VERSION ""

NS_ :

BS_:

BU_: VMCU TECU OBDScanT2 IC3 HPCU EMS ECUspare2 ECUspare1 DACU CIOM BBM

BO_ 2671835728 XCP_FA_50_BB2: 8 DACU
 SG_ XCP_FA_50 : 0|64@1+ (1,0) [0|0] "" Vector__XXX

BO_ 2671792378 XCP_50_FA_BB2: 8 Vector__XXX
 SG_ XCP_50_FA : 0|64@1+ (1,0) [0|0] ""  DACU

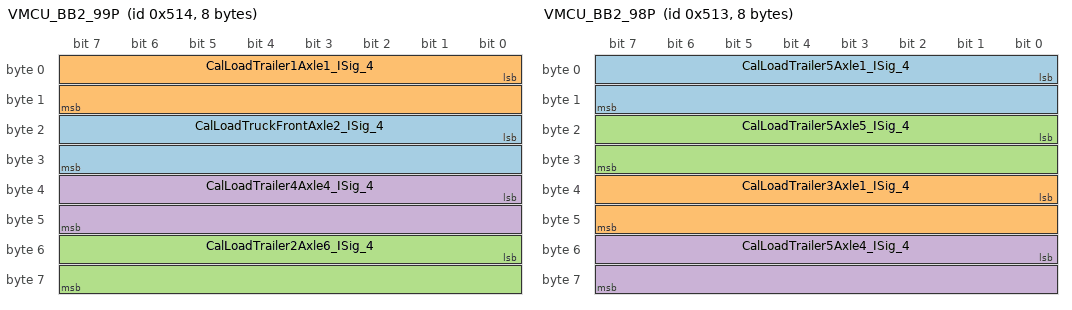
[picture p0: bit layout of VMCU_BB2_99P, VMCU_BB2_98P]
BO_ 1300 VMCU_BB2_99P: 8 VMCU
 SG_ CalLoadTruckFrontAxle2_ISig_4 : 16|16@1+ (0.5,0) [0|32767.5] "kg"  IC3,CIOM,BBM
 SG_ CalLoadTrailer1Axle1_ISig_4 : 0|16@1+ (0.5,0) [0|32767.5] "kg"  CIOM,BBM,IC3
 SG_ CalLoadTrailer2Axle6_ISig_4 : 48|16@1+ (0.5,0) [0|32767.5] "kg"  IC3,CIOM
 SG_ CalLoadTrailer4Axle4_ISig_4 : 32|16@1+ (0.5,0) [0|32767.5] "kg"  CIOM,IC3

BO_ 1299 VMCU_BB2_98P: 8 VMCU
 SG_ CalLoadTrailer5Axle1_ISig_4 : 0|16@1+ (0.5,0) [0|32767.5] "kg"  IC3,CIOM
 SG_ CalLoadTrailer3Axle1_ISig_4 : 32|16@1+ (0.5,0) [0|32767.5] "kg"  CIOM,IC3
 SG_ CalLoadTrailer5Axle5_ISig_4 : 16|16@1+ (0.5,0) [0|32767.5] "kg"  CIOM,IC3
 SG_ CalLoadTrailer5Axle4_ISig_4 : 48|16@1+ (0.5,0) [0|32767.5] "kg"  IC3,CIOM

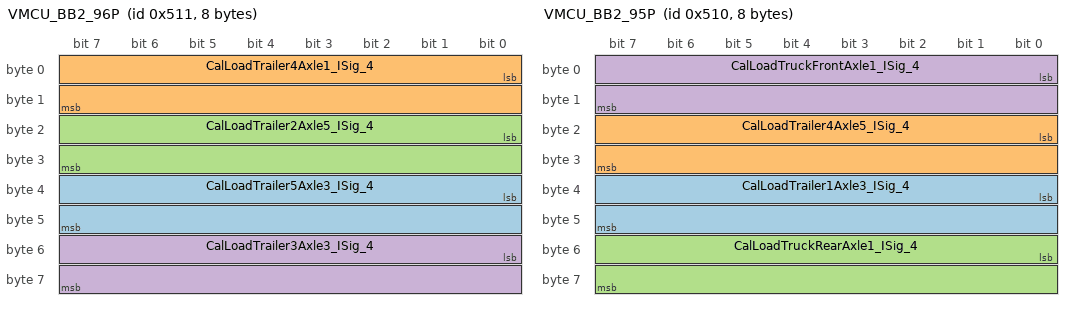
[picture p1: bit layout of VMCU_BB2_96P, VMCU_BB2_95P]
BO_ 1297 VMCU_BB2_96P: 8 VMCU
 SG_ CalLoadTrailer5Axle3_ISig_4 : 32|16@1+ (0.5,0) [0|32767.5] "kg"  CIOM,IC3
 SG_ CalLoadTrailer4Axle1_ISig_4 : 0|16@1+ (0.5,0) [0|32767.5] "kg"  CIOM,IC3
 SG_ CalLoadTrailer2Axle5_ISig_4 : 16|16@1+ (0.5,0) [0|32767.5] "kg"  CIOM,IC3
 SG_ CalLoadTrailer3Axle3_ISig_4 : 48|16@1+ (0.5,0) [0|32767.5] "kg"  CIOM,IC3

BO_ 1296 VMCU_BB2_95P: 8 VMCU
 SG_ CalLoadTrailer1Axle3_ISig_4 : 32|16@1+ (0.5,0) [0|32767.5] "kg"  IC3,BBM,CIOM
 SG_ CalLoadTrailer4Axle5_ISig_4 : 16|16@1+ (0.5,0) [0|32767.5] "kg"  IC3,CIOM
 SG_ CalLoadTruckRearAxle1_ISig_4 : 48|16@1+ (0.5,0) [0|32767.5] "kg"  CIOM,BBM,IC3
 SG_ CalLoadTruckFrontAxle1_ISig_4 : 0|16@1+ (0.5,0) [0|32767.5] "kg"  IC3,BBM,CIOM

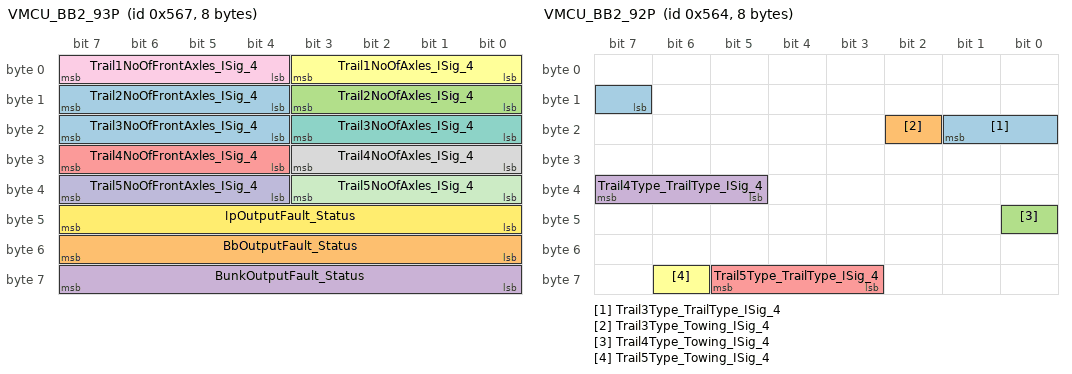
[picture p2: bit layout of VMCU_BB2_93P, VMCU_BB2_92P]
BO_ 1383 VMCU_BB2_93P: 8 VMCU
 SG_ Trail2NoOfFrontAxles_ISig_4 : 12|4@1+ (1,0) [0|15] "NotApplicable"  CIOM,IC3
 SG_ BbOutputFault_Status : 48|8@1+ (1,0) [0|255] ""  IC3
 SG_ Trail2NoOfAxles_ISig_4 : 8|4@1+ (1,0) [0|15] "NotApplicable"  IC3,CIOM
 SG_ BunkOutputFault_Status : 56|8@1+ (1,0) [0|255] ""  IC3
 SG_ Trail4NoOfFrontAxles_ISig_4 : 28|4@1+ (1,0) [0|15] "NotApplicable"  CIOM,IC3
 SG_ Trail1NoOfAxles_ISig_4 : 0|4@1+ (1,0) [0|15] "NotApplicable"  CIOM,IC3
 SG_ Trail3NoOfAxles_ISig_4 : 16|4@1+ (1,0) [0|15] "NotApplicable"  IC3,CIOM
 SG_ Trail4NoOfAxles_ISig_4 : 24|4@1+ (1,0) [0|15] "NotApplicable"  IC3,CIOM
 SG_ Trail1NoOfFrontAxles_ISig_4 : 4|4@1+ (1,0) [0|15] "NotApplicable"  IC3,CIOM
 SG_ Trail5NoOfFrontAxles_ISig_4 : 36|4@1+ (1,0) [0|15] "NotApplicable"  CIOM,IC3
 SG_ Trail5NoOfAxles_ISig_4 : 32|4@1+ (1,0) [0|15] "NotApplicable"  CIOM,IC3
 SG_ IpOutputFault_Status : 40|8@1+ (1,0) [0|255] ""  IC3
 SG_ Trail3NoOfFrontAxles_ISig_4 : 20|4@1+ (1,0) [0|15] "NotApplicable"  CIOM,IC3

BO_ 1380 VMCU_BB2_92P: 8 VMCU
 SG_ Trail3Type_TrailType_ISig_4 : 15|3@1+ (1,0) [0|0] ""  CIOM,IC3
 SG_ Trail3Type_Towing_ISig_4 : 18|1@1+ (1,0) [0|0] ""  CIOM,IC3
 SG_ Trail4Type_Towing_ISig_4 : 40|1@1+ (1,0) [0|0] ""  CIOM,IC3
 SG_ Trail4Type_TrailType_ISig_4 : 37|3@1+ (1,0) [0|0] ""  CIOM,IC3
 SG_ Trail5Type_TrailType_ISig_4 : 59|3@1+ (1,0) [0|0] ""  IC3,CIOM
 SG_ Trail5Type_Towing_ISig_4 : 62|1@1+ (1,0) [0|0] ""  IC3,CIOM

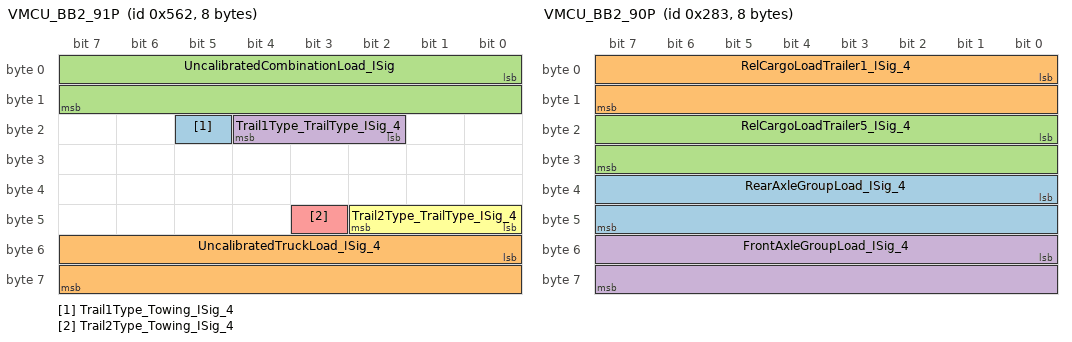
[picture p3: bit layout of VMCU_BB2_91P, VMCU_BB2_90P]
BO_ 1378 VMCU_BB2_91P: 8 VMCU
 SG_ Trail1Type_Towing_ISig_4 : 21|1@1+ (1,0) [0|0] ""  CIOM,IC3
 SG_ UncalibratedTruckLoad_ISig_4 : 48|16@1+ (2,0) [0|131070] "kg"  IC3
 SG_ UncalibratedCombinationLoad_ISig : 0|16@1+ (10,0) [0|655350] "kg"  IC3
 SG_ Trail1Type_TrailType_ISig_4 : 18|3@1+ (1,0) [0|0] ""  CIOM,IC3
 SG_ Trail2Type_Towing_ISig_4 : 43|1@1+ (1,0) [0|0] ""  CIOM,IC3
 SG_ Trail2Type_TrailType_ISig_4 : 40|3@1+ (1,0) [0|0] ""  CIOM,IC3

BO_ 643 VMCU_BB2_90P: 8 VMCU
 SG_ RearAxleGroupLoad_ISig_4 : 32|16@1+ (2,0) [0|131070] "kg"  IC3
 SG_ RelCargoLoadTrailer1_ISig_4 : 0|16@1+ (4,-128508) [-128508|133632] "kg"  BBM,IC3,CIOM
 SG_ RelCargoLoadTrailer5_ISig_4 : 16|16@1+ (4,-128508) [-128508|133632] "kg"  IC3,BBM,CIOM
 SG_ FrontAxleGroupLoad_ISig_4 : 48|16@1+ (2,0) [0|131070] "kg"  IC3

BO_ 533 VMCU_BB2_89P: 8 VMCU
 SG_ RelCargoLoadTrailer4_ISig_4 : 48|16@1+ (4,-128508) [-128508|133632] "kg"  IC3,CIOM,BBM

BO_ 421 VMCU_BB2_88P: 8 VMCU
 SG_ LNGConsumedVehicleStopped : 32|32@1+ (1,0) [0|4294967295] "kg"  IC3
 SG_ RelCargoLoadTruck_ISig_4 : 16|16@1+ (4,-128508) [-128508|133632] "kg"  CIOM,IC3,BBM

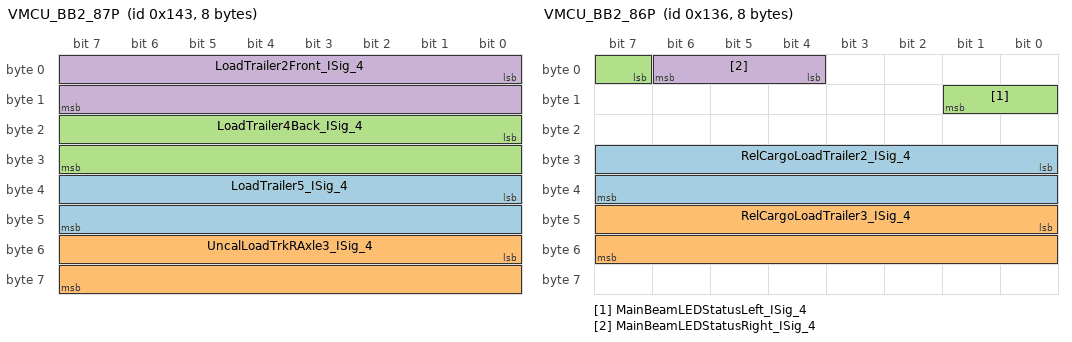
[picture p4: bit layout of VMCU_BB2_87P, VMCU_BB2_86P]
BO_ 323 VMCU_BB2_87P: 8 VMCU
 SG_ LoadTrailer5_ISig_4 : 32|16@1+ (2,0) [0|131070] "kg"  IC3,CIOM,BBM
 SG_ UncalLoadTrkRAxle3_ISig_4 : 48|16@1+ (0.5,0) [0|32767.5] "kg"  IC3
 SG_ LoadTrailer4Back_ISig_4 : 16|16@1+ (2,0) [0|131070] "kg"  IC3
 SG_ LoadTrailer2Front_ISig_4 : 0|16@1+ (2,0) [0|131070] "kg"  IC3

BO_ 310 VMCU_BB2_86P: 8 VMCU
 SG_ RelCargoLoadTrailer2_ISig_4 : 24|16@1+ (4,-128508) [-128508|133632] "kg"  IC3,BBM,CIOM
 SG_ RelCargoLoadTrailer3_ISig_4 : 40|16@1+ (4,-128508) [-128508|133632] "kg"  BBM,IC3,CIOM
 SG_ MainBeamLEDStatusLeft_ISig_4 : 7|3@1+ (1,0) [0|0] ""  IC3
 SG_ MainBeamLEDStatusRight_ISig_4 : 4|3@1+ (1,0) [0|0] ""  IC3

BO_ 1367 VMCU_BB2_85P: 8 VMCU
 SG_ DistanceToEmptyLNG_ISig_4 : 48|16@1+ (1,0) [0|65535] "km"  IC3
 SG_ DistanceToEmpty_Diesel_ISig_4 : 32|16@1+ (1,0) [0|65535] "km"  IC3

BO_ 1370 VMCU_BB2_83P: 8 VMCU
 SG_ Trailer1CalibrationType : 33|3@1+ (1,0) [0|0] ""  IC3
 SG_ FrontConspicLamp_stat_HiLeft_ISi : 6|3@1+ (1,0) [0|0] ""  IC3
 SG_ TrailerDirIndLeftOutputStat_ISig : 12|3@1+ (1,0) [0|0] ""  IC3
 SG_ JumpChargeInterface_stat_ISig_4 : 51|2@1+ (1,0) [0|0] ""  IC3
 SG_ TrailerPosLightLeftOutputStat_IS : 18|3@1+ (1,0) [0|0] ""  IC3
 SG_ TruckCalibrated : 48|3@1+ (1,0) [0|0] ""  IC3
 SG_ Trailer5CalibrationType : 45|3@1+ (1,0) [0|0] ""  IC3
 SG_ Trailer2CalibrationType : 36|3@1+ (1,0) [0|0] ""  IC3
 SG_ Trailer4CalibrationType : 42|3@1+ (1,0) [0|0] ""  IC3
 SG_ TrailerBrakeLightOutputStat_ISig : 24|3@1+ (1,0) [0|0] ""  IC3
 SG_ FrontConspicLamp_stat_LoRight_IS : 3|3@1+ (1,0) [0|0] ""  IC3
 SG_ FrontConspicLamp_stat_LoLeft_ISi : 9|3@1+ (1,0) [0|0] ""  IC3
 SG_ NumberOfSavedTrailers : 56|8@1+ (1,0) [0|0] ""  IC3
 SG_ TrailerDirIndRightOutputStat_ISi : 15|3@1+ (1,0) [0|0] ""  IC3
 SG_ TrailerPosLightRightOutputStat_I : 21|3@1+ (1,0) [0|0] ""  IC3
 SG_ Trailer3CalibrationType : 39|3@1+ (1,0) [0|0] ""  IC3
 SG_ FrontConspicLamp_stat_HiRight_IS : 0|3@1+ (1,0) [0|0] ""  IC3

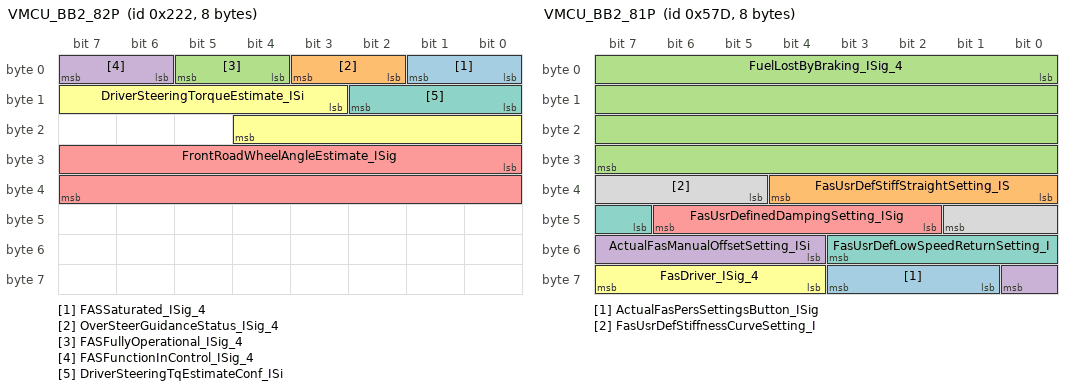
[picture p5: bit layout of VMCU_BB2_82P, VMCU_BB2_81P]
BO_ 546 VMCU_BB2_82P: 8 VMCU
 SG_ FASSaturated_ISig_4 : 0|2@1+ (1,0) [0|0] ""  DACU
 SG_ OverSteerGuidanceStatus_ISig_4 : 2|2@1+ (1,0) [0|0] ""  IC3
 SG_ FASFullyOperational_ISig_4 : 4|2@1+ (1,0) [0|0] ""  DACU,BBM
 SG_ FASFunctionInControl_ISig_4 : 6|2@1+ (1,0) [0|0] ""  DACU
 SG_ FrontRoadWheelAngleEstimate_ISig : 24|16@1+ (5E-005,-1.6) [-1.6|1.67675] "rad"  DACU,BBM
 SG_ DriverSteeringTorqueEstimate_ISi : 11|10@1+ (0.05,-25) [-25|26.15] "Nm"  DACU
 SG_ DriverSteeringTqEstimateConf_ISi : 8|3@1+ (1,0) [0|0] ""  DACU

BO_ 1405 VMCU_BB2_81P: 8 VMCU
 SG_ ActualFasPersSettingsButton_ISig : 57|3@1+ (1,0) [0|0] ""  IC3
 SG_ FasUsrDefStiffStraightSetting_IS : 32|5@1+ (1,-10) [-10|21] ""  IC3
 SG_ FuelLostByBraking_ISig_4 : 0|32@1+ (0.01,0) [0|42949672.95] "l"  IC3
 SG_ ActualFasManualOffsetSetting_ISi : 52|5@1+ (1,-10) [-10|21] ""  IC3
 SG_ FasUsrDefinedDampingSetting_ISig : 42|5@1+ (1,-10) [-10|21] ""  IC3
 SG_ FasDriver_ISig_4 : 60|4@1+ (1,0) [0|0] ""  IC3
 SG_ FasUsrDefLowSpeedReturnSetting_I : 47|5@1+ (1,-10) [-10|21] ""  IC3
 SG_ FasUsrDefStiffnessCurveSetting_I : 37|5@1+ (1,-10) [-10|21] ""  IC3

BO_ 830 VMCU_BB2_80P: 8 VMCU
 SG_ PS_PosLightDoorOpen : 10|2@1+ (1,0) [0|0] ""  IC3
 SG_ PS_FogLightRear : 24|2@1+ (1,0) [0|0] ""  IC3
 SG_ TrailerBodyLampDI_stat : 2|2@1+ (1,0) [0|0] ""  CIOM
 SG_ PV_HeadLightLevel : 16|4@1+ (1,-7) [-7|8] "NotApplicable"  IC3
 SG_ TrailerBodyLampFdbk_stat : 0|2@1+ (1,0) [0|0] ""  CIOM
 SG_ PS_FogLightFront : 26|2@1+ (1,0) [0|0] ""  IC3
 SG_ Alcolock_PBReleaseInhibit_ind : 61|3@1+ (1,0) [0|0] ""  IC3
 SG_ DHCNotificationReq : 55|4@1+ (1,0) [0|0] ""  IC3
 SG_ DriverCrank_rqst : 12|2@1+ (1,0) [0|0] ""  IC3
 SG_ PS_HeadLightAdjustment : 8|2@1+ (1,0) [0|0] ""  IC3
 SG_ PS_MainBeam : 14|2@1+ (1,0) [0|0] ""  IC3
 SG_ InstFuel_ConsumpValue : 28|16@1+ (0.01,0) [0|655.35] ""  IC3
 SG_ InstFuel_VehicleMoving : 44|2@1+ (1,0) [0|0] ""  IC3
 SG_ PS_AFSAllowed_ISig_4 : 49|2@1+ (1,0) [0|0] ""  IC3
 SG_ PS_AFS : 46|3@1+ (1,0) [0|0] ""  IC3
 SG_ AC2CoolingFanControl_rqst : 4|2@1+ (1,0) [0|0] ""  CIOM
 SG_ DHCStatus : 53|2@1+ (1,0) [0|0] ""  IC3
 SG_ PS_PositionLight : 51|2@1+ (1,0) [0|0] ""  IC3

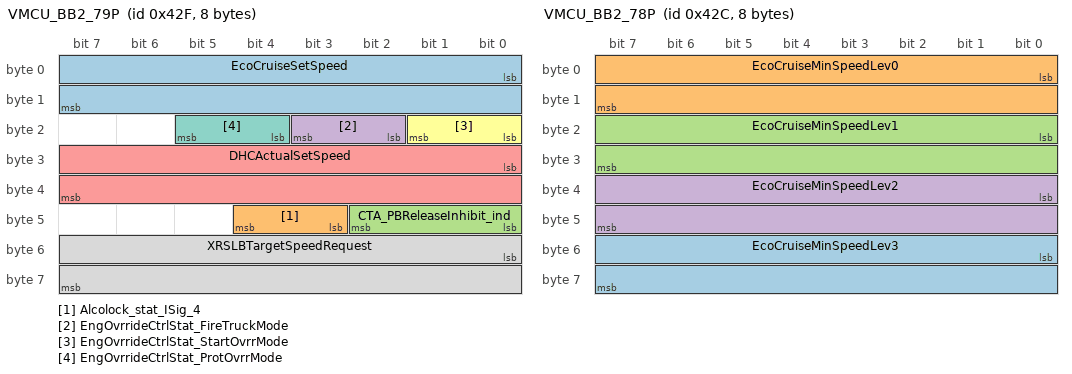
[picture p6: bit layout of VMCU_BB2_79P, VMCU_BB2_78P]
BO_ 1071 VMCU_BB2_79P: 8 VMCU
 SG_ EcoCruiseSetSpeed : 0|16@1+ (0.00390625,0) [0|255.99609375] "Km_per_h"  IC3
 SG_ Alcolock_stat_ISig_4 : 43|2@1+ (1,0) [0|0] ""  BBM
 SG_ CTA_PBReleaseInhibit_ind : 40|3@1+ (1,0) [0|0] ""  IC3,BBM
 SG_ EngOvrrideCtrlStat_FireTruckMode : 18|2@1+ (1,0) [0|0] ""  EMS
 SG_ DHCActualSetSpeed : 24|16@1+ (0.00390625,0) [0|255.99609375] "Km_per_h"  IC3
 SG_ EngOvrrideCtrlStat_StartOvrrMode : 16|2@1+ (1,0) [0|0] ""  EMS
 SG_ EngOvrrideCtrlStat_ProtOvrrMode : 20|2@1+ (1,0) [0|0] ""  EMS
 SG_ XRSLBTargetSpeedRequest : 48|16@1+ (0.00390625,0) [0|255.99609375] "Km_per_h"  TECU,EMS

BO_ 1068 VMCU_BB2_78P: 8 VMCU
 SG_ EcoCruiseMinSpeedLev3 : 48|16@1+ (0.00390625,0) [0|255.99609375] "Km_per_h"  IC3
 SG_ EcoCruiseMinSpeedLev0 : 0|16@1+ (0.00390625,0) [0|255.99609375] "Km_per_h"  IC3
 SG_ EcoCruiseMinSpeedLev1 : 16|16@1+ (0.00390625,0) [0|255.99609375] "Km_per_h"  IC3
 SG_ EcoCruiseMinSpeedLev2 : 32|16@1+ (0.00390625,0) [0|255.99609375] "Km_per_h"  IC3

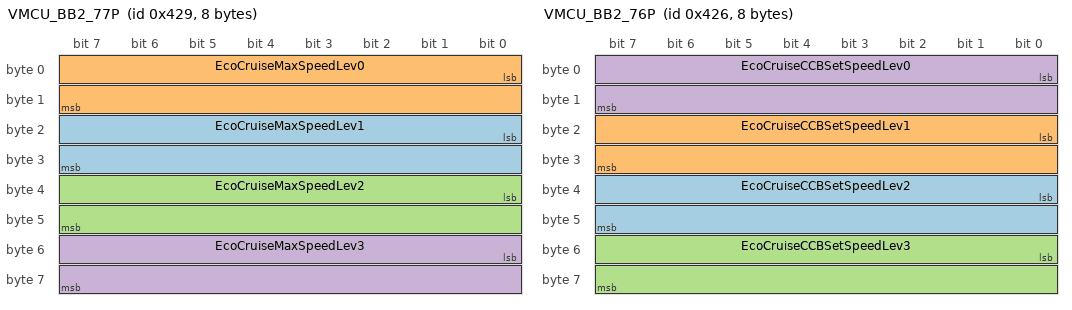
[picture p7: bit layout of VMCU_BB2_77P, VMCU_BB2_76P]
BO_ 1065 VMCU_BB2_77P: 8 VMCU
 SG_ EcoCruiseMaxSpeedLev1 : 16|16@1+ (0.00390625,0) [0|255.99609375] "Km_per_h"  IC3
 SG_ EcoCruiseMaxSpeedLev0 : 0|16@1+ (0.00390625,0) [0|255.99609375] "Km_per_h"  IC3
 SG_ EcoCruiseMaxSpeedLev2 : 32|16@1+ (0.00390625,0) [0|255.99609375] "Km_per_h"  IC3
 SG_ EcoCruiseMaxSpeedLev3 : 48|16@1+ (0.00390625,0) [0|255.99609375] "Km_per_h"  IC3

BO_ 1062 VMCU_BB2_76P: 8 VMCU
 SG_ EcoCruiseCCBSetSpeedLev2 : 32|16@1+ (0.00390625,0) [0|255.99609375] "Km_per_h"  IC3
 SG_ EcoCruiseCCBSetSpeedLev1 : 16|16@1+ (0.00390625,0) [0|255.99609375] "Km_per_h"  IC3
 SG_ EcoCruiseCCBSetSpeedLev3 : 48|16@1+ (0.00390625,0) [0|255.99609375] "Km_per_h"  IC3
 SG_ EcoCruiseCCBSetSpeedLev0 : 0|16@1+ (0.00390625,0) [0|255.99609375] "Km_per_h"  IC3

BO_ 1404 VMCU_BB2_75P: 8 VMCU
 SG_ EngineGreenAreaOutLNG_ISig_4 : 32|32@1+ (0.01,0) [0|42949672.95] "kg"  IC3
 SG_ EngineGreenAreaLNG_ISig_4 : 0|32@1+ (0.01,0) [0|42949672.95] "kg"  IC3

BO_ 1035 VMCU_BB2_74P: 8 VMCU
 SG_ BatteryTempAlert_rqst_ISig_4 : 4|3@1+ (1,0) [0|0] ""  IC3
 SG_ APM_TrailerCircPressureStatus_IS : 52|2@1+ (1,0) [0|0] ""  IC3
 SG_ BatteryCapacity_ISig_4 : 0|4@1+ (1,0) [0|0] ""  IC3
 SG_ Hazard_rqst_ISig_4 : 54|2@1+ (1,0) [0|0] ""  DACU,IC3
 SG_ CollisionSituationAliveStatus : 44|4@1+ (1,0) [0|15] "Count"  DACU
 SG_ BatterySOCact_ISig_4 : 8|8@1+ (0.5,0) [0|127.5] "Percent"  IC3
 SG_ Trailer1TPMLostCom_ISig_4 : 35|2@1+ (1,0) [0|0] ""  IC3
 SG_ BatterySOCactCriticalAlert_ISig_ : 16|8@1+ (0.5,0) [0|127.5] "Percent"  IC3
 SG_ BatteryTempAlertRawData_rqst_ISi : 32|3@1+ (1,0) [0|0] ""  IC3
 SG_ FPBRMMIStat_FPBRChangeAck_ISig_4 : 50|2@1+ (1,0) [0|0] ""  CIOM
 SG_ Trailer2TPMLostCom_UB_ISig_4 : 39|1@1+ (1,0) [0|0] ""  IC3
 SG_ LivBatteryCharging_stat_ISig_4 : 56|2@1+ (1,0) [0|0] ""  CIOM
 SG_ BatteryTemp_ISig_4 : 24|8@1+ (1,-45) [-45|210] "DegreeC"  IC3
 SG_ Trailer1TPMLostCom_UB_ISig_4 : 7|1@1+ (1,0) [0|0] ""  IC3
 SG_ FPBRMMIStat_FPBRStatusInd_ISig_4 : 48|2@1+ (1,0) [0|0] ""  CIOM
 SG_ RS_WasherStatus_ISig_4 : 60|2@1+ (1,0) [0|0] ""  DACU
 SG_ Trailer2TPMLostCom_ISig_4 : 37|2@1+ (1,0) [0|0] ""  IC3
 SG_ Rainsensor_Indication_ISig_4 : 58|2@1+ (1,0) [0|0] ""  IC3
 SG_ CollisionSituationAliveRequest : 40|4@1+ (1,0) [0|15] "Count"  DACU

BO_ 1032 VMCU_BB2_73P: 8 VMCU
 SG_ TPMMateTrailerResp_ISig_4 : 32|3@1+ (1,0) [0|0] ""  IC3
 SG_ Trailer2TPMLeakageWarning_ISig_4 : 19|3@1+ (1,0) [0|0] ""  IC3
 SG_ TPMAutomaticMating_ISig_4 : 30|2@1+ (1,0) [0|0] ""  IC3
 SG_ Trailer2TPMPressureWarning_UB_IS : 55|1@1+ (1,0) [0|0] ""  IC3
 SG_ DirectionIndicatorLightsStatus_I : 40|4@1+ (1,0) [0|0] ""  IC3
 SG_ FrontWheelDifflockRequest_ISig_4 : 44|2@1+ (1,0) [0|0] ""  IC3
 SG_ TruckTPMLeakageWarning_UB_ISig_4 : 56|1@1+ (1,0) [0|0] ""  IC3
 SG_ Trailer2TPMMatedStatus_ISig_4 : 14|2@1+ (1,0) [0|0] ""  IC3
 SG_ Trailer1TPMMatedStatus_ISig_4 : 22|2@1+ (1,0) [0|0] ""  IC3
 SG_ Trailer2TPMLeakageWarning_UB_ISi : 54|1@1+ (1,0) [0|0] ""  IC3
 SG_ CargoLoadResetFeedback : 48|2@1+ (1,0) [0|0] ""  IC3
 SG_ Trailer1TPMLeakageWarning_UB_ISi : 52|1@1+ (1,0) [0|0] ""  IC3
 SG_ TruckTPMLeakageWarning_ISig_4 : 11|3@1+ (1,0) [0|0] ""  IC3
 SG_ Trailer1TPMPressureWarning_UB_IS : 53|1@1+ (1,0) [0|0] ""  IC3
 SG_ ExtraSideMarkers_FunctStat : 58|2@1+ (1,0) [0|0] ""  CIOM
 SG_ TruckTPMPressureWarning_UB_ISig_ : 57|1@1+ (1,0) [0|0] ""  IC3
 SG_ Trailer2TPMPressureWarning_ISig_ : 16|3@1+ (1,0) [0|0] ""  IC3
 SG_ XRSLActive : 46|2@1+ (1,0) [0|0] ""  IC3
 SG_ Trailer1TPMPressureWarning_ISig_ : 24|3@1+ (1,0) [0|0] ""  IC3
 SG_ Trailer1TPMLeakageWarning_ISig_4 : 27|3@1+ (1,0) [0|0] ""  IC3
 SG_ LiftAxle1RequestResponse : 35|4@1+ (1,0) [0|0] ""  IC3
 SG_ TruckTPMPressureWarning_ISig_4 : 8|3@1+ (1,0) [0|0] ""  IC3
 SG_ XRSLIndication : 0|8@1+ (1,0) [0|255] "Km_per_h"  BBM,IC3
 SG_ TPMMateTrailerResp_UB_ISig_4 : 39|1@1+ (1,0) [0|0] ""  IC3

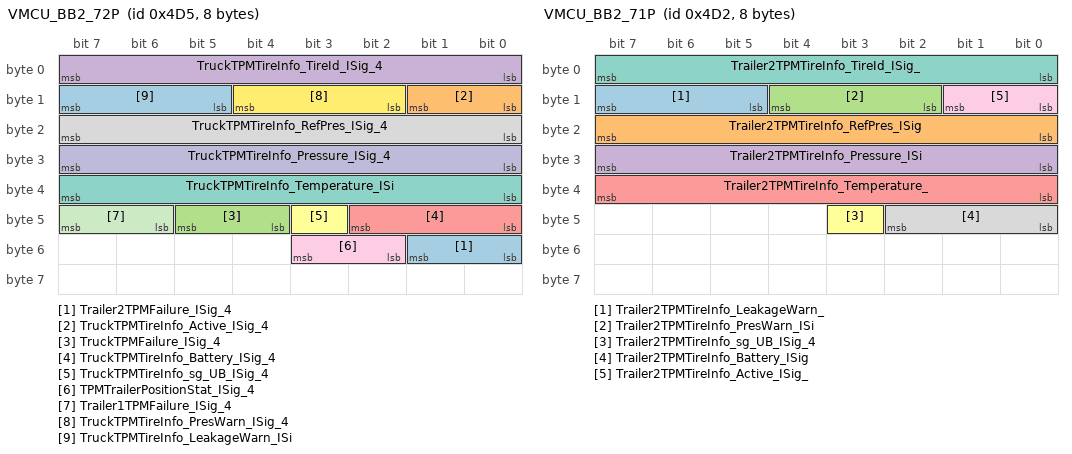
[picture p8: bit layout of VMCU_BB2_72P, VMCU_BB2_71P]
BO_ 1237 VMCU_BB2_72P: 8 VMCU
 SG_ Trailer2TPMFailure_ISig_4 : 48|2@1+ (1,0) [0|0] ""  IC3
 SG_ TruckTPMTireInfo_Active_ISig_4 : 8|2@1+ (1,0) [0|0] ""  IC3
 SG_ TruckTPMFailure_ISig_4 : 44|2@1+ (1,0) [0|0] ""  IC3
 SG_ TruckTPMTireInfo_TireId_ISig_4 : 0|8@1+ (1,0) [0|255] "NotApplicable"  IC3
 SG_ TruckTPMTireInfo_Battery_ISig_4 : 40|3@1+ (1,0) [0|0] ""  IC3
 SG_ TruckTPMTireInfo_sg_UB_ISig_4 : 43|1@1+ (1,0) [0|0] ""  IC3
 SG_ TruckTPMTireInfo_Temperature_ISi : 32|8@1+ (1,-50) [-50|205] "DegreeC"  IC3
 SG_ TruckTPMTireInfo_RefPres_ISig_4 : 16|8@1+ (10,0) [0|2550] "kPa"  IC3
 SG_ TPMTrailerPositionStat_ISig_4 : 50|2@1+ (1,0) [0|0] ""  IC3
 SG_ TruckTPMTireInfo_Pressure_ISig_4 : 24|8@1+ (10,0) [0|2550] "kPa"  IC3
 SG_ Trailer1TPMFailure_ISig_4 : 46|2@1+ (1,0) [0|0] ""  IC3
 SG_ TruckTPMTireInfo_PresWarn_ISig_4 : 10|3@1+ (1,0) [0|0] ""  IC3
 SG_ TruckTPMTireInfo_LeakageWarn_ISi : 13|3@1+ (1,0) [0|0] ""  IC3

BO_ 1234 VMCU_BB2_71P: 8 VMCU
 SG_ Trailer2TPMTireInfo_LeakageWarn_ : 13|3@1+ (1,0) [0|0] ""  IC3
 SG_ Trailer2TPMTireInfo_RefPres_ISig : 16|8@1+ (10,0) [0|2550] "kPa"  IC3
 SG_ Trailer2TPMTireInfo_PresWarn_ISi : 10|3@1+ (1,0) [0|0] ""  IC3
 SG_ Trailer2TPMTireInfo_Pressure_ISi : 24|8@1+ (10,0) [0|2550] "kPa"  IC3
 SG_ Trailer2TPMTireInfo_Temperature_ : 32|8@1+ (1,-50) [-50|205] "DegreeC"  IC3
 SG_ Trailer2TPMTireInfo_sg_UB_ISig_4 : 43|1@1+ (1,0) [0|0] ""  IC3
 SG_ Trailer2TPMTireInfo_TireId_ISig_ : 0|8@1+ (1,0) [0|255] "NotApplicable"  IC3
 SG_ Trailer2TPMTireInfo_Battery_ISig : 40|3@1+ (1,0) [0|0] ""  IC3
 SG_ Trailer2TPMTireInfo_Active_ISig_ : 8|2@1+ (1,0) [0|0] ""  IC3

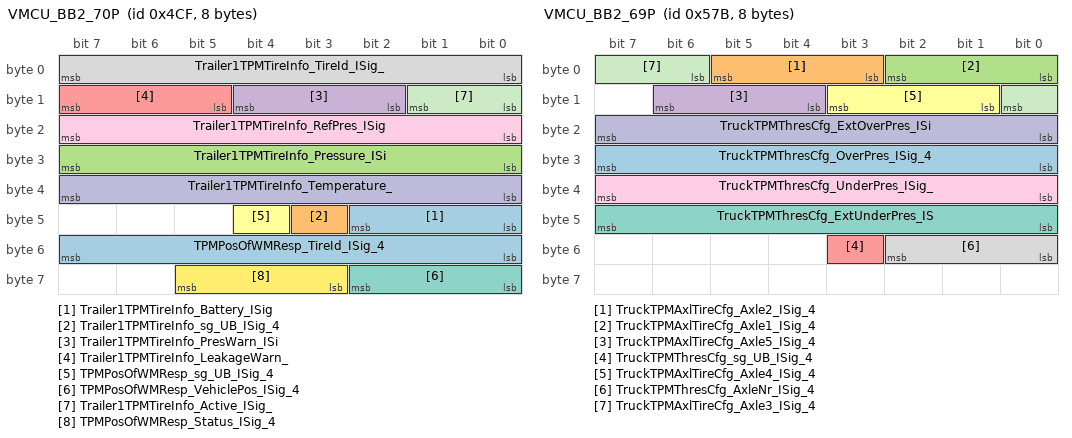
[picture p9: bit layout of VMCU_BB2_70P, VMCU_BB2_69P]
BO_ 1231 VMCU_BB2_70P: 8 VMCU
 SG_ Trailer1TPMTireInfo_Battery_ISig : 40|3@1+ (1,0) [0|0] ""  IC3
 SG_ Trailer1TPMTireInfo_sg_UB_ISig_4 : 43|1@1+ (1,0) [0|0] ""  IC3
 SG_ Trailer1TPMTireInfo_Pressure_ISi : 24|8@1+ (10,0) [0|2550] "kPa"  IC3
 SG_ Trailer1TPMTireInfo_PresWarn_ISi : 10|3@1+ (1,0) [0|0] ""  IC3
 SG_ Trailer1TPMTireInfo_LeakageWarn_ : 13|3@1+ (1,0) [0|0] ""  IC3
 SG_ TPMPosOfWMResp_sg_UB_ISig_4 : 44|1@1+ (1,0) [0|0] ""  IC3
 SG_ TPMPosOfWMResp_VehiclePos_ISig_4 : 56|3@1+ (1,0) [0|0] ""  IC3
 SG_ Trailer1TPMTireInfo_TireId_ISig_ : 0|8@1+ (1,0) [0|255] "NotApplicable"  IC3
 SG_ Trailer1TPMTireInfo_RefPres_ISig : 16|8@1+ (10,0) [0|2550] "kPa"  IC3
 SG_ Trailer1TPMTireInfo_Temperature_ : 32|8@1+ (1,-50) [-50|205] "DegreeC"  IC3
 SG_ Trailer1TPMTireInfo_Active_ISig_ : 8|2@1+ (1,0) [0|0] ""  IC3
 SG_ TPMPosOfWMResp_Status_ISig_4 : 59|3@1+ (1,0) [0|0] ""  IC3
 SG_ TPMPosOfWMResp_TireId_ISig_4 : 48|8@1+ (1,0) [0|255] "NotApplicable"  IC3

BO_ 1403 VMCU_BB2_69P: 8 VMCU
 SG_ TruckTPMThresCfg_OverPres_ISig_4 : 24|8@1+ (1,-125) [-125|130] "Percent"  IC3
 SG_ TruckTPMAxlTireCfg_Axle2_ISig_4 : 3|3@1+ (1,0) [0|0] ""  IC3
 SG_ TruckTPMAxlTireCfg_Axle1_ISig_4 : 0|3@1+ (1,0) [0|0] ""  IC3
 SG_ TruckTPMAxlTireCfg_Axle5_ISig_4 : 12|3@1+ (1,0) [0|0] ""  IC3
 SG_ TruckTPMThresCfg_sg_UB_ISig_4 : 51|1@1+ (1,0) [0|0] ""  IC3
 SG_ TruckTPMAxlTireCfg_Axle4_ISig_4 : 9|3@1+ (1,0) [0|0] ""  IC3
 SG_ TruckTPMThresCfg_ExtUnderPres_IS : 40|8@1+ (1,-125) [-125|130] "Percent"  IC3
 SG_ TruckTPMThresCfg_AxleNr_ISig_4 : 48|3@1+ (1,0) [0|0] ""  IC3
 SG_ TruckTPMThresCfg_UnderPres_ISig_ : 32|8@1+ (1,-125) [-125|130] "Percent"  IC3
 SG_ TruckTPMThresCfg_ExtOverPres_ISi : 16|8@1+ (1,-125) [-125|130] "Percent"  IC3
 SG_ TruckTPMAxlTireCfg_Axle3_ISig_4 : 6|3@1+ (1,0) [0|0] ""  IC3

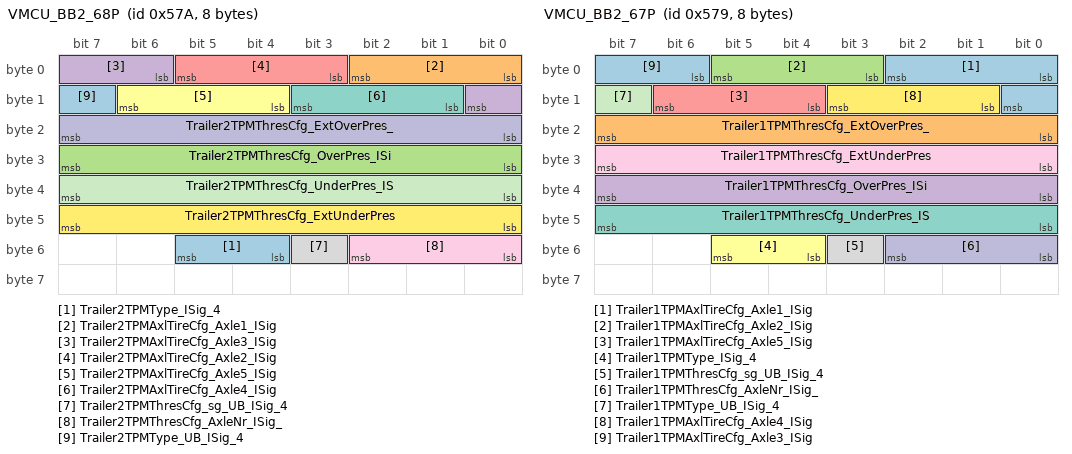
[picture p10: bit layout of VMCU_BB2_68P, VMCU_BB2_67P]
BO_ 1402 VMCU_BB2_68P: 8 VMCU
 SG_ Trailer2TPMType_ISig_4 : 52|2@1+ (1,0) [0|0] ""  IC3
 SG_ Trailer2TPMAxlTireCfg_Axle1_ISig : 0|3@1+ (1,0) [0|0] ""  IC3
 SG_ Trailer2TPMThresCfg_OverPres_ISi : 24|8@1+ (1,-125) [-125|130] "Percent"  IC3
 SG_ Trailer2TPMAxlTireCfg_Axle3_ISig : 6|3@1+ (1,0) [0|0] ""  IC3
 SG_ Trailer2TPMAxlTireCfg_Axle2_ISig : 3|3@1+ (1,0) [0|0] ""  IC3
 SG_ Trailer2TPMAxlTireCfg_Axle5_ISig : 12|3@1+ (1,0) [0|0] ""  IC3
 SG_ Trailer2TPMAxlTireCfg_Axle4_ISig : 9|3@1+ (1,0) [0|0] ""  IC3
 SG_ Trailer2TPMThresCfg_sg_UB_ISig_4 : 51|1@1+ (1,0) [0|0] ""  IC3
 SG_ Trailer2TPMThresCfg_AxleNr_ISig_ : 48|3@1+ (1,0) [0|0] ""  IC3
 SG_ Trailer2TPMThresCfg_ExtOverPres_ : 16|8@1+ (1,-125) [-125|130] "Percent"  IC3
 SG_ Trailer2TPMThresCfg_UnderPres_IS : 32|8@1+ (1,-125) [-125|130] "Percent"  IC3
 SG_ Trailer2TPMThresCfg_ExtUnderPres : 40|8@1+ (1,-125) [-125|130] "Percent"  IC3
 SG_ Trailer2TPMType_UB_ISig_4 : 15|1@1+ (1,0) [0|0] ""  IC3

BO_ 1401 VMCU_BB2_67P: 8 VMCU
 SG_ Trailer1TPMAxlTireCfg_Axle1_ISig : 0|3@1+ (1,0) [0|0] ""  IC3
 SG_ Trailer1TPMThresCfg_ExtOverPres_ : 16|8@1+ (1,-125) [-125|130] "Percent"  IC3
 SG_ Trailer1TPMAxlTireCfg_Axle2_ISig : 3|3@1+ (1,0) [0|0] ""  IC3
 SG_ Trailer1TPMThresCfg_OverPres_ISi : 32|8@1+ (1,-125) [-125|130] "Percent"  IC3
 SG_ Trailer1TPMAxlTireCfg_Axle5_ISig : 12|3@1+ (1,0) [0|0] ""  IC3
 SG_ Trailer1TPMType_ISig_4 : 52|2@1+ (1,0) [0|0] ""  IC3
 SG_ Trailer1TPMThresCfg_UnderPres_IS : 40|8@1+ (1,-125) [-125|130] "Percent"  IC3
 SG_ Trailer1TPMThresCfg_sg_UB_ISig_4 : 51|1@1+ (1,0) [0|0] ""  IC3
 SG_ Trailer1TPMThresCfg_ExtUnderPres : 24|8@1+ (1,-125) [-125|130] "Percent"  IC3
 SG_ Trailer1TPMThresCfg_AxleNr_ISig_ : 48|3@1+ (1,0) [0|0] ""  IC3
 SG_ Trailer1TPMType_UB_ISig_4 : 15|1@1+ (1,0) [0|0] ""  IC3
 SG_ Trailer1TPMAxlTireCfg_Axle4_ISig : 9|3@1+ (1,0) [0|0] ""  IC3
 SG_ Trailer1TPMAxlTireCfg_Axle3_ISig : 6|3@1+ (1,0) [0|0] ""  IC3

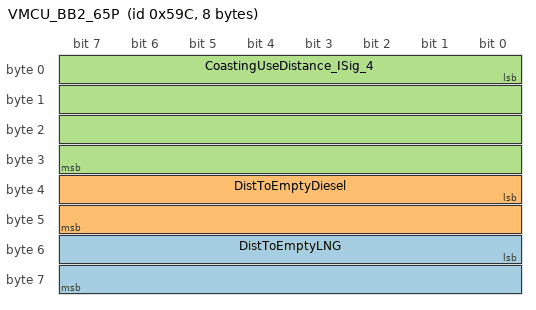
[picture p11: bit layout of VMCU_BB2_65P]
BO_ 1436 VMCU_BB2_65P: 8 VMCU
 SG_ DistToEmptyLNG : 48|16@1+ (1,0) [0|65535] "km"  IC3
 SG_ DistToEmptyDiesel : 32|16@1+ (1,0) [0|65535] "km"  IC3
 SG_ CoastingUseDistance_ISig_4 : 0|32@1+ (10,0) [0|42949672950] "m"  IC3

CM_ "COM_MATRIX_T2_1.16.0";
CM_ SG_ 1300 CalLoadTruckFrontAxle2_ISig_4 "65024 - 65279 Error ; 65280 - 65535 Not available";
CM_ SG_ 1300 CalLoadTrailer1Axle1_ISig_4 "65024 - 65279 Error ; 65280 - 65535 Not available";
CM_ SG_ 1300 CalLoadTrailer2Axle6_ISig_4 "65024 - 65279 Error ; 65280 - 65535 Not available";
CM_ SG_ 1300 CalLoadTrailer4Axle4_ISig_4 "65024 - 65279 Error ; 65280 - 65535 Not available";
CM_ SG_ 1299 CalLoadTrailer5Axle1_ISig_4 "65024 - 65279 Error ; 65280 - 65535 Not available";
CM_ SG_ 1299 CalLoadTrailer3Axle1_ISig_4 "65024 - 65279 Error ; 65280 - 65535 Not available";
CM_ SG_ 1299 CalLoadTrailer5Axle5_ISig_4 "65024 - 65279 Error ; 65280 - 65535 Not available";
CM_ SG_ 1299 CalLoadTrailer5Axle4_ISig_4 "65024 - 65279 Error ; 65280 - 65535 Not available";
CM_ SG_ 1297 CalLoadTrailer5Axle3_ISig_4 "65024 - 65279 Error ; 65280 - 65535 Not available";
CM_ SG_ 1297 CalLoadTrailer4Axle1_ISig_4 "65024 - 65279 Error ; 65280 - 65535 Not available";
CM_ SG_ 1297 CalLoadTrailer2Axle5_ISig_4 "65024 - 65279 Error ; 65280 - 65535 Not available";
CM_ SG_ 1297 CalLoadTrailer3Axle3_ISig_4 "65024 - 65279 Error ; 65280 - 65535 Not available";
CM_ SG_ 1296 CalLoadTrailer1Axle3_ISig_4 "65024 - 65279 Error ; 65280 - 65535 Not available";
CM_ SG_ 1296 CalLoadTrailer4Axle5_ISig_4 "65024 - 65279 Error ; 65280 - 65535 Not available";
CM_ SG_ 1296 CalLoadTruckRearAxle1_ISig_4 "65024 - 65279 Error ; 65280 - 65535 Not available";
CM_ SG_ 1296 CalLoadTruckFrontAxle1_ISig_4 "65024 - 65279 Error ; 65280 - 65535 Not available";
CM_ SG_ 1383 Trail2NoOfFrontAxles_ISig_4 "15 Not available";
CM_ SG_ 1383 Trail2NoOfAxles_ISig_4 "15 Not available";
CM_ SG_ 1383 Trail4NoOfFrontAxles_ISig_4 "15 Not available";
CM_ SG_ 1383 Trail1NoOfAxles_ISig_4 "15 Not available";
CM_ SG_ 1383 Trail3NoOfAxles_ISig_4 "15 Not available";
CM_ SG_ 1383 Trail4NoOfAxles_ISig_4 "15 Not available";
CM_ SG_ 1383 Trail1NoOfFrontAxles_ISig_4 "15 Not available";
CM_ SG_ 1383 Trail5NoOfFrontAxles_ISig_4 "15 Not available";
CM_ SG_ 1383 Trail5NoOfAxles_ISig_4 "15 Not available";
CM_ SG_ 1383 Trail3NoOfFrontAxles_ISig_4 "15 Not available";
CM_ SG_ 643 FrontAxleGroupLoad_ISig_4 "65024 - 65279 Error ; 65280 - 65535 Not available";
CM_ SG_ 323 LoadTrailer5_ISig_4 "65024 - 65279 Error ; 65280 - 65535 Not Available";
CM_ SG_ 1367 DistanceToEmptyLNG_ISig_4 "10000-65023 Spare; 65024-65279 Error; 65280-65535 NotAvailable;";
CM_ SG_ 1367 DistanceToEmpty_Diesel_ISig_4 "10000-65023 Spare; 65024-65279 Error; 65280-65535 NotAvailable;";
CM_ SG_ 1405 FasUsrDefStiffStraightSetting_IS "21-29 spare
30 Error
31 NotAvailbale";
CM_ SG_ 1405 FuelLostByBraking_ISig_4 "4261412864 - 4278190079 Error
4278190080 - 4294967295 NotAvailable";
CM_ SG_ 1405 FasUsrDefinedDampingSetting_ISig "21-29 spare
30 Error
31 NotAvailbale";
CM_ SG_ 1405 FasUsrDefLowSpeedReturnSetting_I "21-29 spare
30 Error
31 NotAvailbale";
CM_ SG_ 1405 FasUsrDefStiffnessCurveSetting_I "21-29 spare
30 Error
31 NotAvailbale";
CM_ SG_ 1404 EngineGreenAreaOutLNG_ISig_4 "4294967295 Not available
";
CM_ SG_ 1404 EngineGreenAreaLNG_ISig_4 "4211081216 - 4261412863 Spare
4261412864 - 4278190079 Error
4278190080 - 4294967295 NotAvailable";
CM_ SG_ 1237 TruckTPMTireInfo_Temperature_ISi "251-253	Spare; 254 Error; 255 NotAvailable;";
CM_ SG_ 1237 TruckTPMTireInfo_RefPres_ISig_4 "251-253 Spare; 254 Error; 255 NotAvailable;";
CM_ SG_ 1237 TruckTPMTireInfo_Pressure_ISig_4 "251-253 Spare; 254 Error; 255 NotAvailable;";
CM_ SG_ 1234 Trailer2TPMTireInfo_RefPres_ISig "251-253 Spare; 254 Error; 255 NotAvailable;";
CM_ SG_ 1234 Trailer2TPMTireInfo_Pressure_ISi "251-253 Spare; 254 Error; 255 NotAvailable;";
CM_ SG_ 1234 Trailer2TPMTireInfo_Temperature_ "251-253	Spare; 254 Error; 255 NotAvailable;";
CM_ SG_ 1231 Trailer1TPMTireInfo_Pressure_ISi "251-253 Spare; 254 Error; 255 NotAvailable;";
CM_ SG_ 1231 Trailer1TPMTireInfo_RefPres_ISig "251-253 Spare; 254 Error; 255 NotAvailable;";
CM_ SG_ 1231 Trailer1TPMTireInfo_Temperature_ "251-253	Spare; 254 Error; 255 NotAvailable;";
CM_ SG_ 1436 DistToEmptyLNG "10000-65023 Spare; 65024-65279 Error; 65280-65535 NotAvailable;";
CM_ SG_ 1436 DistToEmptyDiesel "10000-65023 Spare; 65024-65279 Error; 65280-65535 NotAvailable;";
CM_ SG_ 1436 CoastingUseDistance_ISig_4 "4261412864 - 4278190079 Error ; 4278190080 - 4294967295 Not available";
BA_DEF_ BO_  "GenMsgStartDelayTime" INT 0 0;
BA_DEF_ BO_  "GenMsgDelayTime" INT 0 0;
BA_DEF_ BO_  "GenMsgCycleTime" INT 0 0;
BA_DEF_ BO_  "GenMsgSendType" ENUM  "Cyclic","NotUsed","NotUsed","NotUsed","NotUsed","NotUsed","NotUsed","IfActive","NoMsgSendType","NotUsed";
BA_DEF_ SG_  "GenSigStartValue" INT 0 0;
BA_DEF_ SG_  "GenSigCycleTimeActive" INT 0 0;
BA_DEF_ SG_  "GenSigCycleTime" INT 0 0;
BA_DEF_ SG_  "GenSigSendType" ENUM  "Cyclic","OnWrite","OnWriteWithRepetition","OnChange","OnChangeWithRepetition","IfActive","IfActiveWithRepetition","NoSigSendType","NotUsed","NotUsed","NotUsed","NotUsed","NotUsed";
BA_DEF_  "Baudrate" INT 0 1000000;
BA_DEF_  "NmType" STRING ;
BA_DEF_  "Manufacturer" STRING ;
BA_DEF_  "VersionYear" INT 0 99;
BA_DEF_  "VersionNumber" INT 0 99;
BA_DEF_  "VersionMonth" INT 1 12;
BA_DEF_  "VersionDay" INT 1 31;
BA_DEF_ BO_  "VFrameFormat" ENUM  "StandardCAN","ExtendedCAN","reserved","J1939PG","reserved","reserved","reserved","reserved","reserved","reserved","reserved","reserved","reserved","reserved","StandardCAN_FD","ExtendedCAN_FD";
BA_DEF_ BU_  "TpOwnSystemEcuNumber" HEX 0 255;
BA_DEF_ SG_  "SigType" ENUM  "Default","Range","RangeSigned","ASCII","Discrete","Control","ReferencePGN","DTC","StringDelimiter","StringLength","StringLengthControl";
BA_DEF_ SG_  "SeToolVersion_SIGNAL" STRING ;
BA_DEF_ SG_  "SeToolUniqueID_SIGNAL" STRING ;
BA_DEF_ SG_  "SeToolOwnerSigGroup_SIGNAL" STRING ;
BA_DEF_ SG_  "SeToolOwnerSigGroupID_SIGNAL" STRING ;
BA_DEF_ SG_  "SeToolName_SIGNAL" STRING ;
BA_DEF_ SG_  "SeToolItemID_SIGNAL" STRING ;
BA_DEF_ SG_  "SeToolAncestorID_SIGNAL" STRING ;
BA_DEF_ SG_  "Platform_VMCU1_Sig" ENUM  "No","Yes";
BA_DEF_ SG_  "Platform_FactoryIf_Sig" ENUM  "No","Yes";
BA_DEF_ BU_  "NmStationAddress" INT 0 255;
BA_DEF_  "NmAsrWaitBusSleepTime" INT 0 65535;
BA_DEF_  "NmAsrTimeoutTime" INT 0 65535;
BA_DEF_  "NmAsrRepeatMessageTime" INT 0 65535;
BA_DEF_ BU_  "NmAsrNodeIdentifier" HEX 0 253;
BA_DEF_ BU_  "NmAsrNode" ENUM  "No","Yes";
BA_DEF_  "NmAsrMessageCount" INT 1 256;
BA_DEF_ BO_  "NmAsrMessage" ENUM  "No","Yes";
BA_DEF_  "NmAsrCanMsgCycleTime" INT 0 65535;
BA_DEF_  "NmAsrBaseAddress" HEX 0 536870911;
BA_DEF_ SG_  "NeedsUpdateBit" ENUM  "No","Yes";
BA_DEF_ SG_  "MmAnSignal" ENUM  "No","Yes";
BA_DEF_ BU_  "IsOBDrelevant" ENUM  "No","Yes";
BA_DEF_ SG_  "GenSigMaxLatency" INT 0 65535;
BA_DEF_ SG_  "GenSigILSupport" ENUM  "Yes","No";
BA_DEF_ BO_  "GenMsgILSupport" ENUM  "No","Yes";
BA_DEF_ BU_  "DiagnosticClientAddress" HEX 0 255;
BA_DEF_ BO_  "DiagUUDTResponse" ENUM  "No","Yes";
BA_DEF_ BO_  "DiagState" ENUM  "No","Yes";
BA_DEF_ BU_  "DiagRole" ENUM  "None","OBDTester","ExternalTester","InternalTester";
BA_DEF_ BO_  "DiagResponse" ENUM  "No","Yes";
BA_DEF_ BO_  "DiagRequest" ENUM  "No","Yes";
BA_DEF_ BO_  "DiagConnection" HEX 0 65535;
BA_DEF_  "DBName" STRING ;
BA_DEF_ BO_  "CanTpSTmin" INT 0 255;
BA_DEF_ BO_  "CanTpFcFrameId" HEX 0 2147483647;
BA_DEF_ BO_  "CanTpBs" INT 0 255;
BA_DEF_  "BusType" STRING ;
BA_DEF_ SG_  "SystemSignalLongSymbol" STRING ;
BA_DEF_REL_ BU_SG_REL_  "GenSigTimeoutTime" INT 0 65535;
BA_DEF_REL_ BU_SG_REL_  "GenSigFirstTimeoutTime" INT 0 65535;
BA_DEF_DEF_  "GenMsgStartDelayTime" 0;
BA_DEF_DEF_  "GenMsgDelayTime" 0;
BA_DEF_DEF_  "GenMsgCycleTime" 0;
BA_DEF_DEF_  "GenMsgSendType" "Cyclic";
BA_DEF_DEF_  "GenSigStartValue" 0;
BA_DEF_DEF_  "GenSigCycleTimeActive" 0;
BA_DEF_DEF_  "GenSigCycleTime" 0;
BA_DEF_DEF_  "GenSigSendType" "Cyclic";
BA_DEF_DEF_  "Baudrate" 500000;
BA_DEF_DEF_  "NmType" "";
BA_DEF_DEF_  "Manufacturer" "VOLVO_AB";
BA_DEF_DEF_  "VersionYear" 0;
BA_DEF_DEF_  "VersionNumber" 0;
BA_DEF_DEF_  "VersionMonth" 1;
BA_DEF_DEF_  "VersionDay" 1;
BA_DEF_DEF_  "VFrameFormat" "ExtendedCAN";
BA_DEF_DEF_  "TpOwnSystemEcuNumber" 0;
BA_DEF_DEF_  "SigType" "Default";
BA_DEF_DEF_  "SeToolVersion_SIGNAL" "";
BA_DEF_DEF_  "SeToolUniqueID_SIGNAL" "";
BA_DEF_DEF_  "SeToolOwnerSigGroup_SIGNAL" "";
BA_DEF_DEF_  "SeToolOwnerSigGroupID_SIGNAL" "";
BA_DEF_DEF_  "SeToolName_SIGNAL" "";
BA_DEF_DEF_  "SeToolItemID_SIGNAL" "";
BA_DEF_DEF_  "SeToolAncestorID_SIGNAL" "";
BA_DEF_DEF_  "Platform_VMCU1_Sig" "No";
BA_DEF_DEF_  "Platform_FactoryIf_Sig" "No";
BA_DEF_DEF_  "NmStationAddress" 254;
BA_DEF_DEF_  "NmAsrWaitBusSleepTime" 750;
BA_DEF_DEF_  "NmAsrTimeoutTime" 5000;
BA_DEF_DEF_  "NmAsrRepeatMessageTime" 300;
BA_DEF_DEF_  "NmAsrNodeIdentifier" 0;
BA_DEF_DEF_  "NmAsrNode" "Yes";
BA_DEF_DEF_  "NmAsrMessageCount" 256;
BA_DEF_DEF_  "NmAsrMessage" "No";
BA_DEF_DEF_  "NmAsrCanMsgCycleTime" 200;
BA_DEF_DEF_  "NmAsrBaseAddress" 486506496;
BA_DEF_DEF_  "NeedsUpdateBit" "No";
BA_DEF_DEF_  "MmAnSignal" "No";
BA_DEF_DEF_  "IsOBDrelevant" "No";
BA_DEF_DEF_  "GenSigMaxLatency" 0;
BA_DEF_DEF_  "GenSigILSupport" "Yes";
BA_DEF_DEF_  "GenMsgILSupport" "Yes";
BA_DEF_DEF_  "DiagnosticClientAddress" 0;
BA_DEF_DEF_  "DiagUUDTResponse" "No";
BA_DEF_DEF_  "DiagState" "No";
BA_DEF_DEF_  "DiagRole" "None";
BA_DEF_DEF_  "DiagResponse" "No";
BA_DEF_DEF_  "DiagRequest" "No";
BA_DEF_DEF_  "DiagConnection" 0;
BA_DEF_DEF_  "DBName" "";
BA_DEF_DEF_  "CanTpSTmin" 0;
BA_DEF_DEF_  "CanTpFcFrameId" 2147483647;
BA_DEF_DEF_  "CanTpBs" 255;
BA_DEF_DEF_  "BusType" "";
BA_DEF_DEF_REL_ "GenSigTimeoutTime" 0;
BA_DEF_DEF_REL_ "GenSigFirstTimeoutTime" 0;
BA_DEF_DEF_  "SystemSignalLongSymbol" "";
BA_ "NmType" "NmAsr";
BA_ "BusType" "CAN";
BA_ "VersionDay" 23;
BA_ "VersionNumber" 1;
BA_ "VersionYear" 20;
BA_ "DBName" "Backbone2";
BA_ "IsOBDrelevant" BU_ VMCU 1;
BA_ "TpOwnSystemEcuNumber" BU_ VMCU 36;
BA_ "NmAsrNodeIdentifier" BU_ VMCU 36;
BA_ "TpOwnSystemEcuNumber" BU_ TECU 24;
BA_ "NmAsrNodeIdentifier" BU_ TECU 24;
BA_ "DiagRole" BU_ IC3 3;
BA_ "DiagnosticClientAddress" BU_ IC3 243;
BA_ "TpOwnSystemEcuNumber" BU_ IC3 97;
BA_ "NmAsrNodeIdentifier" BU_ IC3 96;
BA_ "TpOwnSystemEcuNumber" BU_ HPCU 239;
BA_ "NmAsrNodeIdentifier" BU_ HPCU 239;
BA_ "IsOBDrelevant" BU_ EMS 1;
BA_ "TpOwnSystemEcuNumber" BU_ EMS 16;
BA_ "NmAsrNodeIdentifier" BU_ EMS 16;
BA_ "TpOwnSystemEcuNumber" BU_ DACU 80;
BA_ "NmAsrNodeIdentifier" BU_ DACU 80;
BA_ "TpOwnSystemEcuNumber" BU_ CIOM 64;
BA_ "NmAsrNodeIdentifier" BU_ CIOM 64;
BA_ "TpOwnSystemEcuNumber" BU_ BBM 230;
BA_ "NmAsrNodeIdentifier" BU_ BBM 230;
BA_ "GenMsgSendType" BO_ 2671835728 8;
BA_ "VFrameFormat" BO_ 1300 0;
BA_ "GenMsgCycleTime" BO_ 1300 1000;
BA_ "GenMsgStartDelayTime" BO_ 1300 95;
BA_ "VFrameFormat" BO_ 1299 0;
BA_ "GenMsgCycleTime" BO_ 1299 1000;
BA_ "GenMsgStartDelayTime" BO_ 1299 85;
BA_ "VFrameFormat" BO_ 1297 0;
BA_ "GenMsgCycleTime" BO_ 1297 1000;
BA_ "GenMsgStartDelayTime" BO_ 1297 60;
BA_ "VFrameFormat" BO_ 1296 0;
BA_ "GenMsgCycleTime" BO_ 1296 1000;
BA_ "GenMsgStartDelayTime" BO_ 1296 50;
BA_ "VFrameFormat" BO_ 1383 0;
BA_ "GenMsgCycleTime" BO_ 1383 1000;
BA_ "GenMsgStartDelayTime" BO_ 1383 150;
BA_ "VFrameFormat" BO_ 1380 0;
BA_ "GenMsgCycleTime" BO_ 1380 1000;
BA_ "GenMsgStartDelayTime" BO_ 1380 140;
BA_ "VFrameFormat" BO_ 1378 0;
BA_ "GenMsgCycleTime" BO_ 1378 1000;
BA_ "GenMsgStartDelayTime" BO_ 1378 130;
BA_ "VFrameFormat" BO_ 643 0;
BA_ "GenMsgCycleTime" BO_ 643 1000;
BA_ "GenMsgStartDelayTime" BO_ 643 135;
BA_ "VFrameFormat" BO_ 533 0;
BA_ "GenMsgCycleTime" BO_ 533 500;
BA_ "GenMsgStartDelayTime" BO_ 533 105;
BA_ "VFrameFormat" BO_ 421 0;
BA_ "GenMsgCycleTime" BO_ 421 500;
BA_ "GenMsgStartDelayTime" BO_ 421 90;
BA_ "VFrameFormat" BO_ 323 0;
BA_ "GenMsgCycleTime" BO_ 323 500;
BA_ "GenMsgStartDelayTime" BO_ 323 75;
BA_ "VFrameFormat" BO_ 310 0;
BA_ "GenMsgCycleTime" BO_ 310 500;
BA_ "GenMsgStartDelayTime" BO_ 310 50;
BA_ "VFrameFormat" BO_ 1367 0;
BA_ "GenMsgCycleTime" BO_ 1367 1000;
BA_ "GenMsgStartDelayTime" BO_ 1367 125;
BA_ "VFrameFormat" BO_ 1370 0;
BA_ "GenMsgCycleTime" BO_ 1370 250;
BA_ "GenMsgStartDelayTime" BO_ 1370 60;
BA_ "VFrameFormat" BO_ 546 0;
BA_ "GenMsgCycleTime" BO_ 546 20;
BA_ "GenMsgStartDelayTime" BO_ 546 10;
BA_ "VFrameFormat" BO_ 1405 0;
BA_ "GenMsgCycleTime" BO_ 1405 1000;
BA_ "GenMsgStartDelayTime" BO_ 1405 25;
BA_ "VFrameFormat" BO_ 830 0;
BA_ "GenMsgCycleTime" BO_ 830 100;
BA_ "GenMsgStartDelayTime" BO_ 830 10;
BA_ "VFrameFormat" BO_ 1071 0;
BA_ "GenMsgCycleTime" BO_ 1071 150;
BA_ "GenMsgStartDelayTime" BO_ 1071 55;
BA_ "VFrameFormat" BO_ 1068 0;
BA_ "GenMsgCycleTime" BO_ 1068 150;
BA_ "GenMsgStartDelayTime" BO_ 1068 35;
BA_ "VFrameFormat" BO_ 1065 0;
BA_ "GenMsgCycleTime" BO_ 1065 150;
BA_ "GenMsgStartDelayTime" BO_ 1065 20;
BA_ "VFrameFormat" BO_ 1062 0;
BA_ "GenMsgCycleTime" BO_ 1062 150;
BA_ "GenMsgStartDelayTime" BO_ 1062 40;
BA_ "VFrameFormat" BO_ 1404 0;
BA_ "GenMsgCycleTime" BO_ 1404 1000;
BA_ "GenMsgStartDelayTime" BO_ 1404 360;
BA_ "VFrameFormat" BO_ 1035 0;
BA_ "GenMsgCycleTime" BO_ 1035 100;
BA_ "GenMsgStartDelayTime" BO_ 1035 20;
BA_ "VFrameFormat" BO_ 1032 0;
BA_ "GenMsgCycleTime" BO_ 1032 100;
BA_ "GenMsgStartDelayTime" BO_ 1032 80;
BA_ "VFrameFormat" BO_ 1237 0;
BA_ "GenMsgCycleTime" BO_ 1237 200;
BA_ "GenMsgStartDelayTime" BO_ 1237 100;
BA_ "VFrameFormat" BO_ 1234 0;
BA_ "GenMsgCycleTime" BO_ 1234 200;
BA_ "GenMsgStartDelayTime" BO_ 1234 120;
BA_ "VFrameFormat" BO_ 1231 0;
BA_ "GenMsgCycleTime" BO_ 1231 200;
BA_ "GenMsgStartDelayTime" BO_ 1231 140;
BA_ "VFrameFormat" BO_ 1403 0;
BA_ "GenMsgCycleTime" BO_ 1403 1000;
BA_ "GenMsgStartDelayTime" BO_ 1403 280;
BA_ "VFrameFormat" BO_ 1402 0;
BA_ "GenMsgCycleTime" BO_ 1402 1000;
BA_ "GenMsgStartDelayTime" BO_ 1402 320;
BA_ "VFrameFormat" BO_ 1401 0;
BA_ "GenMsgCycleTime" BO_ 1401 1000;
BA_ "GenMsgStartDelayTime" BO_ 1401 350;
BA_ "VFrameFormat" BO_ 1436 0;
BA_ "GenMsgCycleTime" BO_ 1436 1000;
BA_ "GenMsgStartDelayTime" BO_ 1436 345;
BA_ "GenSigSendType" SG_ 2671835728 XCP_FA_50 7;
BA_ "GenSigSendType" SG_ 2671792378 XCP_50_FA 7;
BA_ "GenSigCycleTime" SG_ 1300 CalLoadTruckFrontAxle2_ISig_4 100;
BA_ "GenSigCycleTimeActive" SG_ 1300 CalLoadTruckFrontAxle2_ISig_4 100;
BA_ "GenSigStartValue" SG_ 1300 CalLoadTruckFrontAxle2_ISig_4 65535;
BA_ "GenSigCycleTime" SG_ 1300 CalLoadTrailer1Axle1_ISig_4 100;
BA_ "GenSigCycleTimeActive" SG_ 1300 CalLoadTrailer1Axle1_ISig_4 100;
BA_ "GenSigStartValue" SG_ 1300 CalLoadTrailer1Axle1_ISig_4 65535;
BA_ "GenSigCycleTime" SG_ 1300 CalLoadTrailer2Axle6_ISig_4 100;
BA_ "GenSigCycleTimeActive" SG_ 1300 CalLoadTrailer2Axle6_ISig_4 100;
BA_ "GenSigStartValue" SG_ 1300 CalLoadTrailer2Axle6_ISig_4 65535;
BA_ "GenSigCycleTime" SG_ 1300 CalLoadTrailer4Axle4_ISig_4 100;
BA_ "GenSigCycleTimeActive" SG_ 1300 CalLoadTrailer4Axle4_ISig_4 100;
BA_ "GenSigStartValue" SG_ 1300 CalLoadTrailer4Axle4_ISig_4 65535;
BA_ "GenSigCycleTime" SG_ 1299 CalLoadTrailer5Axle1_ISig_4 100;
BA_ "GenSigCycleTimeActive" SG_ 1299 CalLoadTrailer5Axle1_ISig_4 100;
BA_ "GenSigStartValue" SG_ 1299 CalLoadTrailer5Axle1_ISig_4 65535;
BA_ "GenSigCycleTime" SG_ 1299 CalLoadTrailer3Axle1_ISig_4 100;
BA_ "GenSigCycleTimeActive" SG_ 1299 CalLoadTrailer3Axle1_ISig_4 100;
BA_ "GenSigStartValue" SG_ 1299 CalLoadTrailer3Axle1_ISig_4 65535;
BA_ "GenSigCycleTime" SG_ 1299 CalLoadTrailer5Axle5_ISig_4 100;
BA_ "GenSigCycleTimeActive" SG_ 1299 CalLoadTrailer5Axle5_ISig_4 100;
BA_ "GenSigStartValue" SG_ 1299 CalLoadTrailer5Axle5_ISig_4 65535;
BA_ "GenSigCycleTime" SG_ 1299 CalLoadTrailer5Axle4_ISig_4 100;
BA_ "GenSigCycleTimeActive" SG_ 1299 CalLoadTrailer5Axle4_ISig_4 100;
BA_ "GenSigStartValue" SG_ 1299 CalLoadTrailer5Axle4_ISig_4 65535;
BA_ "GenSigCycleTime" SG_ 1297 CalLoadTrailer5Axle3_ISig_4 100;
BA_ "GenSigCycleTimeActive" SG_ 1297 CalLoadTrailer5Axle3_ISig_4 100;
BA_ "GenSigStartValue" SG_ 1297 CalLoadTrailer5Axle3_ISig_4 65535;
BA_ "GenSigCycleTime" SG_ 1297 CalLoadTrailer4Axle1_ISig_4 100;
BA_ "GenSigCycleTimeActive" SG_ 1297 CalLoadTrailer4Axle1_ISig_4 100;
BA_ "GenSigStartValue" SG_ 1297 CalLoadTrailer4Axle1_ISig_4 65535;
BA_ "GenSigCycleTime" SG_ 1297 CalLoadTrailer2Axle5_ISig_4 100;
BA_ "GenSigCycleTimeActive" SG_ 1297 CalLoadTrailer2Axle5_ISig_4 100;
BA_ "GenSigStartValue" SG_ 1297 CalLoadTrailer2Axle5_ISig_4 65535;
BA_ "GenSigCycleTime" SG_ 1297 CalLoadTrailer3Axle3_ISig_4 100;
BA_ "GenSigCycleTimeActive" SG_ 1297 CalLoadTrailer3Axle3_ISig_4 100;
BA_ "GenSigStartValue" SG_ 1297 CalLoadTrailer3Axle3_ISig_4 65535;
BA_ "GenSigCycleTime" SG_ 1296 CalLoadTrailer1Axle3_ISig_4 100;
BA_ "GenSigCycleTimeActive" SG_ 1296 CalLoadTrailer1Axle3_ISig_4 100;
BA_ "GenSigStartValue" SG_ 1296 CalLoadTrailer1Axle3_ISig_4 65535;
BA_ "GenSigCycleTime" SG_ 1296 CalLoadTrailer4Axle5_ISig_4 100;
BA_ "GenSigCycleTimeActive" SG_ 1296 CalLoadTrailer4Axle5_ISig_4 100;
BA_ "GenSigStartValue" SG_ 1296 CalLoadTrailer4Axle5_ISig_4 65535;
BA_ "GenSigCycleTime" SG_ 1296 CalLoadTruckRearAxle1_ISig_4 100;
BA_ "GenSigCycleTimeActive" SG_ 1296 CalLoadTruckRearAxle1_ISig_4 100;
BA_ "GenSigStartValue" SG_ 1296 CalLoadTruckRearAxle1_ISig_4 65535;
BA_ "GenSigCycleTime" SG_ 1296 CalLoadTruckFrontAxle1_ISig_4 100;
BA_ "GenSigCycleTimeActive" SG_ 1296 CalLoadTruckFrontAxle1_ISig_4 100;
BA_ "GenSigStartValue" SG_ 1296 CalLoadTruckFrontAxle1_ISig_4 65535;
BA_ "GenSigCycleTime" SG_ 1383 Trail2NoOfFrontAxles_ISig_4 100;
BA_ "GenSigCycleTimeActive" SG_ 1383 Trail2NoOfFrontAxles_ISig_4 100;
BA_ "GenSigStartValue" SG_ 1383 Trail2NoOfFrontAxles_ISig_4 15;
BA_ "GenSigCycleTime" SG_ 1383 BbOutputFault_Status 100;
BA_ "GenSigCycleTimeActive" SG_ 1383 BbOutputFault_Status 100;
BA_ "GenSigStartValue" SG_ 1383 BbOutputFault_Status 255;
BA_ "GenSigCycleTime" SG_ 1383 Trail2NoOfAxles_ISig_4 100;
BA_ "GenSigCycleTimeActive" SG_ 1383 Trail2NoOfAxles_ISig_4 100;
BA_ "GenSigStartValue" SG_ 1383 Trail2NoOfAxles_ISig_4 15;
BA_ "GenSigCycleTime" SG_ 1383 BunkOutputFault_Status 100;
BA_ "GenSigCycleTimeActive" SG_ 1383 BunkOutputFault_Status 100;
BA_ "GenSigStartValue" SG_ 1383 BunkOutputFault_Status 255;
BA_ "GenSigCycleTime" SG_ 1383 Trail4NoOfFrontAxles_ISig_4 100;
BA_ "GenSigCycleTimeActive" SG_ 1383 Trail4NoOfFrontAxles_ISig_4 100;
BA_ "GenSigStartValue" SG_ 1383 Trail4NoOfFrontAxles_ISig_4 15;
BA_ "GenSigCycleTime" SG_ 1383 Trail1NoOfAxles_ISig_4 100;
BA_ "GenSigCycleTimeActive" SG_ 1383 Trail1NoOfAxles_ISig_4 100;
BA_ "GenSigStartValue" SG_ 1383 Trail1NoOfAxles_ISig_4 15;
BA_ "GenSigCycleTime" SG_ 1383 Trail3NoOfAxles_ISig_4 100;
BA_ "GenSigCycleTimeActive" SG_ 1383 Trail3NoOfAxles_ISig_4 100;
BA_ "GenSigStartValue" SG_ 1383 Trail3NoOfAxles_ISig_4 15;
BA_ "GenSigCycleTime" SG_ 1383 Trail4NoOfAxles_ISig_4 100;
BA_ "GenSigCycleTimeActive" SG_ 1383 Trail4NoOfAxles_ISig_4 100;
BA_ "GenSigStartValue" SG_ 1383 Trail4NoOfAxles_ISig_4 15;
BA_ "GenSigCycleTime" SG_ 1383 Trail1NoOfFrontAxles_ISig_4 100;
BA_ "GenSigCycleTimeActive" SG_ 1383 Trail1NoOfFrontAxles_ISig_4 100;
BA_ "GenSigStartValue" SG_ 1383 Trail1NoOfFrontAxles_ISig_4 15;
BA_ "GenSigCycleTime" SG_ 1383 Trail5NoOfFrontAxles_ISig_4 100;
BA_ "GenSigCycleTimeActive" SG_ 1383 Trail5NoOfFrontAxles_ISig_4 100;
BA_ "GenSigStartValue" SG_ 1383 Trail5NoOfFrontAxles_ISig_4 15;
BA_ "GenSigCycleTime" SG_ 1383 Trail5NoOfAxles_ISig_4 100;
BA_ "GenSigCycleTimeActive" SG_ 1383 Trail5NoOfAxles_ISig_4 100;
BA_ "GenSigStartValue" SG_ 1383 Trail5NoOfAxles_ISig_4 15;
BA_ "GenSigCycleTime" SG_ 1383 IpOutputFault_Status 100;
BA_ "GenSigCycleTimeActive" SG_ 1383 IpOutputFault_Status 100;
BA_ "GenSigStartValue" SG_ 1383 IpOutputFault_Status 255;
BA_ "GenSigCycleTime" SG_ 1383 Trail3NoOfFrontAxles_ISig_4 100;
BA_ "GenSigCycleTimeActive" SG_ 1383 Trail3NoOfFrontAxles_ISig_4 100;
BA_ "GenSigStartValue" SG_ 1383 Trail3NoOfFrontAxles_ISig_4 15;
BA_ "GenSigCycleTime" SG_ 1380 Trail3Type_TrailType_ISig_4 100;
BA_ "GenSigCycleTimeActive" SG_ 1380 Trail3Type_TrailType_ISig_4 100;
BA_ "GenSigStartValue" SG_ 1380 Trail3Type_TrailType_ISig_4 7;
BA_ "GenSigCycleTime" SG_ 1380 Trail3Type_Towing_ISig_4 100;
BA_ "GenSigCycleTimeActive" SG_ 1380 Trail3Type_Towing_ISig_4 100;
BA_ "GenSigCycleTime" SG_ 1380 Trail4Type_Towing_ISig_4 100;
BA_ "GenSigCycleTimeActive" SG_ 1380 Trail4Type_Towing_ISig_4 100;
BA_ "GenSigCycleTime" SG_ 1380 Trail4Type_TrailType_ISig_4 100;
BA_ "GenSigCycleTimeActive" SG_ 1380 Trail4Type_TrailType_ISig_4 100;
BA_ "GenSigStartValue" SG_ 1380 Trail4Type_TrailType_ISig_4 7;
BA_ "GenSigCycleTime" SG_ 1380 Trail5Type_TrailType_ISig_4 100;
BA_ "GenSigCycleTimeActive" SG_ 1380 Trail5Type_TrailType_ISig_4 100;
BA_ "GenSigStartValue" SG_ 1380 Trail5Type_TrailType_ISig_4 7;
BA_ "GenSigCycleTime" SG_ 1380 Trail5Type_Towing_ISig_4 100;
BA_ "GenSigCycleTimeActive" SG_ 1380 Trail5Type_Towing_ISig_4 100;
BA_ "GenSigCycleTime" SG_ 1378 Trail1Type_Towing_ISig_4 100;
BA_ "GenSigCycleTimeActive" SG_ 1378 Trail1Type_Towing_ISig_4 100;
BA_ "GenSigCycleTime" SG_ 1378 UncalibratedTruckLoad_ISig_4 100;
BA_ "GenSigCycleTimeActive" SG_ 1378 UncalibratedTruckLoad_ISig_4 100;
BA_ "GenSigStartValue" SG_ 1378 UncalibratedTruckLoad_ISig_4 65535;
BA_ "GenSigCycleTime" SG_ 1378 UncalibratedCombinationLoad_ISig 100;
BA_ "GenSigCycleTimeActive" SG_ 1378 UncalibratedCombinationLoad_ISig 100;
BA_ "GenSigStartValue" SG_ 1378 UncalibratedCombinationLoad_ISig 65535;
BA_ "SystemSignalLongSymbol" SG_ 1378 UncalibratedCombinationLoad_ISig "UncalibratedCombinationLoad_ISig_4";
BA_ "GenSigCycleTime" SG_ 1378 Trail1Type_TrailType_ISig_4 100;
BA_ "GenSigCycleTimeActive" SG_ 1378 Trail1Type_TrailType_ISig_4 100;
BA_ "GenSigStartValue" SG_ 1378 Trail1Type_TrailType_ISig_4 7;
BA_ "GenSigCycleTime" SG_ 1378 Trail2Type_Towing_ISig_4 100;
BA_ "GenSigCycleTimeActive" SG_ 1378 Trail2Type_Towing_ISig_4 100;
BA_ "GenSigCycleTime" SG_ 1378 Trail2Type_TrailType_ISig_4 100;
BA_ "GenSigCycleTimeActive" SG_ 1378 Trail2Type_TrailType_ISig_4 100;
BA_ "GenSigStartValue" SG_ 1378 Trail2Type_TrailType_ISig_4 7;
BA_ "GenSigCycleTime" SG_ 643 RearAxleGroupLoad_ISig_4 100;
BA_ "GenSigCycleTimeActive" SG_ 643 RearAxleGroupLoad_ISig_4 100;
BA_ "GenSigStartValue" SG_ 643 RearAxleGroupLoad_ISig_4 65535;
BA_ "GenSigCycleTime" SG_ 643 RelCargoLoadTrailer1_ISig_4 100;
BA_ "GenSigCycleTimeActive" SG_ 643 RelCargoLoadTrailer1_ISig_4 100;
BA_ "GenSigStartValue" SG_ 643 RelCargoLoadTrailer1_ISig_4 65535;
BA_ "GenSigCycleTime" SG_ 643 RelCargoLoadTrailer5_ISig_4 100;
BA_ "GenSigCycleTimeActive" SG_ 643 RelCargoLoadTrailer5_ISig_4 100;
BA_ "GenSigStartValue" SG_ 643 RelCargoLoadTrailer5_ISig_4 65535;
BA_ "GenSigCycleTime" SG_ 643 FrontAxleGroupLoad_ISig_4 100;
BA_ "GenSigCycleTimeActive" SG_ 643 FrontAxleGroupLoad_ISig_4 100;
BA_ "GenSigStartValue" SG_ 643 FrontAxleGroupLoad_ISig_4 65535;
BA_ "SeToolAncestorID_SIGNAL" SG_ 643 FrontAxleGroupLoad_ISig_4 "x0000001D04343A74";
BA_ "SeToolItemID_SIGNAL" SG_ 643 FrontAxleGroupLoad_ISig_4 "x0000001D04343A74";
BA_ "SeToolName_SIGNAL" SG_ 643 FrontAxleGroupLoad_ISig_4 "FrontAxleGroupLoad";
BA_ "SeToolVersion_SIGNAL" SG_ 643 FrontAxleGroupLoad_ISig_4 "1";
BA_ "GenSigCycleTime" SG_ 533 RelCargoLoadTrailer4_ISig_4 100;
BA_ "GenSigCycleTimeActive" SG_ 533 RelCargoLoadTrailer4_ISig_4 100;
BA_ "GenSigStartValue" SG_ 533 RelCargoLoadTrailer4_ISig_4 65535;
BA_ "GenSigCycleTime" SG_ 421 LNGConsumedVehicleStopped 100;
BA_ "GenSigCycleTimeActive" SG_ 421 LNGConsumedVehicleStopped 100;
BA_ "GenSigStartValue" SG_ 421 LNGConsumedVehicleStopped 4294967295;
BA_ "GenSigMaxLatency" SG_ 421 LNGConsumedVehicleStopped 5000;
BA_ "GenSigCycleTime" SG_ 421 RelCargoLoadTruck_ISig_4 100;
BA_ "GenSigCycleTimeActive" SG_ 421 RelCargoLoadTruck_ISig_4 100;
BA_ "GenSigStartValue" SG_ 421 RelCargoLoadTruck_ISig_4 65535;
BA_ "GenSigCycleTime" SG_ 323 LoadTrailer5_ISig_4 100;
BA_ "GenSigCycleTimeActive" SG_ 323 LoadTrailer5_ISig_4 100;
BA_ "GenSigStartValue" SG_ 323 LoadTrailer5_ISig_4 65535;
BA_ "GenSigCycleTime" SG_ 323 UncalLoadTrkRAxle3_ISig_4 100;
BA_ "GenSigCycleTimeActive" SG_ 323 UncalLoadTrkRAxle3_ISig_4 100;
BA_ "GenSigStartValue" SG_ 323 UncalLoadTrkRAxle3_ISig_4 65535;
BA_ "GenSigCycleTime" SG_ 323 LoadTrailer4Back_ISig_4 100;
BA_ "GenSigCycleTimeActive" SG_ 323 LoadTrailer4Back_ISig_4 100;
BA_ "GenSigStartValue" SG_ 323 LoadTrailer4Back_ISig_4 65535;
BA_ "GenSigCycleTime" SG_ 323 LoadTrailer2Front_ISig_4 100;
BA_ "GenSigCycleTimeActive" SG_ 323 LoadTrailer2Front_ISig_4 100;
BA_ "GenSigStartValue" SG_ 323 LoadTrailer2Front_ISig_4 65535;
BA_ "GenSigCycleTime" SG_ 310 RelCargoLoadTrailer2_ISig_4 100;
BA_ "GenSigCycleTimeActive" SG_ 310 RelCargoLoadTrailer2_ISig_4 100;
BA_ "GenSigStartValue" SG_ 310 RelCargoLoadTrailer2_ISig_4 65535;
BA_ "GenSigCycleTime" SG_ 310 RelCargoLoadTrailer3_ISig_4 100;
BA_ "GenSigCycleTimeActive" SG_ 310 RelCargoLoadTrailer3_ISig_4 100;
BA_ "GenSigStartValue" SG_ 310 RelCargoLoadTrailer3_ISig_4 65535;
BA_ "GenSigCycleTime" SG_ 310 MainBeamLEDStatusLeft_ISig_4 100;
BA_ "GenSigCycleTimeActive" SG_ 310 MainBeamLEDStatusLeft_ISig_4 100;
BA_ "GenSigStartValue" SG_ 310 MainBeamLEDStatusLeft_ISig_4 7;
BA_ "GenSigCycleTime" SG_ 310 MainBeamLEDStatusRight_ISig_4 100;
BA_ "GenSigCycleTimeActive" SG_ 310 MainBeamLEDStatusRight_ISig_4 100;
BA_ "GenSigStartValue" SG_ 310 MainBeamLEDStatusRight_ISig_4 7;
BA_ "GenSigCycleTime" SG_ 1367 DistanceToEmptyLNG_ISig_4 100;
BA_ "GenSigCycleTimeActive" SG_ 1367 DistanceToEmptyLNG_ISig_4 100;
BA_ "GenSigStartValue" SG_ 1367 DistanceToEmptyLNG_ISig_4 65535;
BA_ "GenSigMaxLatency" SG_ 1367 DistanceToEmptyLNG_ISig_4 1000;
BA_ "GenSigCycleTime" SG_ 1367 DistanceToEmpty_Diesel_ISig_4 100;
BA_ "GenSigCycleTimeActive" SG_ 1367 DistanceToEmpty_Diesel_ISig_4 100;
BA_ "GenSigStartValue" SG_ 1367 DistanceToEmpty_Diesel_ISig_4 65535;
BA_ "GenSigMaxLatency" SG_ 1367 DistanceToEmpty_Diesel_ISig_4 1000;
BA_ "GenSigCycleTime" SG_ 1370 Trailer1CalibrationType 100;
BA_ "GenSigCycleTimeActive" SG_ 1370 Trailer1CalibrationType 100;
BA_ "GenSigStartValue" SG_ 1370 Trailer1CalibrationType 7;
BA_ "GenSigCycleTime" SG_ 1370 FrontConspicLamp_stat_HiLeft_ISi 100;
BA_ "GenSigCycleTimeActive" SG_ 1370 FrontConspicLamp_stat_HiLeft_ISi 100;
BA_ "GenSigStartValue" SG_ 1370 FrontConspicLamp_stat_HiLeft_ISi 7;
BA_ "GenSigMaxLatency" SG_ 1370 FrontConspicLamp_stat_HiLeft_ISi 259;
BA_ "SystemSignalLongSymbol" SG_ 1370 FrontConspicLamp_stat_HiLeft_ISi "FrontConspicLamp_stat_HiLeft_ISig_4";
BA_ "GenSigCycleTime" SG_ 1370 TrailerDirIndLeftOutputStat_ISig 100;
BA_ "GenSigCycleTimeActive" SG_ 1370 TrailerDirIndLeftOutputStat_ISig 100;
BA_ "GenSigStartValue" SG_ 1370 TrailerDirIndLeftOutputStat_ISig 7;
BA_ "SystemSignalLongSymbol" SG_ 1370 TrailerDirIndLeftOutputStat_ISig "TrailerDirIndLeftOutputStat_ISig_4";
BA_ "GenSigCycleTime" SG_ 1370 JumpChargeInterface_stat_ISig_4 100;
BA_ "GenSigCycleTimeActive" SG_ 1370 JumpChargeInterface_stat_ISig_4 100;
BA_ "GenSigStartValue" SG_ 1370 JumpChargeInterface_stat_ISig_4 3;
BA_ "GenSigCycleTime" SG_ 1370 TrailerPosLightLeftOutputStat_IS 100;
BA_ "GenSigCycleTimeActive" SG_ 1370 TrailerPosLightLeftOutputStat_IS 100;
BA_ "GenSigStartValue" SG_ 1370 TrailerPosLightLeftOutputStat_IS 7;
BA_ "SystemSignalLongSymbol" SG_ 1370 TrailerPosLightLeftOutputStat_IS "TrailerPosLightLeftOutputStat_ISig_4";
BA_ "GenSigCycleTime" SG_ 1370 TruckCalibrated 100;
BA_ "GenSigCycleTimeActive" SG_ 1370 TruckCalibrated 100;
BA_ "GenSigStartValue" SG_ 1370 TruckCalibrated 7;
BA_ "GenSigCycleTime" SG_ 1370 Trailer5CalibrationType 100;
BA_ "GenSigCycleTimeActive" SG_ 1370 Trailer5CalibrationType 100;
BA_ "GenSigStartValue" SG_ 1370 Trailer5CalibrationType 7;
BA_ "GenSigCycleTime" SG_ 1370 Trailer2CalibrationType 100;
BA_ "GenSigCycleTimeActive" SG_ 1370 Trailer2CalibrationType 100;
BA_ "GenSigStartValue" SG_ 1370 Trailer2CalibrationType 7;
BA_ "GenSigCycleTime" SG_ 1370 Trailer4CalibrationType 100;
BA_ "GenSigCycleTimeActive" SG_ 1370 Trailer4CalibrationType 100;
BA_ "GenSigStartValue" SG_ 1370 Trailer4CalibrationType 7;
BA_ "GenSigCycleTime" SG_ 1370 TrailerBrakeLightOutputStat_ISig 100;
BA_ "GenSigCycleTimeActive" SG_ 1370 TrailerBrakeLightOutputStat_ISig 100;
BA_ "GenSigStartValue" SG_ 1370 TrailerBrakeLightOutputStat_ISig 7;
BA_ "SystemSignalLongSymbol" SG_ 1370 TrailerBrakeLightOutputStat_ISig "TrailerBrakeLightOutputStat_ISig_4";
BA_ "GenSigCycleTime" SG_ 1370 FrontConspicLamp_stat_LoRight_IS 100;
BA_ "GenSigCycleTimeActive" SG_ 1370 FrontConspicLamp_stat_LoRight_IS 100;
BA_ "GenSigStartValue" SG_ 1370 FrontConspicLamp_stat_LoRight_IS 7;
BA_ "GenSigMaxLatency" SG_ 1370 FrontConspicLamp_stat_LoRight_IS 259;
BA_ "SystemSignalLongSymbol" SG_ 1370 FrontConspicLamp_stat_LoRight_IS "FrontConspicLamp_stat_LoRight_ISig_4";
BA_ "GenSigCycleTime" SG_ 1370 FrontConspicLamp_stat_LoLeft_ISi 100;
BA_ "GenSigCycleTimeActive" SG_ 1370 FrontConspicLamp_stat_LoLeft_ISi 100;
BA_ "GenSigStartValue" SG_ 1370 FrontConspicLamp_stat_LoLeft_ISi 7;
BA_ "GenSigMaxLatency" SG_ 1370 FrontConspicLamp_stat_LoLeft_ISi 259;
BA_ "SystemSignalLongSymbol" SG_ 1370 FrontConspicLamp_stat_LoLeft_ISi "FrontConspicLamp_stat_LoLeft_ISig_4";
BA_ "GenSigCycleTime" SG_ 1370 NumberOfSavedTrailers 100;
BA_ "GenSigCycleTimeActive" SG_ 1370 NumberOfSavedTrailers 100;
BA_ "GenSigStartValue" SG_ 1370 NumberOfSavedTrailers 255;
BA_ "GenSigCycleTime" SG_ 1370 TrailerDirIndRightOutputStat_ISi 100;
BA_ "GenSigCycleTimeActive" SG_ 1370 TrailerDirIndRightOutputStat_ISi 100;
BA_ "GenSigStartValue" SG_ 1370 TrailerDirIndRightOutputStat_ISi 7;
BA_ "SystemSignalLongSymbol" SG_ 1370 TrailerDirIndRightOutputStat_ISi "TrailerDirIndRightOutputStat_ISig_4";
BA_ "GenSigCycleTime" SG_ 1370 TrailerPosLightRightOutputStat_I 100;
BA_ "GenSigCycleTimeActive" SG_ 1370 TrailerPosLightRightOutputStat_I 100;
BA_ "GenSigStartValue" SG_ 1370 TrailerPosLightRightOutputStat_I 7;
BA_ "SystemSignalLongSymbol" SG_ 1370 TrailerPosLightRightOutputStat_I "TrailerPosLightRightOutputStat_ISig_4";
BA_ "GenSigCycleTime" SG_ 1370 Trailer3CalibrationType 100;
BA_ "GenSigCycleTimeActive" SG_ 1370 Trailer3CalibrationType 100;
BA_ "GenSigStartValue" SG_ 1370 Trailer3CalibrationType 7;
BA_ "GenSigCycleTime" SG_ 1370 FrontConspicLamp_stat_HiRight_IS 100;
BA_ "GenSigCycleTimeActive" SG_ 1370 FrontConspicLamp_stat_HiRight_IS 100;
BA_ "GenSigStartValue" SG_ 1370 FrontConspicLamp_stat_HiRight_IS 7;
BA_ "GenSigMaxLatency" SG_ 1370 FrontConspicLamp_stat_HiRight_IS 259;
BA_ "SystemSignalLongSymbol" SG_ 1370 FrontConspicLamp_stat_HiRight_IS "FrontConspicLamp_stat_HiRight_ISig_4";
BA_ "GenSigCycleTime" SG_ 546 FASSaturated_ISig_4 100;
BA_ "GenSigCycleTimeActive" SG_ 546 FASSaturated_ISig_4 100;
BA_ "GenSigStartValue" SG_ 546 FASSaturated_ISig_4 3;
BA_ "GenSigMaxLatency" SG_ 546 FASSaturated_ISig_4 27;
BA_ "GenSigCycleTime" SG_ 546 OverSteerGuidanceStatus_ISig_4 100;
BA_ "GenSigCycleTimeActive" SG_ 546 OverSteerGuidanceStatus_ISig_4 100;
BA_ "GenSigStartValue" SG_ 546 OverSteerGuidanceStatus_ISig_4 3;
BA_ "GenSigMaxLatency" SG_ 546 OverSteerGuidanceStatus_ISig_4 27;
BA_ "GenSigCycleTime" SG_ 546 FASFullyOperational_ISig_4 100;
BA_ "GenSigCycleTimeActive" SG_ 546 FASFullyOperational_ISig_4 100;
BA_ "GenSigStartValue" SG_ 546 FASFullyOperational_ISig_4 3;
BA_ "GenSigMaxLatency" SG_ 546 FASFullyOperational_ISig_4 27;
BA_ "GenSigCycleTime" SG_ 546 FASFunctionInControl_ISig_4 100;
BA_ "GenSigCycleTimeActive" SG_ 546 FASFunctionInControl_ISig_4 100;
BA_ "GenSigStartValue" SG_ 546 FASFunctionInControl_ISig_4 3;
BA_ "GenSigMaxLatency" SG_ 546 FASFunctionInControl_ISig_4 27;
BA_ "GenSigCycleTime" SG_ 546 FrontRoadWheelAngleEstimate_ISig 100;
BA_ "GenSigCycleTimeActive" SG_ 546 FrontRoadWheelAngleEstimate_ISig 100;
BA_ "GenSigStartValue" SG_ 546 FrontRoadWheelAngleEstimate_ISig 65535;
BA_ "GenSigMaxLatency" SG_ 546 FrontRoadWheelAngleEstimate_ISig 27;
BA_ "SystemSignalLongSymbol" SG_ 546 FrontRoadWheelAngleEstimate_ISig "FrontRoadWheelAngleEstimate_ISig_4";
BA_ "GenSigCycleTime" SG_ 546 DriverSteeringTorqueEstimate_ISi 100;
BA_ "GenSigCycleTimeActive" SG_ 546 DriverSteeringTorqueEstimate_ISi 100;
BA_ "GenSigStartValue" SG_ 546 DriverSteeringTorqueEstimate_ISi 1023;
BA_ "GenSigMaxLatency" SG_ 546 DriverSteeringTorqueEstimate_ISi 27;
BA_ "SystemSignalLongSymbol" SG_ 546 DriverSteeringTorqueEstimate_ISi "DriverSteeringTorqueEstimate_ISig_4";
BA_ "GenSigCycleTime" SG_ 546 DriverSteeringTqEstimateConf_ISi 100;
BA_ "GenSigCycleTimeActive" SG_ 546 DriverSteeringTqEstimateConf_ISi 100;
BA_ "GenSigStartValue" SG_ 546 DriverSteeringTqEstimateConf_ISi 7;
BA_ "GenSigMaxLatency" SG_ 546 DriverSteeringTqEstimateConf_ISi 27;
BA_ "SystemSignalLongSymbol" SG_ 546 DriverSteeringTqEstimateConf_ISi "DriverSteeringTqEstimateConf_ISig_4";
BA_ "GenSigCycleTime" SG_ 1405 ActualFasPersSettingsButton_ISig 100;
BA_ "GenSigCycleTimeActive" SG_ 1405 ActualFasPersSettingsButton_ISig 100;
BA_ "GenSigStartValue" SG_ 1405 ActualFasPersSettingsButton_ISig 7;
BA_ "SystemSignalLongSymbol" SG_ 1405 ActualFasPersSettingsButton_ISig "ActualFasPersSettingsButton_ISig_4";
BA_ "GenSigCycleTime" SG_ 1405 FasUsrDefStiffStraightSetting_IS 100;
BA_ "GenSigCycleTimeActive" SG_ 1405 FasUsrDefStiffStraightSetting_IS 100;
BA_ "GenSigStartValue" SG_ 1405 FasUsrDefStiffStraightSetting_IS 31;
BA_ "SystemSignalLongSymbol" SG_ 1405 FasUsrDefStiffStraightSetting_IS "FasUsrDefStiffStraightSetting_ISig_4";
BA_ "GenSigCycleTime" SG_ 1405 FuelLostByBraking_ISig_4 100;
BA_ "GenSigCycleTimeActive" SG_ 1405 FuelLostByBraking_ISig_4 100;
BA_ "GenSigStartValue" SG_ 1405 FuelLostByBraking_ISig_4 4294967295;
BA_ "Platform_VMCU1_Sig" SG_ 1405 FuelLostByBraking_ISig_4 1;
BA_ "GenSigCycleTime" SG_ 1405 ActualFasManualOffsetSetting_ISi 100;
BA_ "GenSigCycleTimeActive" SG_ 1405 ActualFasManualOffsetSetting_ISi 100;
BA_ "GenSigStartValue" SG_ 1405 ActualFasManualOffsetSetting_ISi 31;
BA_ "SystemSignalLongSymbol" SG_ 1405 ActualFasManualOffsetSetting_ISi "ActualFasManualOffsetSetting_ISig_4";
BA_ "GenSigCycleTime" SG_ 1405 FasUsrDefinedDampingSetting_ISig 100;
BA_ "GenSigCycleTimeActive" SG_ 1405 FasUsrDefinedDampingSetting_ISig 100;
BA_ "GenSigStartValue" SG_ 1405 FasUsrDefinedDampingSetting_ISig 31;
BA_ "SystemSignalLongSymbol" SG_ 1405 FasUsrDefinedDampingSetting_ISig "FasUsrDefinedDampingSetting_ISig_4";
BA_ "GenSigCycleTime" SG_ 1405 FasDriver_ISig_4 100;
BA_ "GenSigCycleTimeActive" SG_ 1405 FasDriver_ISig_4 100;
BA_ "GenSigStartValue" SG_ 1405 FasDriver_ISig_4 15;
BA_ "GenSigCycleTime" SG_ 1405 FasUsrDefLowSpeedReturnSetting_I 100;
BA_ "GenSigCycleTimeActive" SG_ 1405 FasUsrDefLowSpeedReturnSetting_I 100;
BA_ "GenSigStartValue" SG_ 1405 FasUsrDefLowSpeedReturnSetting_I 31;
BA_ "SystemSignalLongSymbol" SG_ 1405 FasUsrDefLowSpeedReturnSetting_I "FasUsrDefLowSpeedReturnSetting_ISig_4";
BA_ "GenSigCycleTime" SG_ 1405 FasUsrDefStiffnessCurveSetting_I 100;
BA_ "GenSigCycleTimeActive" SG_ 1405 FasUsrDefStiffnessCurveSetting_I 100;
BA_ "GenSigStartValue" SG_ 1405 FasUsrDefStiffnessCurveSetting_I 31;
BA_ "SystemSignalLongSymbol" SG_ 1405 FasUsrDefStiffnessCurveSetting_I "FasUsrDefStiffnessCurveSetting_ISig_4";
BA_ "GenSigCycleTime" SG_ 830 PS_PosLightDoorOpen 100;
BA_ "GenSigCycleTimeActive" SG_ 830 PS_PosLightDoorOpen 100;
BA_ "GenSigStartValue" SG_ 830 PS_PosLightDoorOpen 3;
BA_ "Platform_VMCU1_Sig" SG_ 830 PS_PosLightDoorOpen 1;
BA_ "GenSigCycleTime" SG_ 830 PS_FogLightRear 100;
BA_ "GenSigCycleTimeActive" SG_ 830 PS_FogLightRear 100;
BA_ "GenSigStartValue" SG_ 830 PS_FogLightRear 3;
BA_ "Platform_VMCU1_Sig" SG_ 830 PS_FogLightRear 1;
BA_ "GenSigCycleTime" SG_ 830 TrailerBodyLampDI_stat 100;
BA_ "GenSigCycleTimeActive" SG_ 830 TrailerBodyLampDI_stat 100;
BA_ "GenSigStartValue" SG_ 830 TrailerBodyLampDI_stat 3;
BA_ "Platform_VMCU1_Sig" SG_ 830 TrailerBodyLampDI_stat 1;
BA_ "GenSigCycleTime" SG_ 830 PV_HeadLightLevel 100;
BA_ "GenSigCycleTimeActive" SG_ 830 PV_HeadLightLevel 100;
BA_ "GenSigStartValue" SG_ 830 PV_HeadLightLevel 15;
BA_ "Platform_VMCU1_Sig" SG_ 830 PV_HeadLightLevel 1;
BA_ "GenSigCycleTime" SG_ 830 TrailerBodyLampFdbk_stat 100;
BA_ "GenSigCycleTimeActive" SG_ 830 TrailerBodyLampFdbk_stat 100;
BA_ "GenSigStartValue" SG_ 830 TrailerBodyLampFdbk_stat 3;
BA_ "Platform_VMCU1_Sig" SG_ 830 TrailerBodyLampFdbk_stat 1;
BA_ "GenSigCycleTime" SG_ 830 PS_FogLightFront 100;
BA_ "GenSigCycleTimeActive" SG_ 830 PS_FogLightFront 100;
BA_ "GenSigStartValue" SG_ 830 PS_FogLightFront 3;
BA_ "Platform_VMCU1_Sig" SG_ 830 PS_FogLightFront 1;
BA_ "GenSigCycleTime" SG_ 830 Alcolock_PBReleaseInhibit_ind 100;
BA_ "GenSigCycleTimeActive" SG_ 830 Alcolock_PBReleaseInhibit_ind 100;
BA_ "GenSigStartValue" SG_ 830 Alcolock_PBReleaseInhibit_ind 7;
BA_ "GenSigCycleTime" SG_ 830 DHCNotificationReq 100;
BA_ "GenSigCycleTimeActive" SG_ 830 DHCNotificationReq 100;
BA_ "GenSigStartValue" SG_ 830 DHCNotificationReq 15;
BA_ "GenSigCycleTime" SG_ 830 DriverCrank_rqst 100;
BA_ "GenSigCycleTimeActive" SG_ 830 DriverCrank_rqst 100;
BA_ "GenSigStartValue" SG_ 830 DriverCrank_rqst 3;
BA_ "Platform_VMCU1_Sig" SG_ 830 DriverCrank_rqst 1;
BA_ "GenSigCycleTime" SG_ 830 PS_HeadLightAdjustment 100;
BA_ "GenSigCycleTimeActive" SG_ 830 PS_HeadLightAdjustment 100;
BA_ "GenSigStartValue" SG_ 830 PS_HeadLightAdjustment 3;
BA_ "Platform_VMCU1_Sig" SG_ 830 PS_HeadLightAdjustment 1;
BA_ "GenSigCycleTime" SG_ 830 PS_MainBeam 100;
BA_ "GenSigCycleTimeActive" SG_ 830 PS_MainBeam 100;
BA_ "GenSigStartValue" SG_ 830 PS_MainBeam 3;
BA_ "Platform_VMCU1_Sig" SG_ 830 PS_MainBeam 1;
BA_ "GenSigCycleTime" SG_ 830 InstFuel_ConsumpValue 100;
BA_ "GenSigCycleTimeActive" SG_ 830 InstFuel_ConsumpValue 100;
BA_ "GenSigStartValue" SG_ 830 InstFuel_ConsumpValue 65535;
BA_ "Platform_VMCU1_Sig" SG_ 830 InstFuel_ConsumpValue 1;
BA_ "GenSigCycleTime" SG_ 830 InstFuel_VehicleMoving 100;
BA_ "GenSigCycleTimeActive" SG_ 830 InstFuel_VehicleMoving 100;
BA_ "GenSigStartValue" SG_ 830 InstFuel_VehicleMoving 3;
BA_ "Platform_VMCU1_Sig" SG_ 830 InstFuel_VehicleMoving 1;
BA_ "GenSigCycleTime" SG_ 830 PS_AFSAllowed_ISig_4 100;
BA_ "GenSigCycleTimeActive" SG_ 830 PS_AFSAllowed_ISig_4 100;
BA_ "GenSigStartValue" SG_ 830 PS_AFSAllowed_ISig_4 3;
BA_ "GenSigCycleTime" SG_ 830 PS_AFS 100;
BA_ "GenSigCycleTimeActive" SG_ 830 PS_AFS 100;
BA_ "GenSigStartValue" SG_ 830 PS_AFS 7;
BA_ "GenSigCycleTime" SG_ 830 AC2CoolingFanControl_rqst 100;
BA_ "GenSigCycleTimeActive" SG_ 830 AC2CoolingFanControl_rqst 100;
BA_ "GenSigStartValue" SG_ 830 AC2CoolingFanControl_rqst 3;
BA_ "Platform_VMCU1_Sig" SG_ 830 AC2CoolingFanControl_rqst 1;
BA_ "GenSigCycleTime" SG_ 830 DHCStatus 100;
BA_ "GenSigCycleTimeActive" SG_ 830 DHCStatus 100;
BA_ "GenSigStartValue" SG_ 830 DHCStatus 3;
BA_ "GenSigCycleTime" SG_ 830 PS_PositionLight 100;
BA_ "GenSigCycleTimeActive" SG_ 830 PS_PositionLight 100;
BA_ "GenSigStartValue" SG_ 830 PS_PositionLight 3;
BA_ "GenSigCycleTime" SG_ 1071 EcoCruiseSetSpeed 100;
BA_ "GenSigCycleTimeActive" SG_ 1071 EcoCruiseSetSpeed 100;
BA_ "GenSigStartValue" SG_ 1071 EcoCruiseSetSpeed 65535;
BA_ "Platform_VMCU1_Sig" SG_ 1071 EcoCruiseSetSpeed 1;
BA_ "GenSigCycleTime" SG_ 1071 Alcolock_stat_ISig_4 100;
BA_ "GenSigCycleTimeActive" SG_ 1071 Alcolock_stat_ISig_4 100;
BA_ "GenSigStartValue" SG_ 1071 Alcolock_stat_ISig_4 3;
BA_ "Platform_VMCU1_Sig" SG_ 1071 Alcolock_stat_ISig_4 1;
BA_ "GenSigCycleTime" SG_ 1071 CTA_PBReleaseInhibit_ind 100;
BA_ "GenSigCycleTimeActive" SG_ 1071 CTA_PBReleaseInhibit_ind 100;
BA_ "GenSigStartValue" SG_ 1071 CTA_PBReleaseInhibit_ind 7;
BA_ "GenSigCycleTime" SG_ 1071 EngOvrrideCtrlStat_FireTruckMode 100;
BA_ "GenSigCycleTimeActive" SG_ 1071 EngOvrrideCtrlStat_FireTruckMode 100;
BA_ "GenSigStartValue" SG_ 1071 EngOvrrideCtrlStat_FireTruckMode 3;
BA_ "Platform_VMCU1_Sig" SG_ 1071 EngOvrrideCtrlStat_FireTruckMode 1;
BA_ "GenSigCycleTime" SG_ 1071 DHCActualSetSpeed 100;
BA_ "GenSigCycleTimeActive" SG_ 1071 DHCActualSetSpeed 100;
BA_ "GenSigStartValue" SG_ 1071 DHCActualSetSpeed 65535;
BA_ "GenSigCycleTime" SG_ 1071 EngOvrrideCtrlStat_StartOvrrMode 100;
BA_ "GenSigCycleTimeActive" SG_ 1071 EngOvrrideCtrlStat_StartOvrrMode 100;
BA_ "GenSigStartValue" SG_ 1071 EngOvrrideCtrlStat_StartOvrrMode 3;
BA_ "Platform_VMCU1_Sig" SG_ 1071 EngOvrrideCtrlStat_StartOvrrMode 1;
BA_ "GenSigCycleTime" SG_ 1071 EngOvrrideCtrlStat_ProtOvrrMode 100;
BA_ "GenSigCycleTimeActive" SG_ 1071 EngOvrrideCtrlStat_ProtOvrrMode 100;
BA_ "GenSigStartValue" SG_ 1071 EngOvrrideCtrlStat_ProtOvrrMode 3;
BA_ "Platform_VMCU1_Sig" SG_ 1071 EngOvrrideCtrlStat_ProtOvrrMode 1;
BA_ "GenSigCycleTime" SG_ 1071 XRSLBTargetSpeedRequest 100;
BA_ "GenSigCycleTimeActive" SG_ 1071 XRSLBTargetSpeedRequest 100;
BA_ "GenSigStartValue" SG_ 1071 XRSLBTargetSpeedRequest 65535;
BA_ "GenSigCycleTime" SG_ 1068 EcoCruiseMinSpeedLev3 100;
BA_ "GenSigCycleTimeActive" SG_ 1068 EcoCruiseMinSpeedLev3 100;
BA_ "GenSigStartValue" SG_ 1068 EcoCruiseMinSpeedLev3 65535;
BA_ "Platform_VMCU1_Sig" SG_ 1068 EcoCruiseMinSpeedLev3 1;
BA_ "GenSigCycleTime" SG_ 1068 EcoCruiseMinSpeedLev0 100;
BA_ "GenSigCycleTimeActive" SG_ 1068 EcoCruiseMinSpeedLev0 100;
BA_ "GenSigStartValue" SG_ 1068 EcoCruiseMinSpeedLev0 65535;
BA_ "Platform_VMCU1_Sig" SG_ 1068 EcoCruiseMinSpeedLev0 1;
BA_ "GenSigCycleTime" SG_ 1068 EcoCruiseMinSpeedLev1 100;
BA_ "GenSigCycleTimeActive" SG_ 1068 EcoCruiseMinSpeedLev1 100;
BA_ "GenSigStartValue" SG_ 1068 EcoCruiseMinSpeedLev1 65535;
BA_ "Platform_VMCU1_Sig" SG_ 1068 EcoCruiseMinSpeedLev1 1;
BA_ "GenSigCycleTime" SG_ 1068 EcoCruiseMinSpeedLev2 100;
BA_ "GenSigCycleTimeActive" SG_ 1068 EcoCruiseMinSpeedLev2 100;
BA_ "GenSigStartValue" SG_ 1068 EcoCruiseMinSpeedLev2 65535;
BA_ "Platform_VMCU1_Sig" SG_ 1068 EcoCruiseMinSpeedLev2 1;
BA_ "GenSigCycleTime" SG_ 1065 EcoCruiseMaxSpeedLev1 100;
BA_ "GenSigCycleTimeActive" SG_ 1065 EcoCruiseMaxSpeedLev1 100;
BA_ "GenSigStartValue" SG_ 1065 EcoCruiseMaxSpeedLev1 65535;
BA_ "Platform_VMCU1_Sig" SG_ 1065 EcoCruiseMaxSpeedLev1 1;
BA_ "GenSigCycleTime" SG_ 1065 EcoCruiseMaxSpeedLev0 100;
BA_ "GenSigCycleTimeActive" SG_ 1065 EcoCruiseMaxSpeedLev0 100;
BA_ "GenSigStartValue" SG_ 1065 EcoCruiseMaxSpeedLev0 65535;
BA_ "Platform_VMCU1_Sig" SG_ 1065 EcoCruiseMaxSpeedLev0 1;
BA_ "GenSigCycleTime" SG_ 1065 EcoCruiseMaxSpeedLev2 100;
BA_ "GenSigCycleTimeActive" SG_ 1065 EcoCruiseMaxSpeedLev2 100;
BA_ "GenSigStartValue" SG_ 1065 EcoCruiseMaxSpeedLev2 65535;
BA_ "Platform_VMCU1_Sig" SG_ 1065 EcoCruiseMaxSpeedLev2 1;
BA_ "GenSigCycleTime" SG_ 1065 EcoCruiseMaxSpeedLev3 100;
BA_ "GenSigCycleTimeActive" SG_ 1065 EcoCruiseMaxSpeedLev3 100;
BA_ "GenSigStartValue" SG_ 1065 EcoCruiseMaxSpeedLev3 65535;
BA_ "Platform_VMCU1_Sig" SG_ 1065 EcoCruiseMaxSpeedLev3 1;
BA_ "GenSigCycleTime" SG_ 1062 EcoCruiseCCBSetSpeedLev2 100;
BA_ "GenSigCycleTimeActive" SG_ 1062 EcoCruiseCCBSetSpeedLev2 100;
BA_ "GenSigStartValue" SG_ 1062 EcoCruiseCCBSetSpeedLev2 65535;
BA_ "Platform_VMCU1_Sig" SG_ 1062 EcoCruiseCCBSetSpeedLev2 1;
BA_ "GenSigCycleTime" SG_ 1062 EcoCruiseCCBSetSpeedLev1 100;
BA_ "GenSigCycleTimeActive" SG_ 1062 EcoCruiseCCBSetSpeedLev1 100;
BA_ "GenSigStartValue" SG_ 1062 EcoCruiseCCBSetSpeedLev1 65535;
BA_ "Platform_VMCU1_Sig" SG_ 1062 EcoCruiseCCBSetSpeedLev1 1;
BA_ "GenSigCycleTime" SG_ 1062 EcoCruiseCCBSetSpeedLev3 100;
BA_ "GenSigCycleTimeActive" SG_ 1062 EcoCruiseCCBSetSpeedLev3 100;
BA_ "GenSigStartValue" SG_ 1062 EcoCruiseCCBSetSpeedLev3 65535;
BA_ "Platform_VMCU1_Sig" SG_ 1062 EcoCruiseCCBSetSpeedLev3 1;
BA_ "GenSigCycleTime" SG_ 1062 EcoCruiseCCBSetSpeedLev0 100;
BA_ "GenSigCycleTimeActive" SG_ 1062 EcoCruiseCCBSetSpeedLev0 100;
BA_ "GenSigStartValue" SG_ 1062 EcoCruiseCCBSetSpeedLev0 65535;
BA_ "Platform_VMCU1_Sig" SG_ 1062 EcoCruiseCCBSetSpeedLev0 1;
BA_ "GenSigCycleTime" SG_ 1404 EngineGreenAreaOutLNG_ISig_4 100;
BA_ "GenSigCycleTimeActive" SG_ 1404 EngineGreenAreaOutLNG_ISig_4 100;
BA_ "GenSigStartValue" SG_ 1404 EngineGreenAreaOutLNG_ISig_4 4294967295;
BA_ "Platform_VMCU1_Sig" SG_ 1404 EngineGreenAreaOutLNG_ISig_4 1;
BA_ "GenSigCycleTime" SG_ 1404 EngineGreenAreaLNG_ISig_4 100;
BA_ "GenSigCycleTimeActive" SG_ 1404 EngineGreenAreaLNG_ISig_4 100;
BA_ "GenSigStartValue" SG_ 1404 EngineGreenAreaLNG_ISig_4 4294967295;
BA_ "Platform_VMCU1_Sig" SG_ 1404 EngineGreenAreaLNG_ISig_4 1;
BA_ "GenSigCycleTime" SG_ 1035 BatteryTempAlert_rqst_ISig_4 100;
BA_ "GenSigCycleTimeActive" SG_ 1035 BatteryTempAlert_rqst_ISig_4 100;
BA_ "GenSigStartValue" SG_ 1035 BatteryTempAlert_rqst_ISig_4 7;
BA_ "Platform_VMCU1_Sig" SG_ 1035 BatteryTempAlert_rqst_ISig_4 1;
BA_ "GenSigCycleTime" SG_ 1035 APM_TrailerCircPressureStatus_IS 100;
BA_ "GenSigCycleTimeActive" SG_ 1035 APM_TrailerCircPressureStatus_IS 100;
BA_ "GenSigStartValue" SG_ 1035 APM_TrailerCircPressureStatus_IS 3;
BA_ "SystemSignalLongSymbol" SG_ 1035 APM_TrailerCircPressureStatus_IS "APM_TrailerCircPressureStatus_ISig_4";
BA_ "GenSigCycleTime" SG_ 1035 BatteryCapacity_ISig_4 100;
BA_ "GenSigCycleTimeActive" SG_ 1035 BatteryCapacity_ISig_4 100;
BA_ "GenSigStartValue" SG_ 1035 BatteryCapacity_ISig_4 15;
BA_ "Platform_VMCU1_Sig" SG_ 1035 BatteryCapacity_ISig_4 1;
BA_ "GenSigCycleTime" SG_ 1035 Hazard_rqst_ISig_4 100;
BA_ "GenSigCycleTimeActive" SG_ 1035 Hazard_rqst_ISig_4 100;
BA_ "GenSigStartValue" SG_ 1035 Hazard_rqst_ISig_4 3;
BA_ "SeToolAncestorID_SIGNAL" SG_ 1035 Hazard_rqst_ISig_4 "x0000001D04134A95";
BA_ "SeToolItemID_SIGNAL" SG_ 1035 Hazard_rqst_ISig_4 "x0000001D04134A95";
BA_ "SeToolName_SIGNAL" SG_ 1035 Hazard_rqst_ISig_4 "Hazard_rqst";
BA_ "SeToolVersion_SIGNAL" SG_ 1035 Hazard_rqst_ISig_4 "1";
BA_ "GenSigCycleTime" SG_ 1035 CollisionSituationAliveStatus 100;
BA_ "GenSigCycleTimeActive" SG_ 1035 CollisionSituationAliveStatus 100;
BA_ "GenSigStartValue" SG_ 1035 CollisionSituationAliveStatus 15;
BA_ "Platform_VMCU1_Sig" SG_ 1035 CollisionSituationAliveStatus 1;
BA_ "GenSigCycleTime" SG_ 1035 BatterySOCact_ISig_4 100;
BA_ "GenSigCycleTimeActive" SG_ 1035 BatterySOCact_ISig_4 100;
BA_ "GenSigStartValue" SG_ 1035 BatterySOCact_ISig_4 255;
BA_ "Platform_VMCU1_Sig" SG_ 1035 BatterySOCact_ISig_4 1;
BA_ "GenSigCycleTime" SG_ 1035 Trailer1TPMLostCom_ISig_4 100;
BA_ "GenSigCycleTimeActive" SG_ 1035 Trailer1TPMLostCom_ISig_4 100;
BA_ "GenSigStartValue" SG_ 1035 Trailer1TPMLostCom_ISig_4 3;
BA_ "NeedsUpdateBit" SG_ 1035 Trailer1TPMLostCom_ISig_4 1;
BA_ "Platform_VMCU1_Sig" SG_ 1035 Trailer1TPMLostCom_ISig_4 1;
BA_ "GenSigCycleTime" SG_ 1035 BatterySOCactCriticalAlert_ISig_ 100;
BA_ "GenSigCycleTimeActive" SG_ 1035 BatterySOCactCriticalAlert_ISig_ 100;
BA_ "GenSigStartValue" SG_ 1035 BatterySOCactCriticalAlert_ISig_ 255;
BA_ "Platform_VMCU1_Sig" SG_ 1035 BatterySOCactCriticalAlert_ISig_ 1;
BA_ "SystemSignalLongSymbol" SG_ 1035 BatterySOCactCriticalAlert_ISig_ "BatterySOCactCriticalAlert_ISig_4";
BA_ "GenSigCycleTime" SG_ 1035 BatteryTempAlertRawData_rqst_ISi 100;
BA_ "GenSigCycleTimeActive" SG_ 1035 BatteryTempAlertRawData_rqst_ISi 100;
BA_ "GenSigStartValue" SG_ 1035 BatteryTempAlertRawData_rqst_ISi 7;
BA_ "Platform_VMCU1_Sig" SG_ 1035 BatteryTempAlertRawData_rqst_ISi 1;
BA_ "SystemSignalLongSymbol" SG_ 1035 BatteryTempAlertRawData_rqst_ISi "BatteryTempAlertRawData_rqst_ISig_4";
BA_ "GenSigCycleTime" SG_ 1035 FPBRMMIStat_FPBRChangeAck_ISig_4 100;
BA_ "GenSigCycleTimeActive" SG_ 1035 FPBRMMIStat_FPBRChangeAck_ISig_4 100;
BA_ "GenSigStartValue" SG_ 1035 FPBRMMIStat_FPBRChangeAck_ISig_4 3;
BA_ "Platform_VMCU1_Sig" SG_ 1035 FPBRMMIStat_FPBRChangeAck_ISig_4 1;
BA_ "GenSigSendType" SG_ 1035 Trailer2TPMLostCom_UB_ISig_4 7;
BA_ "GenSigCycleTime" SG_ 1035 Trailer2TPMLostCom_UB_ISig_4 100;
BA_ "GenSigCycleTimeActive" SG_ 1035 Trailer2TPMLostCom_UB_ISig_4 100;
BA_ "Platform_VMCU1_Sig" SG_ 1035 Trailer2TPMLostCom_UB_ISig_4 1;
BA_ "GenSigCycleTime" SG_ 1035 LivBatteryCharging_stat_ISig_4 100;
BA_ "GenSigCycleTimeActive" SG_ 1035 LivBatteryCharging_stat_ISig_4 100;
BA_ "GenSigStartValue" SG_ 1035 LivBatteryCharging_stat_ISig_4 3;
BA_ "GenSigCycleTime" SG_ 1035 BatteryTemp_ISig_4 100;
BA_ "GenSigCycleTimeActive" SG_ 1035 BatteryTemp_ISig_4 100;
BA_ "GenSigStartValue" SG_ 1035 BatteryTemp_ISig_4 255;
BA_ "Platform_VMCU1_Sig" SG_ 1035 BatteryTemp_ISig_4 1;
BA_ "GenSigSendType" SG_ 1035 Trailer1TPMLostCom_UB_ISig_4 7;
BA_ "GenSigCycleTime" SG_ 1035 Trailer1TPMLostCom_UB_ISig_4 100;
BA_ "GenSigCycleTimeActive" SG_ 1035 Trailer1TPMLostCom_UB_ISig_4 100;
BA_ "Platform_VMCU1_Sig" SG_ 1035 Trailer1TPMLostCom_UB_ISig_4 1;
BA_ "GenSigCycleTime" SG_ 1035 FPBRMMIStat_FPBRStatusInd_ISig_4 100;
BA_ "GenSigCycleTimeActive" SG_ 1035 FPBRMMIStat_FPBRStatusInd_ISig_4 100;
BA_ "GenSigStartValue" SG_ 1035 FPBRMMIStat_FPBRStatusInd_ISig_4 3;
BA_ "Platform_VMCU1_Sig" SG_ 1035 FPBRMMIStat_FPBRStatusInd_ISig_4 1;
BA_ "GenSigCycleTime" SG_ 1035 RS_WasherStatus_ISig_4 100;
BA_ "GenSigCycleTimeActive" SG_ 1035 RS_WasherStatus_ISig_4 100;
BA_ "GenSigStartValue" SG_ 1035 RS_WasherStatus_ISig_4 3;
BA_ "GenSigCycleTime" SG_ 1035 Trailer2TPMLostCom_ISig_4 100;
BA_ "GenSigCycleTimeActive" SG_ 1035 Trailer2TPMLostCom_ISig_4 100;
BA_ "GenSigStartValue" SG_ 1035 Trailer2TPMLostCom_ISig_4 3;
BA_ "NeedsUpdateBit" SG_ 1035 Trailer2TPMLostCom_ISig_4 1;
BA_ "Platform_VMCU1_Sig" SG_ 1035 Trailer2TPMLostCom_ISig_4 1;
BA_ "GenSigCycleTime" SG_ 1035 Rainsensor_Indication_ISig_4 100;
BA_ "GenSigCycleTimeActive" SG_ 1035 Rainsensor_Indication_ISig_4 100;
BA_ "GenSigStartValue" SG_ 1035 Rainsensor_Indication_ISig_4 3;
BA_ "GenSigCycleTime" SG_ 1035 CollisionSituationAliveRequest 100;
BA_ "GenSigCycleTimeActive" SG_ 1035 CollisionSituationAliveRequest 100;
BA_ "GenSigStartValue" SG_ 1035 CollisionSituationAliveRequest 15;
BA_ "Platform_VMCU1_Sig" SG_ 1035 CollisionSituationAliveRequest 1;
BA_ "GenSigCycleTime" SG_ 1032 TPMMateTrailerResp_ISig_4 100;
BA_ "GenSigCycleTimeActive" SG_ 1032 TPMMateTrailerResp_ISig_4 100;
BA_ "GenSigStartValue" SG_ 1032 TPMMateTrailerResp_ISig_4 7;
BA_ "NeedsUpdateBit" SG_ 1032 TPMMateTrailerResp_ISig_4 1;
BA_ "Platform_VMCU1_Sig" SG_ 1032 TPMMateTrailerResp_ISig_4 1;
BA_ "GenSigCycleTime" SG_ 1032 Trailer2TPMLeakageWarning_ISig_4 100;
BA_ "GenSigCycleTimeActive" SG_ 1032 Trailer2TPMLeakageWarning_ISig_4 100;
BA_ "GenSigStartValue" SG_ 1032 Trailer2TPMLeakageWarning_ISig_4 7;
BA_ "NeedsUpdateBit" SG_ 1032 Trailer2TPMLeakageWarning_ISig_4 1;
BA_ "Platform_VMCU1_Sig" SG_ 1032 Trailer2TPMLeakageWarning_ISig_4 1;
BA_ "GenSigCycleTime" SG_ 1032 TPMAutomaticMating_ISig_4 100;
BA_ "GenSigCycleTimeActive" SG_ 1032 TPMAutomaticMating_ISig_4 100;
BA_ "GenSigStartValue" SG_ 1032 TPMAutomaticMating_ISig_4 3;
BA_ "Platform_VMCU1_Sig" SG_ 1032 TPMAutomaticMating_ISig_4 1;
BA_ "GenSigSendType" SG_ 1032 Trailer2TPMPressureWarning_UB_IS 7;
BA_ "GenSigCycleTime" SG_ 1032 Trailer2TPMPressureWarning_UB_IS 100;
BA_ "GenSigCycleTimeActive" SG_ 1032 Trailer2TPMPressureWarning_UB_IS 100;
BA_ "Platform_VMCU1_Sig" SG_ 1032 Trailer2TPMPressureWarning_UB_IS 1;
BA_ "SystemSignalLongSymbol" SG_ 1032 Trailer2TPMPressureWarning_UB_IS "Trailer2TPMPressureWarning_UB_ISig_4";
BA_ "GenSigCycleTime" SG_ 1032 DirectionIndicatorLightsStatus_I 100;
BA_ "GenSigCycleTimeActive" SG_ 1032 DirectionIndicatorLightsStatus_I 100;
BA_ "GenSigStartValue" SG_ 1032 DirectionIndicatorLightsStatus_I 15;
BA_ "SystemSignalLongSymbol" SG_ 1032 DirectionIndicatorLightsStatus_I "DirectionIndicatorLightsStatus_ISig_4";
BA_ "GenSigCycleTime" SG_ 1032 FrontWheelDifflockRequest_ISig_4 100;
BA_ "GenSigCycleTimeActive" SG_ 1032 FrontWheelDifflockRequest_ISig_4 100;
BA_ "GenSigStartValue" SG_ 1032 FrontWheelDifflockRequest_ISig_4 3;
BA_ "GenSigSendType" SG_ 1032 TruckTPMLeakageWarning_UB_ISig_4 7;
BA_ "GenSigCycleTime" SG_ 1032 TruckTPMLeakageWarning_UB_ISig_4 100;
BA_ "GenSigCycleTimeActive" SG_ 1032 TruckTPMLeakageWarning_UB_ISig_4 100;
BA_ "Platform_VMCU1_Sig" SG_ 1032 TruckTPMLeakageWarning_UB_ISig_4 1;
BA_ "GenSigCycleTime" SG_ 1032 Trailer2TPMMatedStatus_ISig_4 100;
BA_ "GenSigCycleTimeActive" SG_ 1032 Trailer2TPMMatedStatus_ISig_4 100;
BA_ "GenSigStartValue" SG_ 1032 Trailer2TPMMatedStatus_ISig_4 3;
BA_ "Platform_VMCU1_Sig" SG_ 1032 Trailer2TPMMatedStatus_ISig_4 1;
BA_ "GenSigCycleTime" SG_ 1032 Trailer1TPMMatedStatus_ISig_4 100;
BA_ "GenSigCycleTimeActive" SG_ 1032 Trailer1TPMMatedStatus_ISig_4 100;
BA_ "GenSigStartValue" SG_ 1032 Trailer1TPMMatedStatus_ISig_4 3;
BA_ "Platform_VMCU1_Sig" SG_ 1032 Trailer1TPMMatedStatus_ISig_4 1;
BA_ "GenSigSendType" SG_ 1032 Trailer2TPMLeakageWarning_UB_ISi 7;
BA_ "GenSigCycleTime" SG_ 1032 Trailer2TPMLeakageWarning_UB_ISi 100;
BA_ "GenSigCycleTimeActive" SG_ 1032 Trailer2TPMLeakageWarning_UB_ISi 100;
BA_ "Platform_VMCU1_Sig" SG_ 1032 Trailer2TPMLeakageWarning_UB_ISi 1;
BA_ "SystemSignalLongSymbol" SG_ 1032 Trailer2TPMLeakageWarning_UB_ISi "Trailer2TPMLeakageWarning_UB_ISig_4";
BA_ "GenSigCycleTime" SG_ 1032 CargoLoadResetFeedback 100;
BA_ "GenSigCycleTimeActive" SG_ 1032 CargoLoadResetFeedback 100;
BA_ "GenSigStartValue" SG_ 1032 CargoLoadResetFeedback 3;
BA_ "GenSigSendType" SG_ 1032 Trailer1TPMLeakageWarning_UB_ISi 7;
BA_ "GenSigCycleTime" SG_ 1032 Trailer1TPMLeakageWarning_UB_ISi 100;
BA_ "GenSigCycleTimeActive" SG_ 1032 Trailer1TPMLeakageWarning_UB_ISi 100;
BA_ "Platform_VMCU1_Sig" SG_ 1032 Trailer1TPMLeakageWarning_UB_ISi 1;
BA_ "SystemSignalLongSymbol" SG_ 1032 Trailer1TPMLeakageWarning_UB_ISi "Trailer1TPMLeakageWarning_UB_ISig_4";
BA_ "GenSigCycleTime" SG_ 1032 TruckTPMLeakageWarning_ISig_4 100;
BA_ "GenSigCycleTimeActive" SG_ 1032 TruckTPMLeakageWarning_ISig_4 100;
BA_ "GenSigStartValue" SG_ 1032 TruckTPMLeakageWarning_ISig_4 7;
BA_ "NeedsUpdateBit" SG_ 1032 TruckTPMLeakageWarning_ISig_4 1;
BA_ "Platform_VMCU1_Sig" SG_ 1032 TruckTPMLeakageWarning_ISig_4 1;
BA_ "GenSigSendType" SG_ 1032 Trailer1TPMPressureWarning_UB_IS 7;
BA_ "GenSigCycleTime" SG_ 1032 Trailer1TPMPressureWarning_UB_IS 100;
BA_ "GenSigCycleTimeActive" SG_ 1032 Trailer1TPMPressureWarning_UB_IS 100;
BA_ "Platform_VMCU1_Sig" SG_ 1032 Trailer1TPMPressureWarning_UB_IS 1;
BA_ "SystemSignalLongSymbol" SG_ 1032 Trailer1TPMPressureWarning_UB_IS "Trailer1TPMPressureWarning_UB_ISig_4";
BA_ "GenSigCycleTime" SG_ 1032 ExtraSideMarkers_FunctStat 100;
BA_ "GenSigCycleTimeActive" SG_ 1032 ExtraSideMarkers_FunctStat 100;
BA_ "GenSigStartValue" SG_ 1032 ExtraSideMarkers_FunctStat 3;
BA_ "Platform_VMCU1_Sig" SG_ 1032 ExtraSideMarkers_FunctStat 1;
BA_ "GenSigSendType" SG_ 1032 TruckTPMPressureWarning_UB_ISig_ 7;
BA_ "GenSigCycleTime" SG_ 1032 TruckTPMPressureWarning_UB_ISig_ 100;
BA_ "GenSigCycleTimeActive" SG_ 1032 TruckTPMPressureWarning_UB_ISig_ 100;
BA_ "Platform_VMCU1_Sig" SG_ 1032 TruckTPMPressureWarning_UB_ISig_ 1;
BA_ "SystemSignalLongSymbol" SG_ 1032 TruckTPMPressureWarning_UB_ISig_ "TruckTPMPressureWarning_UB_ISig_4";
BA_ "GenSigCycleTime" SG_ 1032 Trailer2TPMPressureWarning_ISig_ 100;
BA_ "GenSigCycleTimeActive" SG_ 1032 Trailer2TPMPressureWarning_ISig_ 100;
BA_ "GenSigStartValue" SG_ 1032 Trailer2TPMPressureWarning_ISig_ 7;
BA_ "NeedsUpdateBit" SG_ 1032 Trailer2TPMPressureWarning_ISig_ 1;
BA_ "Platform_VMCU1_Sig" SG_ 1032 Trailer2TPMPressureWarning_ISig_ 1;
BA_ "SystemSignalLongSymbol" SG_ 1032 Trailer2TPMPressureWarning_ISig_ "Trailer2TPMPressureWarning_ISig_4";
BA_ "GenSigCycleTime" SG_ 1032 XRSLActive 100;
BA_ "GenSigCycleTimeActive" SG_ 1032 XRSLActive 100;
BA_ "GenSigStartValue" SG_ 1032 XRSLActive 3;
BA_ "GenSigCycleTime" SG_ 1032 Trailer1TPMPressureWarning_ISig_ 100;
BA_ "GenSigCycleTimeActive" SG_ 1032 Trailer1TPMPressureWarning_ISig_ 100;
BA_ "GenSigStartValue" SG_ 1032 Trailer1TPMPressureWarning_ISig_ 7;
BA_ "NeedsUpdateBit" SG_ 1032 Trailer1TPMPressureWarning_ISig_ 1;
BA_ "Platform_VMCU1_Sig" SG_ 1032 Trailer1TPMPressureWarning_ISig_ 1;
BA_ "SystemSignalLongSymbol" SG_ 1032 Trailer1TPMPressureWarning_ISig_ "Trailer1TPMPressureWarning_ISig_4";
BA_ "GenSigCycleTime" SG_ 1032 Trailer1TPMLeakageWarning_ISig_4 100;
BA_ "GenSigCycleTimeActive" SG_ 1032 Trailer1TPMLeakageWarning_ISig_4 100;
BA_ "GenSigStartValue" SG_ 1032 Trailer1TPMLeakageWarning_ISig_4 7;
BA_ "NeedsUpdateBit" SG_ 1032 Trailer1TPMLeakageWarning_ISig_4 1;
BA_ "Platform_VMCU1_Sig" SG_ 1032 Trailer1TPMLeakageWarning_ISig_4 1;
BA_ "GenSigCycleTime" SG_ 1032 LiftAxle1RequestResponse 100;
BA_ "GenSigCycleTimeActive" SG_ 1032 LiftAxle1RequestResponse 100;
BA_ "GenSigStartValue" SG_ 1032 LiftAxle1RequestResponse 15;
BA_ "Platform_VMCU1_Sig" SG_ 1032 LiftAxle1RequestResponse 1;
BA_ "GenSigCycleTime" SG_ 1032 TruckTPMPressureWarning_ISig_4 100;
BA_ "GenSigCycleTimeActive" SG_ 1032 TruckTPMPressureWarning_ISig_4 100;
BA_ "GenSigStartValue" SG_ 1032 TruckTPMPressureWarning_ISig_4 7;
BA_ "NeedsUpdateBit" SG_ 1032 TruckTPMPressureWarning_ISig_4 1;
BA_ "Platform_VMCU1_Sig" SG_ 1032 TruckTPMPressureWarning_ISig_4 1;
BA_ "GenSigCycleTime" SG_ 1032 XRSLIndication 100;
BA_ "GenSigCycleTimeActive" SG_ 1032 XRSLIndication 100;
BA_ "GenSigStartValue" SG_ 1032 XRSLIndication 255;
BA_ "Platform_VMCU1_Sig" SG_ 1032 XRSLIndication 1;
BA_ "GenSigSendType" SG_ 1032 TPMMateTrailerResp_UB_ISig_4 7;
BA_ "GenSigCycleTime" SG_ 1032 TPMMateTrailerResp_UB_ISig_4 100;
BA_ "GenSigCycleTimeActive" SG_ 1032 TPMMateTrailerResp_UB_ISig_4 100;
BA_ "Platform_VMCU1_Sig" SG_ 1032 TPMMateTrailerResp_UB_ISig_4 1;
BA_ "GenSigCycleTime" SG_ 1237 Trailer2TPMFailure_ISig_4 100;
BA_ "GenSigCycleTimeActive" SG_ 1237 Trailer2TPMFailure_ISig_4 100;
BA_ "GenSigStartValue" SG_ 1237 Trailer2TPMFailure_ISig_4 3;
BA_ "Platform_VMCU1_Sig" SG_ 1237 Trailer2TPMFailure_ISig_4 1;
BA_ "GenSigCycleTime" SG_ 1237 TruckTPMTireInfo_Active_ISig_4 100;
BA_ "GenSigCycleTimeActive" SG_ 1237 TruckTPMTireInfo_Active_ISig_4 100;
BA_ "GenSigStartValue" SG_ 1237 TruckTPMTireInfo_Active_ISig_4 3;
BA_ "NeedsUpdateBit" SG_ 1237 TruckTPMTireInfo_Active_ISig_4 1;
BA_ "Platform_VMCU1_Sig" SG_ 1237 TruckTPMTireInfo_Active_ISig_4 1;
BA_ "GenSigCycleTime" SG_ 1237 TruckTPMFailure_ISig_4 100;
BA_ "GenSigCycleTimeActive" SG_ 1237 TruckTPMFailure_ISig_4 100;
BA_ "GenSigStartValue" SG_ 1237 TruckTPMFailure_ISig_4 3;
BA_ "Platform_VMCU1_Sig" SG_ 1237 TruckTPMFailure_ISig_4 1;
BA_ "GenSigCycleTime" SG_ 1237 TruckTPMTireInfo_TireId_ISig_4 100;
BA_ "GenSigCycleTimeActive" SG_ 1237 TruckTPMTireInfo_TireId_ISig_4 100;
BA_ "NeedsUpdateBit" SG_ 1237 TruckTPMTireInfo_TireId_ISig_4 1;
BA_ "Platform_VMCU1_Sig" SG_ 1237 TruckTPMTireInfo_TireId_ISig_4 1;
BA_ "GenSigCycleTime" SG_ 1237 TruckTPMTireInfo_Battery_ISig_4 100;
BA_ "GenSigCycleTimeActive" SG_ 1237 TruckTPMTireInfo_Battery_ISig_4 100;
BA_ "GenSigStartValue" SG_ 1237 TruckTPMTireInfo_Battery_ISig_4 7;
BA_ "NeedsUpdateBit" SG_ 1237 TruckTPMTireInfo_Battery_ISig_4 1;
BA_ "Platform_VMCU1_Sig" SG_ 1237 TruckTPMTireInfo_Battery_ISig_4 1;
BA_ "GenSigSendType" SG_ 1237 TruckTPMTireInfo_sg_UB_ISig_4 7;
BA_ "GenSigCycleTime" SG_ 1237 TruckTPMTireInfo_sg_UB_ISig_4 100;
BA_ "GenSigCycleTimeActive" SG_ 1237 TruckTPMTireInfo_sg_UB_ISig_4 100;
BA_ "Platform_VMCU1_Sig" SG_ 1237 TruckTPMTireInfo_sg_UB_ISig_4 1;
BA_ "GenSigCycleTime" SG_ 1237 TruckTPMTireInfo_Temperature_ISi 100;
BA_ "GenSigCycleTimeActive" SG_ 1237 TruckTPMTireInfo_Temperature_ISi 100;
BA_ "GenSigStartValue" SG_ 1237 TruckTPMTireInfo_Temperature_ISi 255;
BA_ "NeedsUpdateBit" SG_ 1237 TruckTPMTireInfo_Temperature_ISi 1;
BA_ "Platform_VMCU1_Sig" SG_ 1237 TruckTPMTireInfo_Temperature_ISi 1;
BA_ "SystemSignalLongSymbol" SG_ 1237 TruckTPMTireInfo_Temperature_ISi "TruckTPMTireInfo_Temperature_ISig_4";
BA_ "GenSigCycleTime" SG_ 1237 TruckTPMTireInfo_RefPres_ISig_4 100;
BA_ "GenSigCycleTimeActive" SG_ 1237 TruckTPMTireInfo_RefPres_ISig_4 100;
BA_ "GenSigStartValue" SG_ 1237 TruckTPMTireInfo_RefPres_ISig_4 255;
BA_ "NeedsUpdateBit" SG_ 1237 TruckTPMTireInfo_RefPres_ISig_4 1;
BA_ "Platform_VMCU1_Sig" SG_ 1237 TruckTPMTireInfo_RefPres_ISig_4 1;
BA_ "GenSigCycleTime" SG_ 1237 TPMTrailerPositionStat_ISig_4 100;
BA_ "GenSigCycleTimeActive" SG_ 1237 TPMTrailerPositionStat_ISig_4 100;
BA_ "GenSigStartValue" SG_ 1237 TPMTrailerPositionStat_ISig_4 3;
BA_ "Platform_VMCU1_Sig" SG_ 1237 TPMTrailerPositionStat_ISig_4 1;
BA_ "GenSigCycleTime" SG_ 1237 TruckTPMTireInfo_Pressure_ISig_4 100;
BA_ "GenSigCycleTimeActive" SG_ 1237 TruckTPMTireInfo_Pressure_ISig_4 100;
BA_ "GenSigStartValue" SG_ 1237 TruckTPMTireInfo_Pressure_ISig_4 255;
BA_ "NeedsUpdateBit" SG_ 1237 TruckTPMTireInfo_Pressure_ISig_4 1;
BA_ "Platform_VMCU1_Sig" SG_ 1237 TruckTPMTireInfo_Pressure_ISig_4 1;
BA_ "GenSigCycleTime" SG_ 1237 Trailer1TPMFailure_ISig_4 100;
BA_ "GenSigCycleTimeActive" SG_ 1237 Trailer1TPMFailure_ISig_4 100;
BA_ "GenSigStartValue" SG_ 1237 Trailer1TPMFailure_ISig_4 3;
BA_ "Platform_VMCU1_Sig" SG_ 1237 Trailer1TPMFailure_ISig_4 1;
BA_ "GenSigCycleTime" SG_ 1237 TruckTPMTireInfo_PresWarn_ISig_4 100;
BA_ "GenSigCycleTimeActive" SG_ 1237 TruckTPMTireInfo_PresWarn_ISig_4 100;
BA_ "GenSigStartValue" SG_ 1237 TruckTPMTireInfo_PresWarn_ISig_4 7;
BA_ "NeedsUpdateBit" SG_ 1237 TruckTPMTireInfo_PresWarn_ISig_4 1;
BA_ "Platform_VMCU1_Sig" SG_ 1237 TruckTPMTireInfo_PresWarn_ISig_4 1;
BA_ "GenSigCycleTime" SG_ 1237 TruckTPMTireInfo_LeakageWarn_ISi 100;
BA_ "GenSigCycleTimeActive" SG_ 1237 TruckTPMTireInfo_LeakageWarn_ISi 100;
BA_ "GenSigStartValue" SG_ 1237 TruckTPMTireInfo_LeakageWarn_ISi 7;
BA_ "NeedsUpdateBit" SG_ 1237 TruckTPMTireInfo_LeakageWarn_ISi 1;
BA_ "Platform_VMCU1_Sig" SG_ 1237 TruckTPMTireInfo_LeakageWarn_ISi 1;
BA_ "SystemSignalLongSymbol" SG_ 1237 TruckTPMTireInfo_LeakageWarn_ISi "TruckTPMTireInfo_LeakageWarn_ISig_4";
BA_ "GenSigCycleTime" SG_ 1234 Trailer2TPMTireInfo_LeakageWarn_ 100;
BA_ "GenSigCycleTimeActive" SG_ 1234 Trailer2TPMTireInfo_LeakageWarn_ 100;
BA_ "GenSigStartValue" SG_ 1234 Trailer2TPMTireInfo_LeakageWarn_ 7;
BA_ "NeedsUpdateBit" SG_ 1234 Trailer2TPMTireInfo_LeakageWarn_ 1;
BA_ "Platform_VMCU1_Sig" SG_ 1234 Trailer2TPMTireInfo_LeakageWarn_ 1;
BA_ "SystemSignalLongSymbol" SG_ 1234 Trailer2TPMTireInfo_LeakageWarn_ "Trailer2TPMTireInfo_LeakageWarn_ISig_4";
BA_ "GenSigCycleTime" SG_ 1234 Trailer2TPMTireInfo_RefPres_ISig 100;
BA_ "GenSigCycleTimeActive" SG_ 1234 Trailer2TPMTireInfo_RefPres_ISig 100;
BA_ "GenSigStartValue" SG_ 1234 Trailer2TPMTireInfo_RefPres_ISig 255;
BA_ "NeedsUpdateBit" SG_ 1234 Trailer2TPMTireInfo_RefPres_ISig 1;
BA_ "Platform_VMCU1_Sig" SG_ 1234 Trailer2TPMTireInfo_RefPres_ISig 1;
BA_ "SystemSignalLongSymbol" SG_ 1234 Trailer2TPMTireInfo_RefPres_ISig "Trailer2TPMTireInfo_RefPres_ISig_4";
BA_ "GenSigCycleTime" SG_ 1234 Trailer2TPMTireInfo_PresWarn_ISi 100;
BA_ "GenSigCycleTimeActive" SG_ 1234 Trailer2TPMTireInfo_PresWarn_ISi 100;
BA_ "GenSigStartValue" SG_ 1234 Trailer2TPMTireInfo_PresWarn_ISi 7;
BA_ "NeedsUpdateBit" SG_ 1234 Trailer2TPMTireInfo_PresWarn_ISi 1;
BA_ "Platform_VMCU1_Sig" SG_ 1234 Trailer2TPMTireInfo_PresWarn_ISi 1;
BA_ "SystemSignalLongSymbol" SG_ 1234 Trailer2TPMTireInfo_PresWarn_ISi "Trailer2TPMTireInfo_PresWarn_ISig_4";
BA_ "GenSigCycleTime" SG_ 1234 Trailer2TPMTireInfo_Pressure_ISi 100;
BA_ "GenSigCycleTimeActive" SG_ 1234 Trailer2TPMTireInfo_Pressure_ISi 100;
BA_ "GenSigStartValue" SG_ 1234 Trailer2TPMTireInfo_Pressure_ISi 255;
BA_ "NeedsUpdateBit" SG_ 1234 Trailer2TPMTireInfo_Pressure_ISi 1;
BA_ "Platform_VMCU1_Sig" SG_ 1234 Trailer2TPMTireInfo_Pressure_ISi 1;
BA_ "SystemSignalLongSymbol" SG_ 1234 Trailer2TPMTireInfo_Pressure_ISi "Trailer2TPMTireInfo_Pressure_ISig_4";
BA_ "GenSigCycleTime" SG_ 1234 Trailer2TPMTireInfo_Temperature_ 100;
BA_ "GenSigCycleTimeActive" SG_ 1234 Trailer2TPMTireInfo_Temperature_ 100;
BA_ "GenSigStartValue" SG_ 1234 Trailer2TPMTireInfo_Temperature_ 255;
BA_ "NeedsUpdateBit" SG_ 1234 Trailer2TPMTireInfo_Temperature_ 1;
BA_ "Platform_VMCU1_Sig" SG_ 1234 Trailer2TPMTireInfo_Temperature_ 1;
BA_ "SystemSignalLongSymbol" SG_ 1234 Trailer2TPMTireInfo_Temperature_ "Trailer2TPMTireInfo_Temperature_ISig_4";
BA_ "GenSigSendType" SG_ 1234 Trailer2TPMTireInfo_sg_UB_ISig_4 7;
BA_ "GenSigCycleTime" SG_ 1234 Trailer2TPMTireInfo_sg_UB_ISig_4 100;
BA_ "GenSigCycleTimeActive" SG_ 1234 Trailer2TPMTireInfo_sg_UB_ISig_4 100;
BA_ "Platform_VMCU1_Sig" SG_ 1234 Trailer2TPMTireInfo_sg_UB_ISig_4 1;
BA_ "GenSigCycleTime" SG_ 1234 Trailer2TPMTireInfo_TireId_ISig_ 100;
BA_ "GenSigCycleTimeActive" SG_ 1234 Trailer2TPMTireInfo_TireId_ISig_ 100;
BA_ "NeedsUpdateBit" SG_ 1234 Trailer2TPMTireInfo_TireId_ISig_ 1;
BA_ "Platform_VMCU1_Sig" SG_ 1234 Trailer2TPMTireInfo_TireId_ISig_ 1;
BA_ "SystemSignalLongSymbol" SG_ 1234 Trailer2TPMTireInfo_TireId_ISig_ "Trailer2TPMTireInfo_TireId_ISig_4";
BA_ "GenSigCycleTime" SG_ 1234 Trailer2TPMTireInfo_Battery_ISig 100;
BA_ "GenSigCycleTimeActive" SG_ 1234 Trailer2TPMTireInfo_Battery_ISig 100;
BA_ "GenSigStartValue" SG_ 1234 Trailer2TPMTireInfo_Battery_ISig 7;
BA_ "NeedsUpdateBit" SG_ 1234 Trailer2TPMTireInfo_Battery_ISig 1;
BA_ "Platform_VMCU1_Sig" SG_ 1234 Trailer2TPMTireInfo_Battery_ISig 1;
BA_ "SystemSignalLongSymbol" SG_ 1234 Trailer2TPMTireInfo_Battery_ISig "Trailer2TPMTireInfo_Battery_ISig_4";
BA_ "GenSigCycleTime" SG_ 1234 Trailer2TPMTireInfo_Active_ISig_ 100;
BA_ "GenSigCycleTimeActive" SG_ 1234 Trailer2TPMTireInfo_Active_ISig_ 100;
BA_ "GenSigStartValue" SG_ 1234 Trailer2TPMTireInfo_Active_ISig_ 3;
BA_ "NeedsUpdateBit" SG_ 1234 Trailer2TPMTireInfo_Active_ISig_ 1;
BA_ "Platform_VMCU1_Sig" SG_ 1234 Trailer2TPMTireInfo_Active_ISig_ 1;
BA_ "SystemSignalLongSymbol" SG_ 1234 Trailer2TPMTireInfo_Active_ISig_ "Trailer2TPMTireInfo_Active_ISig_4";
BA_ "GenSigCycleTime" SG_ 1231 Trailer1TPMTireInfo_Battery_ISig 100;
BA_ "GenSigCycleTimeActive" SG_ 1231 Trailer1TPMTireInfo_Battery_ISig 100;
BA_ "GenSigStartValue" SG_ 1231 Trailer1TPMTireInfo_Battery_ISig 7;
BA_ "NeedsUpdateBit" SG_ 1231 Trailer1TPMTireInfo_Battery_ISig 1;
BA_ "Platform_VMCU1_Sig" SG_ 1231 Trailer1TPMTireInfo_Battery_ISig 1;
BA_ "SystemSignalLongSymbol" SG_ 1231 Trailer1TPMTireInfo_Battery_ISig "Trailer1TPMTireInfo_Battery_ISig_4";
BA_ "GenSigSendType" SG_ 1231 Trailer1TPMTireInfo_sg_UB_ISig_4 7;
BA_ "GenSigCycleTime" SG_ 1231 Trailer1TPMTireInfo_sg_UB_ISig_4 100;
BA_ "GenSigCycleTimeActive" SG_ 1231 Trailer1TPMTireInfo_sg_UB_ISig_4 100;
BA_ "Platform_VMCU1_Sig" SG_ 1231 Trailer1TPMTireInfo_sg_UB_ISig_4 1;
BA_ "GenSigCycleTime" SG_ 1231 Trailer1TPMTireInfo_Pressure_ISi 100;
BA_ "GenSigCycleTimeActive" SG_ 1231 Trailer1TPMTireInfo_Pressure_ISi 100;
BA_ "GenSigStartValue" SG_ 1231 Trailer1TPMTireInfo_Pressure_ISi 255;
BA_ "NeedsUpdateBit" SG_ 1231 Trailer1TPMTireInfo_Pressure_ISi 1;
BA_ "Platform_VMCU1_Sig" SG_ 1231 Trailer1TPMTireInfo_Pressure_ISi 1;
BA_ "SystemSignalLongSymbol" SG_ 1231 Trailer1TPMTireInfo_Pressure_ISi "Trailer1TPMTireInfo_Pressure_ISig_4";
BA_ "GenSigCycleTime" SG_ 1231 Trailer1TPMTireInfo_PresWarn_ISi 100;
BA_ "GenSigCycleTimeActive" SG_ 1231 Trailer1TPMTireInfo_PresWarn_ISi 100;
BA_ "GenSigStartValue" SG_ 1231 Trailer1TPMTireInfo_PresWarn_ISi 7;
BA_ "NeedsUpdateBit" SG_ 1231 Trailer1TPMTireInfo_PresWarn_ISi 1;
BA_ "Platform_VMCU1_Sig" SG_ 1231 Trailer1TPMTireInfo_PresWarn_ISi 1;
BA_ "SystemSignalLongSymbol" SG_ 1231 Trailer1TPMTireInfo_PresWarn_ISi "Trailer1TPMTireInfo_PresWarn_ISig_4";
BA_ "GenSigCycleTime" SG_ 1231 Trailer1TPMTireInfo_LeakageWarn_ 100;
BA_ "GenSigCycleTimeActive" SG_ 1231 Trailer1TPMTireInfo_LeakageWarn_ 100;
BA_ "GenSigStartValue" SG_ 1231 Trailer1TPMTireInfo_LeakageWarn_ 7;
BA_ "NeedsUpdateBit" SG_ 1231 Trailer1TPMTireInfo_LeakageWarn_ 1;
BA_ "Platform_VMCU1_Sig" SG_ 1231 Trailer1TPMTireInfo_LeakageWarn_ 1;
BA_ "SystemSignalLongSymbol" SG_ 1231 Trailer1TPMTireInfo_LeakageWarn_ "Trailer1TPMTireInfo_LeakageWarn_ISig_4";
BA_ "GenSigSendType" SG_ 1231 TPMPosOfWMResp_sg_UB_ISig_4 7;
BA_ "GenSigCycleTime" SG_ 1231 TPMPosOfWMResp_sg_UB_ISig_4 100;
BA_ "GenSigCycleTimeActive" SG_ 1231 TPMPosOfWMResp_sg_UB_ISig_4 100;
BA_ "Platform_VMCU1_Sig" SG_ 1231 TPMPosOfWMResp_sg_UB_ISig_4 1;
BA_ "GenSigCycleTime" SG_ 1231 TPMPosOfWMResp_VehiclePos_ISig_4 100;
BA_ "GenSigCycleTimeActive" SG_ 1231 TPMPosOfWMResp_VehiclePos_ISig_4 100;
BA_ "GenSigStartValue" SG_ 1231 TPMPosOfWMResp_VehiclePos_ISig_4 7;
BA_ "NeedsUpdateBit" SG_ 1231 TPMPosOfWMResp_VehiclePos_ISig_4 1;
BA_ "Platform_VMCU1_Sig" SG_ 1231 TPMPosOfWMResp_VehiclePos_ISig_4 1;
BA_ "GenSigCycleTime" SG_ 1231 Trailer1TPMTireInfo_TireId_ISig_ 100;
BA_ "GenSigCycleTimeActive" SG_ 1231 Trailer1TPMTireInfo_TireId_ISig_ 100;
BA_ "NeedsUpdateBit" SG_ 1231 Trailer1TPMTireInfo_TireId_ISig_ 1;
BA_ "Platform_VMCU1_Sig" SG_ 1231 Trailer1TPMTireInfo_TireId_ISig_ 1;
BA_ "SystemSignalLongSymbol" SG_ 1231 Trailer1TPMTireInfo_TireId_ISig_ "Trailer1TPMTireInfo_TireId_ISig_4";
BA_ "GenSigCycleTime" SG_ 1231 Trailer1TPMTireInfo_RefPres_ISig 100;
BA_ "GenSigCycleTimeActive" SG_ 1231 Trailer1TPMTireInfo_RefPres_ISig 100;
BA_ "GenSigStartValue" SG_ 1231 Trailer1TPMTireInfo_RefPres_ISig 255;
BA_ "NeedsUpdateBit" SG_ 1231 Trailer1TPMTireInfo_RefPres_ISig 1;
BA_ "Platform_VMCU1_Sig" SG_ 1231 Trailer1TPMTireInfo_RefPres_ISig 1;
BA_ "SystemSignalLongSymbol" SG_ 1231 Trailer1TPMTireInfo_RefPres_ISig "Trailer1TPMTireInfo_RefPres_ISig_4";
BA_ "GenSigCycleTime" SG_ 1231 Trailer1TPMTireInfo_Temperature_ 100;
BA_ "GenSigCycleTimeActive" SG_ 1231 Trailer1TPMTireInfo_Temperature_ 100;
BA_ "GenSigStartValue" SG_ 1231 Trailer1TPMTireInfo_Temperature_ 255;
BA_ "NeedsUpdateBit" SG_ 1231 Trailer1TPMTireInfo_Temperature_ 1;
BA_ "Platform_VMCU1_Sig" SG_ 1231 Trailer1TPMTireInfo_Temperature_ 1;
BA_ "SystemSignalLongSymbol" SG_ 1231 Trailer1TPMTireInfo_Temperature_ "Trailer1TPMTireInfo_Temperature_ISig_4";
BA_ "GenSigCycleTime" SG_ 1231 Trailer1TPMTireInfo_Active_ISig_ 100;
BA_ "GenSigCycleTimeActive" SG_ 1231 Trailer1TPMTireInfo_Active_ISig_ 100;
BA_ "GenSigStartValue" SG_ 1231 Trailer1TPMTireInfo_Active_ISig_ 3;
BA_ "NeedsUpdateBit" SG_ 1231 Trailer1TPMTireInfo_Active_ISig_ 1;
BA_ "Platform_VMCU1_Sig" SG_ 1231 Trailer1TPMTireInfo_Active_ISig_ 1;
BA_ "SystemSignalLongSymbol" SG_ 1231 Trailer1TPMTireInfo_Active_ISig_ "Trailer1TPMTireInfo_Active_ISig_4";
BA_ "GenSigCycleTime" SG_ 1231 TPMPosOfWMResp_Status_ISig_4 100;
BA_ "GenSigCycleTimeActive" SG_ 1231 TPMPosOfWMResp_Status_ISig_4 100;
BA_ "GenSigStartValue" SG_ 1231 TPMPosOfWMResp_Status_ISig_4 7;
BA_ "NeedsUpdateBit" SG_ 1231 TPMPosOfWMResp_Status_ISig_4 1;
BA_ "Platform_VMCU1_Sig" SG_ 1231 TPMPosOfWMResp_Status_ISig_4 1;
BA_ "GenSigCycleTime" SG_ 1231 TPMPosOfWMResp_TireId_ISig_4 100;
BA_ "GenSigCycleTimeActive" SG_ 1231 TPMPosOfWMResp_TireId_ISig_4 100;
BA_ "NeedsUpdateBit" SG_ 1231 TPMPosOfWMResp_TireId_ISig_4 1;
BA_ "Platform_VMCU1_Sig" SG_ 1231 TPMPosOfWMResp_TireId_ISig_4 1;
BA_ "GenSigCycleTime" SG_ 1403 TruckTPMThresCfg_OverPres_ISig_4 100;
BA_ "GenSigCycleTimeActive" SG_ 1403 TruckTPMThresCfg_OverPres_ISig_4 100;
BA_ "GenSigStartValue" SG_ 1403 TruckTPMThresCfg_OverPres_ISig_4 255;
BA_ "NeedsUpdateBit" SG_ 1403 TruckTPMThresCfg_OverPres_ISig_4 1;
BA_ "Platform_VMCU1_Sig" SG_ 1403 TruckTPMThresCfg_OverPres_ISig_4 1;
BA_ "GenSigCycleTime" SG_ 1403 TruckTPMAxlTireCfg_Axle2_ISig_4 100;
BA_ "GenSigCycleTimeActive" SG_ 1403 TruckTPMAxlTireCfg_Axle2_ISig_4 100;
BA_ "GenSigStartValue" SG_ 1403 TruckTPMAxlTireCfg_Axle2_ISig_4 7;
BA_ "Platform_VMCU1_Sig" SG_ 1403 TruckTPMAxlTireCfg_Axle2_ISig_4 1;
BA_ "GenSigCycleTime" SG_ 1403 TruckTPMAxlTireCfg_Axle1_ISig_4 100;
BA_ "GenSigCycleTimeActive" SG_ 1403 TruckTPMAxlTireCfg_Axle1_ISig_4 100;
BA_ "GenSigStartValue" SG_ 1403 TruckTPMAxlTireCfg_Axle1_ISig_4 7;
BA_ "Platform_VMCU1_Sig" SG_ 1403 TruckTPMAxlTireCfg_Axle1_ISig_4 1;
BA_ "GenSigCycleTime" SG_ 1403 TruckTPMAxlTireCfg_Axle5_ISig_4 100;
BA_ "GenSigCycleTimeActive" SG_ 1403 TruckTPMAxlTireCfg_Axle5_ISig_4 100;
BA_ "GenSigStartValue" SG_ 1403 TruckTPMAxlTireCfg_Axle5_ISig_4 7;
BA_ "Platform_VMCU1_Sig" SG_ 1403 TruckTPMAxlTireCfg_Axle5_ISig_4 1;
BA_ "GenSigSendType" SG_ 1403 TruckTPMThresCfg_sg_UB_ISig_4 7;
BA_ "GenSigCycleTime" SG_ 1403 TruckTPMThresCfg_sg_UB_ISig_4 100;
BA_ "GenSigCycleTimeActive" SG_ 1403 TruckTPMThresCfg_sg_UB_ISig_4 100;
BA_ "Platform_VMCU1_Sig" SG_ 1403 TruckTPMThresCfg_sg_UB_ISig_4 1;
BA_ "GenSigCycleTime" SG_ 1403 TruckTPMAxlTireCfg_Axle4_ISig_4 100;
BA_ "GenSigCycleTimeActive" SG_ 1403 TruckTPMAxlTireCfg_Axle4_ISig_4 100;
BA_ "GenSigStartValue" SG_ 1403 TruckTPMAxlTireCfg_Axle4_ISig_4 7;
BA_ "Platform_VMCU1_Sig" SG_ 1403 TruckTPMAxlTireCfg_Axle4_ISig_4 1;
BA_ "GenSigCycleTime" SG_ 1403 TruckTPMThresCfg_ExtUnderPres_IS 100;
BA_ "GenSigCycleTimeActive" SG_ 1403 TruckTPMThresCfg_ExtUnderPres_IS 100;
BA_ "GenSigStartValue" SG_ 1403 TruckTPMThresCfg_ExtUnderPres_IS 255;
BA_ "NeedsUpdateBit" SG_ 1403 TruckTPMThresCfg_ExtUnderPres_IS 1;
BA_ "Platform_VMCU1_Sig" SG_ 1403 TruckTPMThresCfg_ExtUnderPres_IS 1;
BA_ "SystemSignalLongSymbol" SG_ 1403 TruckTPMThresCfg_ExtUnderPres_IS "TruckTPMThresCfg_ExtUnderPres_ISig_4";
BA_ "GenSigCycleTime" SG_ 1403 TruckTPMThresCfg_AxleNr_ISig_4 100;
BA_ "GenSigCycleTimeActive" SG_ 1403 TruckTPMThresCfg_AxleNr_ISig_4 100;
BA_ "GenSigStartValue" SG_ 1403 TruckTPMThresCfg_AxleNr_ISig_4 7;
BA_ "NeedsUpdateBit" SG_ 1403 TruckTPMThresCfg_AxleNr_ISig_4 1;
BA_ "Platform_VMCU1_Sig" SG_ 1403 TruckTPMThresCfg_AxleNr_ISig_4 1;
BA_ "GenSigCycleTime" SG_ 1403 TruckTPMThresCfg_UnderPres_ISig_ 100;
BA_ "GenSigCycleTimeActive" SG_ 1403 TruckTPMThresCfg_UnderPres_ISig_ 100;
BA_ "GenSigStartValue" SG_ 1403 TruckTPMThresCfg_UnderPres_ISig_ 255;
BA_ "NeedsUpdateBit" SG_ 1403 TruckTPMThresCfg_UnderPres_ISig_ 1;
BA_ "Platform_VMCU1_Sig" SG_ 1403 TruckTPMThresCfg_UnderPres_ISig_ 1;
BA_ "SystemSignalLongSymbol" SG_ 1403 TruckTPMThresCfg_UnderPres_ISig_ "TruckTPMThresCfg_UnderPres_ISig_4";
BA_ "GenSigCycleTime" SG_ 1403 TruckTPMThresCfg_ExtOverPres_ISi 100;
BA_ "GenSigCycleTimeActive" SG_ 1403 TruckTPMThresCfg_ExtOverPres_ISi 100;
BA_ "GenSigStartValue" SG_ 1403 TruckTPMThresCfg_ExtOverPres_ISi 255;
BA_ "NeedsUpdateBit" SG_ 1403 TruckTPMThresCfg_ExtOverPres_ISi 1;
BA_ "Platform_VMCU1_Sig" SG_ 1403 TruckTPMThresCfg_ExtOverPres_ISi 1;
BA_ "SystemSignalLongSymbol" SG_ 1403 TruckTPMThresCfg_ExtOverPres_ISi "TruckTPMThresCfg_ExtOverPres_ISig_4";
BA_ "GenSigCycleTime" SG_ 1403 TruckTPMAxlTireCfg_Axle3_ISig_4 100;
BA_ "GenSigCycleTimeActive" SG_ 1403 TruckTPMAxlTireCfg_Axle3_ISig_4 100;
BA_ "GenSigStartValue" SG_ 1403 TruckTPMAxlTireCfg_Axle3_ISig_4 7;
BA_ "Platform_VMCU1_Sig" SG_ 1403 TruckTPMAxlTireCfg_Axle3_ISig_4 1;
BA_ "GenSigCycleTime" SG_ 1402 Trailer2TPMType_ISig_4 100;
BA_ "GenSigCycleTimeActive" SG_ 1402 Trailer2TPMType_ISig_4 100;
BA_ "GenSigStartValue" SG_ 1402 Trailer2TPMType_ISig_4 3;
BA_ "NeedsUpdateBit" SG_ 1402 Trailer2TPMType_ISig_4 1;
BA_ "Platform_VMCU1_Sig" SG_ 1402 Trailer2TPMType_ISig_4 1;
BA_ "GenSigCycleTime" SG_ 1402 Trailer2TPMAxlTireCfg_Axle1_ISig 100;
BA_ "GenSigCycleTimeActive" SG_ 1402 Trailer2TPMAxlTireCfg_Axle1_ISig 100;
BA_ "GenSigStartValue" SG_ 1402 Trailer2TPMAxlTireCfg_Axle1_ISig 7;
BA_ "Platform_VMCU1_Sig" SG_ 1402 Trailer2TPMAxlTireCfg_Axle1_ISig 1;
BA_ "SystemSignalLongSymbol" SG_ 1402 Trailer2TPMAxlTireCfg_Axle1_ISig "Trailer2TPMAxlTireCfg_Axle1_ISig_4";
BA_ "GenSigCycleTime" SG_ 1402 Trailer2TPMThresCfg_OverPres_ISi 100;
BA_ "GenSigCycleTimeActive" SG_ 1402 Trailer2TPMThresCfg_OverPres_ISi 100;
BA_ "GenSigStartValue" SG_ 1402 Trailer2TPMThresCfg_OverPres_ISi 255;
BA_ "NeedsUpdateBit" SG_ 1402 Trailer2TPMThresCfg_OverPres_ISi 1;
BA_ "Platform_VMCU1_Sig" SG_ 1402 Trailer2TPMThresCfg_OverPres_ISi 1;
BA_ "SystemSignalLongSymbol" SG_ 1402 Trailer2TPMThresCfg_OverPres_ISi "Trailer2TPMThresCfg_OverPres_ISig_4";
BA_ "GenSigCycleTime" SG_ 1402 Trailer2TPMAxlTireCfg_Axle3_ISig 100;
BA_ "GenSigCycleTimeActive" SG_ 1402 Trailer2TPMAxlTireCfg_Axle3_ISig 100;
BA_ "GenSigStartValue" SG_ 1402 Trailer2TPMAxlTireCfg_Axle3_ISig 7;
BA_ "Platform_VMCU1_Sig" SG_ 1402 Trailer2TPMAxlTireCfg_Axle3_ISig 1;
BA_ "SystemSignalLongSymbol" SG_ 1402 Trailer2TPMAxlTireCfg_Axle3_ISig "Trailer2TPMAxlTireCfg_Axle3_ISig_4";
BA_ "GenSigCycleTime" SG_ 1402 Trailer2TPMAxlTireCfg_Axle2_ISig 100;
BA_ "GenSigCycleTimeActive" SG_ 1402 Trailer2TPMAxlTireCfg_Axle2_ISig 100;
BA_ "GenSigStartValue" SG_ 1402 Trailer2TPMAxlTireCfg_Axle2_ISig 7;
BA_ "Platform_VMCU1_Sig" SG_ 1402 Trailer2TPMAxlTireCfg_Axle2_ISig 1;
BA_ "SystemSignalLongSymbol" SG_ 1402 Trailer2TPMAxlTireCfg_Axle2_ISig "Trailer2TPMAxlTireCfg_Axle2_ISig_4";
BA_ "GenSigCycleTime" SG_ 1402 Trailer2TPMAxlTireCfg_Axle5_ISig 100;
BA_ "GenSigCycleTimeActive" SG_ 1402 Trailer2TPMAxlTireCfg_Axle5_ISig 100;
BA_ "GenSigStartValue" SG_ 1402 Trailer2TPMAxlTireCfg_Axle5_ISig 7;
BA_ "Platform_VMCU1_Sig" SG_ 1402 Trailer2TPMAxlTireCfg_Axle5_ISig 1;
BA_ "SystemSignalLongSymbol" SG_ 1402 Trailer2TPMAxlTireCfg_Axle5_ISig "Trailer2TPMAxlTireCfg_Axle5_ISig_4";
BA_ "GenSigCycleTime" SG_ 1402 Trailer2TPMAxlTireCfg_Axle4_ISig 100;
BA_ "GenSigCycleTimeActive" SG_ 1402 Trailer2TPMAxlTireCfg_Axle4_ISig 100;
BA_ "GenSigStartValue" SG_ 1402 Trailer2TPMAxlTireCfg_Axle4_ISig 7;
BA_ "Platform_VMCU1_Sig" SG_ 1402 Trailer2TPMAxlTireCfg_Axle4_ISig 1;
BA_ "SystemSignalLongSymbol" SG_ 1402 Trailer2TPMAxlTireCfg_Axle4_ISig "Trailer2TPMAxlTireCfg_Axle4_ISig_4";
BA_ "GenSigSendType" SG_ 1402 Trailer2TPMThresCfg_sg_UB_ISig_4 7;
BA_ "GenSigCycleTime" SG_ 1402 Trailer2TPMThresCfg_sg_UB_ISig_4 100;
BA_ "GenSigCycleTimeActive" SG_ 1402 Trailer2TPMThresCfg_sg_UB_ISig_4 100;
BA_ "Platform_VMCU1_Sig" SG_ 1402 Trailer2TPMThresCfg_sg_UB_ISig_4 1;
BA_ "GenSigCycleTime" SG_ 1402 Trailer2TPMThresCfg_AxleNr_ISig_ 100;
BA_ "GenSigCycleTimeActive" SG_ 1402 Trailer2TPMThresCfg_AxleNr_ISig_ 100;
BA_ "GenSigStartValue" SG_ 1402 Trailer2TPMThresCfg_AxleNr_ISig_ 7;
BA_ "NeedsUpdateBit" SG_ 1402 Trailer2TPMThresCfg_AxleNr_ISig_ 1;
BA_ "Platform_VMCU1_Sig" SG_ 1402 Trailer2TPMThresCfg_AxleNr_ISig_ 1;
BA_ "SystemSignalLongSymbol" SG_ 1402 Trailer2TPMThresCfg_AxleNr_ISig_ "Trailer2TPMThresCfg_AxleNr_ISig_4";
BA_ "GenSigCycleTime" SG_ 1402 Trailer2TPMThresCfg_ExtOverPres_ 100;
BA_ "GenSigCycleTimeActive" SG_ 1402 Trailer2TPMThresCfg_ExtOverPres_ 100;
BA_ "GenSigStartValue" SG_ 1402 Trailer2TPMThresCfg_ExtOverPres_ 255;
BA_ "NeedsUpdateBit" SG_ 1402 Trailer2TPMThresCfg_ExtOverPres_ 1;
BA_ "Platform_VMCU1_Sig" SG_ 1402 Trailer2TPMThresCfg_ExtOverPres_ 1;
BA_ "SystemSignalLongSymbol" SG_ 1402 Trailer2TPMThresCfg_ExtOverPres_ "Trailer2TPMThresCfg_ExtOverPres_ISig_4";
BA_ "GenSigCycleTime" SG_ 1402 Trailer2TPMThresCfg_UnderPres_IS 100;
BA_ "GenSigCycleTimeActive" SG_ 1402 Trailer2TPMThresCfg_UnderPres_IS 100;
BA_ "GenSigStartValue" SG_ 1402 Trailer2TPMThresCfg_UnderPres_IS 255;
BA_ "NeedsUpdateBit" SG_ 1402 Trailer2TPMThresCfg_UnderPres_IS 1;
BA_ "Platform_VMCU1_Sig" SG_ 1402 Trailer2TPMThresCfg_UnderPres_IS 1;
BA_ "SystemSignalLongSymbol" SG_ 1402 Trailer2TPMThresCfg_UnderPres_IS "Trailer2TPMThresCfg_UnderPres_ISig_4";
BA_ "GenSigCycleTime" SG_ 1402 Trailer2TPMThresCfg_ExtUnderPres 100;
BA_ "GenSigCycleTimeActive" SG_ 1402 Trailer2TPMThresCfg_ExtUnderPres 100;
BA_ "GenSigStartValue" SG_ 1402 Trailer2TPMThresCfg_ExtUnderPres 255;
BA_ "NeedsUpdateBit" SG_ 1402 Trailer2TPMThresCfg_ExtUnderPres 1;
BA_ "Platform_VMCU1_Sig" SG_ 1402 Trailer2TPMThresCfg_ExtUnderPres 1;
BA_ "SystemSignalLongSymbol" SG_ 1402 Trailer2TPMThresCfg_ExtUnderPres "Trailer2TPMThresCfg_ExtUnderPres_ISig_4";
BA_ "GenSigSendType" SG_ 1402 Trailer2TPMType_UB_ISig_4 7;
BA_ "Platform_VMCU1_Sig" SG_ 1402 Trailer2TPMType_UB_ISig_4 1;
BA_ "GenSigCycleTime" SG_ 1401 Trailer1TPMAxlTireCfg_Axle1_ISig 100;
BA_ "GenSigCycleTimeActive" SG_ 1401 Trailer1TPMAxlTireCfg_Axle1_ISig 100;
BA_ "GenSigStartValue" SG_ 1401 Trailer1TPMAxlTireCfg_Axle1_ISig 7;
BA_ "Platform_VMCU1_Sig" SG_ 1401 Trailer1TPMAxlTireCfg_Axle1_ISig 1;
BA_ "SystemSignalLongSymbol" SG_ 1401 Trailer1TPMAxlTireCfg_Axle1_ISig "Trailer1TPMAxlTireCfg_Axle1_ISig_4";
BA_ "GenSigCycleTime" SG_ 1401 Trailer1TPMThresCfg_ExtOverPres_ 100;
BA_ "GenSigCycleTimeActive" SG_ 1401 Trailer1TPMThresCfg_ExtOverPres_ 100;
BA_ "GenSigStartValue" SG_ 1401 Trailer1TPMThresCfg_ExtOverPres_ 255;
BA_ "NeedsUpdateBit" SG_ 1401 Trailer1TPMThresCfg_ExtOverPres_ 1;
BA_ "Platform_VMCU1_Sig" SG_ 1401 Trailer1TPMThresCfg_ExtOverPres_ 1;
BA_ "SystemSignalLongSymbol" SG_ 1401 Trailer1TPMThresCfg_ExtOverPres_ "Trailer1TPMThresCfg_ExtOverPres_ISig_4";
BA_ "GenSigCycleTime" SG_ 1401 Trailer1TPMAxlTireCfg_Axle2_ISig 100;
BA_ "GenSigCycleTimeActive" SG_ 1401 Trailer1TPMAxlTireCfg_Axle2_ISig 100;
BA_ "GenSigStartValue" SG_ 1401 Trailer1TPMAxlTireCfg_Axle2_ISig 7;
BA_ "Platform_VMCU1_Sig" SG_ 1401 Trailer1TPMAxlTireCfg_Axle2_ISig 1;
BA_ "SystemSignalLongSymbol" SG_ 1401 Trailer1TPMAxlTireCfg_Axle2_ISig "Trailer1TPMAxlTireCfg_Axle2_ISig_4";
BA_ "GenSigCycleTime" SG_ 1401 Trailer1TPMThresCfg_OverPres_ISi 100;
BA_ "GenSigCycleTimeActive" SG_ 1401 Trailer1TPMThresCfg_OverPres_ISi 100;
BA_ "GenSigStartValue" SG_ 1401 Trailer1TPMThresCfg_OverPres_ISi 255;
BA_ "NeedsUpdateBit" SG_ 1401 Trailer1TPMThresCfg_OverPres_ISi 1;
BA_ "Platform_VMCU1_Sig" SG_ 1401 Trailer1TPMThresCfg_OverPres_ISi 1;
BA_ "SystemSignalLongSymbol" SG_ 1401 Trailer1TPMThresCfg_OverPres_ISi "Trailer1TPMThresCfg_OverPres_ISig_4";
BA_ "GenSigCycleTime" SG_ 1401 Trailer1TPMAxlTireCfg_Axle5_ISig 100;
BA_ "GenSigCycleTimeActive" SG_ 1401 Trailer1TPMAxlTireCfg_Axle5_ISig 100;
BA_ "GenSigStartValue" SG_ 1401 Trailer1TPMAxlTireCfg_Axle5_ISig 7;
BA_ "Platform_VMCU1_Sig" SG_ 1401 Trailer1TPMAxlTireCfg_Axle5_ISig 1;
BA_ "SystemSignalLongSymbol" SG_ 1401 Trailer1TPMAxlTireCfg_Axle5_ISig "Trailer1TPMAxlTireCfg_Axle5_ISig_4";
BA_ "GenSigCycleTime" SG_ 1401 Trailer1TPMType_ISig_4 100;
BA_ "GenSigCycleTimeActive" SG_ 1401 Trailer1TPMType_ISig_4 100;
BA_ "GenSigStartValue" SG_ 1401 Trailer1TPMType_ISig_4 3;
BA_ "NeedsUpdateBit" SG_ 1401 Trailer1TPMType_ISig_4 1;
BA_ "Platform_VMCU1_Sig" SG_ 1401 Trailer1TPMType_ISig_4 1;
BA_ "GenSigCycleTime" SG_ 1401 Trailer1TPMThresCfg_UnderPres_IS 100;
BA_ "GenSigCycleTimeActive" SG_ 1401 Trailer1TPMThresCfg_UnderPres_IS 100;
BA_ "GenSigStartValue" SG_ 1401 Trailer1TPMThresCfg_UnderPres_IS 255;
BA_ "NeedsUpdateBit" SG_ 1401 Trailer1TPMThresCfg_UnderPres_IS 1;
BA_ "Platform_VMCU1_Sig" SG_ 1401 Trailer1TPMThresCfg_UnderPres_IS 1;
BA_ "SystemSignalLongSymbol" SG_ 1401 Trailer1TPMThresCfg_UnderPres_IS "Trailer1TPMThresCfg_UnderPres_ISig_4";
BA_ "GenSigSendType" SG_ 1401 Trailer1TPMThresCfg_sg_UB_ISig_4 7;
BA_ "GenSigCycleTime" SG_ 1401 Trailer1TPMThresCfg_sg_UB_ISig_4 100;
BA_ "GenSigCycleTimeActive" SG_ 1401 Trailer1TPMThresCfg_sg_UB_ISig_4 100;
BA_ "Platform_VMCU1_Sig" SG_ 1401 Trailer1TPMThresCfg_sg_UB_ISig_4 1;
BA_ "GenSigCycleTime" SG_ 1401 Trailer1TPMThresCfg_ExtUnderPres 100;
BA_ "GenSigCycleTimeActive" SG_ 1401 Trailer1TPMThresCfg_ExtUnderPres 100;
BA_ "GenSigStartValue" SG_ 1401 Trailer1TPMThresCfg_ExtUnderPres 255;
BA_ "NeedsUpdateBit" SG_ 1401 Trailer1TPMThresCfg_ExtUnderPres 1;
BA_ "Platform_VMCU1_Sig" SG_ 1401 Trailer1TPMThresCfg_ExtUnderPres 1;
BA_ "SystemSignalLongSymbol" SG_ 1401 Trailer1TPMThresCfg_ExtUnderPres "Trailer1TPMThresCfg_ExtUnderPres_ISig_4";
BA_ "GenSigCycleTime" SG_ 1401 Trailer1TPMThresCfg_AxleNr_ISig_ 100;
BA_ "GenSigCycleTimeActive" SG_ 1401 Trailer1TPMThresCfg_AxleNr_ISig_ 100;
BA_ "GenSigStartValue" SG_ 1401 Trailer1TPMThresCfg_AxleNr_ISig_ 7;
BA_ "NeedsUpdateBit" SG_ 1401 Trailer1TPMThresCfg_AxleNr_ISig_ 1;
BA_ "Platform_VMCU1_Sig" SG_ 1401 Trailer1TPMThresCfg_AxleNr_ISig_ 1;
BA_ "SystemSignalLongSymbol" SG_ 1401 Trailer1TPMThresCfg_AxleNr_ISig_ "Trailer1TPMThresCfg_AxleNr_ISig_4";
BA_ "GenSigSendType" SG_ 1401 Trailer1TPMType_UB_ISig_4 7;
BA_ "Platform_VMCU1_Sig" SG_ 1401 Trailer1TPMType_UB_ISig_4 1;
BA_ "GenSigCycleTime" SG_ 1401 Trailer1TPMAxlTireCfg_Axle4_ISig 100;
BA_ "GenSigCycleTimeActive" SG_ 1401 Trailer1TPMAxlTireCfg_Axle4_ISig 100;
BA_ "GenSigStartValue" SG_ 1401 Trailer1TPMAxlTireCfg_Axle4_ISig 7;
BA_ "Platform_VMCU1_Sig" SG_ 1401 Trailer1TPMAxlTireCfg_Axle4_ISig 1;
BA_ "SystemSignalLongSymbol" SG_ 1401 Trailer1TPMAxlTireCfg_Axle4_ISig "Trailer1TPMAxlTireCfg_Axle4_ISig_4";
BA_ "GenSigCycleTime" SG_ 1401 Trailer1TPMAxlTireCfg_Axle3_ISig 100;
BA_ "GenSigCycleTimeActive" SG_ 1401 Trailer1TPMAxlTireCfg_Axle3_ISig 100;
BA_ "GenSigStartValue" SG_ 1401 Trailer1TPMAxlTireCfg_Axle3_ISig 7;
BA_ "Platform_VMCU1_Sig" SG_ 1401 Trailer1TPMAxlTireCfg_Axle3_ISig 1;
BA_ "SystemSignalLongSymbol" SG_ 1401 Trailer1TPMAxlTireCfg_Axle3_ISig "Trailer1TPMAxlTireCfg_Axle3_ISig_4";
BA_ "GenSigCycleTime" SG_ 1436 DistToEmptyLNG 100;
BA_ "GenSigCycleTimeActive" SG_ 1436 DistToEmptyLNG 100;
BA_ "GenSigStartValue" SG_ 1436 DistToEmptyLNG 65535;
BA_ "Platform_VMCU1_Sig" SG_ 1436 DistToEmptyLNG 1;
BA_ "GenSigCycleTime" SG_ 1436 DistToEmptyDiesel 100;
BA_ "GenSigCycleTimeActive" SG_ 1436 DistToEmptyDiesel 100;
BA_ "GenSigStartValue" SG_ 1436 DistToEmptyDiesel 65535;
BA_ "Platform_VMCU1_Sig" SG_ 1436 DistToEmptyDiesel 1;
BA_ "GenSigCycleTime" SG_ 1436 CoastingUseDistance_ISig_4 100;
BA_ "GenSigCycleTimeActive" SG_ 1436 CoastingUseDistance_ISig_4 100;
BA_ "GenSigStartValue" SG_ 1436 CoastingUseDistance_ISig_4 4294967295;
BA_ "Platform_VMCU1_Sig" SG_ 1436 CoastingUseDistance_ISig_4 1;
BA_REL_ "GenSigFirstTimeoutTime" BU_SG_REL_ IC3 SG_ 1300 CalLoadTruckFrontAxle2_ISig_4 24000;
BA_REL_ "GenSigTimeoutTime" BU_SG_REL_ IC3 SG_ 1300 CalLoadTruckFrontAxle2_ISig_4 6000;
BA_REL_ "GenSigFirstTimeoutTime" BU_SG_REL_ CIOM SG_ 1300 CalLoadTruckFrontAxle2_ISig_4 24000;
BA_REL_ "GenSigTimeoutTime" BU_SG_REL_ CIOM SG_ 1300 CalLoadTruckFrontAxle2_ISig_4 6000;
BA_REL_ "GenSigFirstTimeoutTime" BU_SG_REL_ BBM SG_ 1300 CalLoadTruckFrontAxle2_ISig_4 24000;
BA_REL_ "GenSigTimeoutTime" BU_SG_REL_ BBM SG_ 1300 CalLoadTruckFrontAxle2_ISig_4 6000;
BA_REL_ "GenSigFirstTimeoutTime" BU_SG_REL_ CIOM SG_ 1300 CalLoadTrailer1Axle1_ISig_4 24000;
BA_REL_ "GenSigTimeoutTime" BU_SG_REL_ CIOM SG_ 1300 CalLoadTrailer1Axle1_ISig_4 6000;
BA_REL_ "GenSigFirstTimeoutTime" BU_SG_REL_ BBM SG_ 1300 CalLoadTrailer1Axle1_ISig_4 24000;
BA_REL_ "GenSigTimeoutTime" BU_SG_REL_ BBM SG_ 1300 CalLoadTrailer1Axle1_ISig_4 6000;
BA_REL_ "GenSigFirstTimeoutTime" BU_SG_REL_ IC3 SG_ 1300 CalLoadTrailer1Axle1_ISig_4 24000;
BA_REL_ "GenSigTimeoutTime" BU_SG_REL_ IC3 SG_ 1300 CalLoadTrailer1Axle1_ISig_4 6000;
BA_REL_ "GenSigFirstTimeoutTime" BU_SG_REL_ IC3 SG_ 1300 CalLoadTrailer2Axle6_ISig_4 24000;
BA_REL_ "GenSigTimeoutTime" BU_SG_REL_ IC3 SG_ 1300 CalLoadTrailer2Axle6_ISig_4 6000;
BA_REL_ "GenSigFirstTimeoutTime" BU_SG_REL_ CIOM SG_ 1300 CalLoadTrailer2Axle6_ISig_4 24000;
BA_REL_ "GenSigTimeoutTime" BU_SG_REL_ CIOM SG_ 1300 CalLoadTrailer2Axle6_ISig_4 6000;
BA_REL_ "GenSigFirstTimeoutTime" BU_SG_REL_ CIOM SG_ 1300 CalLoadTrailer4Axle4_ISig_4 24000;
BA_REL_ "GenSigTimeoutTime" BU_SG_REL_ CIOM SG_ 1300 CalLoadTrailer4Axle4_ISig_4 6000;
BA_REL_ "GenSigFirstTimeoutTime" BU_SG_REL_ IC3 SG_ 1300 CalLoadTrailer4Axle4_ISig_4 24000;
BA_REL_ "GenSigTimeoutTime" BU_SG_REL_ IC3 SG_ 1300 CalLoadTrailer4Axle4_ISig_4 6000;
BA_REL_ "GenSigFirstTimeoutTime" BU_SG_REL_ IC3 SG_ 1299 CalLoadTrailer5Axle1_ISig_4 24000;
BA_REL_ "GenSigTimeoutTime" BU_SG_REL_ IC3 SG_ 1299 CalLoadTrailer5Axle1_ISig_4 6000;
BA_REL_ "GenSigFirstTimeoutTime" BU_SG_REL_ CIOM SG_ 1299 CalLoadTrailer5Axle1_ISig_4 24000;
BA_REL_ "GenSigTimeoutTime" BU_SG_REL_ CIOM SG_ 1299 CalLoadTrailer5Axle1_ISig_4 6000;
BA_REL_ "GenSigFirstTimeoutTime" BU_SG_REL_ CIOM SG_ 1299 CalLoadTrailer3Axle1_ISig_4 24000;
BA_REL_ "GenSigTimeoutTime" BU_SG_REL_ CIOM SG_ 1299 CalLoadTrailer3Axle1_ISig_4 6000;
BA_REL_ "GenSigFirstTimeoutTime" BU_SG_REL_ IC3 SG_ 1299 CalLoadTrailer3Axle1_ISig_4 24000;
BA_REL_ "GenSigTimeoutTime" BU_SG_REL_ IC3 SG_ 1299 CalLoadTrailer3Axle1_ISig_4 6000;
BA_REL_ "GenSigFirstTimeoutTime" BU_SG_REL_ CIOM SG_ 1299 CalLoadTrailer5Axle5_ISig_4 24000;
BA_REL_ "GenSigTimeoutTime" BU_SG_REL_ CIOM SG_ 1299 CalLoadTrailer5Axle5_ISig_4 6000;
BA_REL_ "GenSigFirstTimeoutTime" BU_SG_REL_ IC3 SG_ 1299 CalLoadTrailer5Axle5_ISig_4 24000;
BA_REL_ "GenSigTimeoutTime" BU_SG_REL_ IC3 SG_ 1299 CalLoadTrailer5Axle5_ISig_4 6000;
BA_REL_ "GenSigFirstTimeoutTime" BU_SG_REL_ IC3 SG_ 1299 CalLoadTrailer5Axle4_ISig_4 24000;
BA_REL_ "GenSigTimeoutTime" BU_SG_REL_ IC3 SG_ 1299 CalLoadTrailer5Axle4_ISig_4 6000;
BA_REL_ "GenSigFirstTimeoutTime" BU_SG_REL_ CIOM SG_ 1299 CalLoadTrailer5Axle4_ISig_4 24000;
BA_REL_ "GenSigTimeoutTime" BU_SG_REL_ CIOM SG_ 1299 CalLoadTrailer5Axle4_ISig_4 6000;
BA_REL_ "GenSigFirstTimeoutTime" BU_SG_REL_ CIOM SG_ 1297 CalLoadTrailer5Axle3_ISig_4 24000;
BA_REL_ "GenSigTimeoutTime" BU_SG_REL_ CIOM SG_ 1297 CalLoadTrailer5Axle3_ISig_4 6000;
BA_REL_ "GenSigFirstTimeoutTime" BU_SG_REL_ IC3 SG_ 1297 CalLoadTrailer5Axle3_ISig_4 24000;
BA_REL_ "GenSigTimeoutTime" BU_SG_REL_ IC3 SG_ 1297 CalLoadTrailer5Axle3_ISig_4 6000;
BA_REL_ "GenSigFirstTimeoutTime" BU_SG_REL_ CIOM SG_ 1297 CalLoadTrailer4Axle1_ISig_4 24000;
BA_REL_ "GenSigTimeoutTime" BU_SG_REL_ CIOM SG_ 1297 CalLoadTrailer4Axle1_ISig_4 6000;
BA_REL_ "GenSigFirstTimeoutTime" BU_SG_REL_ IC3 SG_ 1297 CalLoadTrailer4Axle1_ISig_4 24000;
BA_REL_ "GenSigTimeoutTime" BU_SG_REL_ IC3 SG_ 1297 CalLoadTrailer4Axle1_ISig_4 6000;
BA_REL_ "GenSigFirstTimeoutTime" BU_SG_REL_ CIOM SG_ 1297 CalLoadTrailer2Axle5_ISig_4 24000;
BA_REL_ "GenSigTimeoutTime" BU_SG_REL_ CIOM SG_ 1297 CalLoadTrailer2Axle5_ISig_4 6000;
BA_REL_ "GenSigFirstTimeoutTime" BU_SG_REL_ IC3 SG_ 1297 CalLoadTrailer2Axle5_ISig_4 24000;
BA_REL_ "GenSigTimeoutTime" BU_SG_REL_ IC3 SG_ 1297 CalLoadTrailer2Axle5_ISig_4 6000;
BA_REL_ "GenSigFirstTimeoutTime" BU_SG_REL_ CIOM SG_ 1297 CalLoadTrailer3Axle3_ISig_4 24000;
BA_REL_ "GenSigTimeoutTime" BU_SG_REL_ CIOM SG_ 1297 CalLoadTrailer3Axle3_ISig_4 6000;
BA_REL_ "GenSigFirstTimeoutTime" BU_SG_REL_ IC3 SG_ 1297 CalLoadTrailer3Axle3_ISig_4 24000;
BA_REL_ "GenSigTimeoutTime" BU_SG_REL_ IC3 SG_ 1297 CalLoadTrailer3Axle3_ISig_4 6000;
BA_REL_ "GenSigFirstTimeoutTime" BU_SG_REL_ IC3 SG_ 1296 CalLoadTrailer1Axle3_ISig_4 24000;
BA_REL_ "GenSigTimeoutTime" BU_SG_REL_ IC3 SG_ 1296 CalLoadTrailer1Axle3_ISig_4 6000;
BA_REL_ "GenSigFirstTimeoutTime" BU_SG_REL_ BBM SG_ 1296 CalLoadTrailer1Axle3_ISig_4 24000;
BA_REL_ "GenSigTimeoutTime" BU_SG_REL_ BBM SG_ 1296 CalLoadTrailer1Axle3_ISig_4 6000;
BA_REL_ "GenSigFirstTimeoutTime" BU_SG_REL_ CIOM SG_ 1296 CalLoadTrailer1Axle3_ISig_4 24000;
BA_REL_ "GenSigTimeoutTime" BU_SG_REL_ CIOM SG_ 1296 CalLoadTrailer1Axle3_ISig_4 6000;
BA_REL_ "GenSigFirstTimeoutTime" BU_SG_REL_ IC3 SG_ 1296 CalLoadTrailer4Axle5_ISig_4 24000;
BA_REL_ "GenSigTimeoutTime" BU_SG_REL_ IC3 SG_ 1296 CalLoadTrailer4Axle5_ISig_4 6000;
BA_REL_ "GenSigFirstTimeoutTime" BU_SG_REL_ CIOM SG_ 1296 CalLoadTrailer4Axle5_ISig_4 24000;
BA_REL_ "GenSigTimeoutTime" BU_SG_REL_ CIOM SG_ 1296 CalLoadTrailer4Axle5_ISig_4 6000;
BA_REL_ "GenSigFirstTimeoutTime" BU_SG_REL_ CIOM SG_ 1296 CalLoadTruckRearAxle1_ISig_4 24000;
BA_REL_ "GenSigTimeoutTime" BU_SG_REL_ CIOM SG_ 1296 CalLoadTruckRearAxle1_ISig_4 6000;
BA_REL_ "GenSigFirstTimeoutTime" BU_SG_REL_ BBM SG_ 1296 CalLoadTruckRearAxle1_ISig_4 24000;
BA_REL_ "GenSigTimeoutTime" BU_SG_REL_ BBM SG_ 1296 CalLoadTruckRearAxle1_ISig_4 6000;
BA_REL_ "GenSigFirstTimeoutTime" BU_SG_REL_ IC3 SG_ 1296 CalLoadTruckRearAxle1_ISig_4 24000;
BA_REL_ "GenSigTimeoutTime" BU_SG_REL_ IC3 SG_ 1296 CalLoadTruckRearAxle1_ISig_4 6000;
BA_REL_ "GenSigFirstTimeoutTime" BU_SG_REL_ IC3 SG_ 1296 CalLoadTruckFrontAxle1_ISig_4 24000;
BA_REL_ "GenSigTimeoutTime" BU_SG_REL_ IC3 SG_ 1296 CalLoadTruckFrontAxle1_ISig_4 6000;
BA_REL_ "GenSigFirstTimeoutTime" BU_SG_REL_ BBM SG_ 1296 CalLoadTruckFrontAxle1_ISig_4 24000;
BA_REL_ "GenSigTimeoutTime" BU_SG_REL_ BBM SG_ 1296 CalLoadTruckFrontAxle1_ISig_4 6000;
BA_REL_ "GenSigFirstTimeoutTime" BU_SG_REL_ CIOM SG_ 1296 CalLoadTruckFrontAxle1_ISig_4 24000;
BA_REL_ "GenSigTimeoutTime" BU_SG_REL_ CIOM SG_ 1296 CalLoadTruckFrontAxle1_ISig_4 6000;
BA_REL_ "GenSigFirstTimeoutTime" BU_SG_REL_ CIOM SG_ 1383 Trail2NoOfFrontAxles_ISig_4 24000;
BA_REL_ "GenSigTimeoutTime" BU_SG_REL_ CIOM SG_ 1383 Trail2NoOfFrontAxles_ISig_4 6000;
BA_REL_ "GenSigFirstTimeoutTime" BU_SG_REL_ IC3 SG_ 1383 Trail2NoOfFrontAxles_ISig_4 24000;
BA_REL_ "GenSigTimeoutTime" BU_SG_REL_ IC3 SG_ 1383 Trail2NoOfFrontAxles_ISig_4 6000;
BA_REL_ "GenSigFirstTimeoutTime" BU_SG_REL_ IC3 SG_ 1383 BbOutputFault_Status 24000;
BA_REL_ "GenSigTimeoutTime" BU_SG_REL_ IC3 SG_ 1383 BbOutputFault_Status 6000;
BA_REL_ "GenSigFirstTimeoutTime" BU_SG_REL_ IC3 SG_ 1383 Trail2NoOfAxles_ISig_4 24000;
BA_REL_ "GenSigTimeoutTime" BU_SG_REL_ IC3 SG_ 1383 Trail2NoOfAxles_ISig_4 6000;
BA_REL_ "GenSigFirstTimeoutTime" BU_SG_REL_ CIOM SG_ 1383 Trail2NoOfAxles_ISig_4 24000;
BA_REL_ "GenSigTimeoutTime" BU_SG_REL_ CIOM SG_ 1383 Trail2NoOfAxles_ISig_4 6000;
BA_REL_ "GenSigFirstTimeoutTime" BU_SG_REL_ IC3 SG_ 1383 BunkOutputFault_Status 24000;
BA_REL_ "GenSigTimeoutTime" BU_SG_REL_ IC3 SG_ 1383 BunkOutputFault_Status 6000;
BA_REL_ "GenSigFirstTimeoutTime" BU_SG_REL_ CIOM SG_ 1383 Trail4NoOfFrontAxles_ISig_4 24000;
BA_REL_ "GenSigTimeoutTime" BU_SG_REL_ CIOM SG_ 1383 Trail4NoOfFrontAxles_ISig_4 6000;
BA_REL_ "GenSigFirstTimeoutTime" BU_SG_REL_ IC3 SG_ 1383 Trail4NoOfFrontAxles_ISig_4 24000;
BA_REL_ "GenSigTimeoutTime" BU_SG_REL_ IC3 SG_ 1383 Trail4NoOfFrontAxles_ISig_4 6000;
BA_REL_ "GenSigFirstTimeoutTime" BU_SG_REL_ CIOM SG_ 1383 Trail1NoOfAxles_ISig_4 24000;
BA_REL_ "GenSigTimeoutTime" BU_SG_REL_ CIOM SG_ 1383 Trail1NoOfAxles_ISig_4 6000;
BA_REL_ "GenSigFirstTimeoutTime" BU_SG_REL_ IC3 SG_ 1383 Trail1NoOfAxles_ISig_4 24000;
BA_REL_ "GenSigTimeoutTime" BU_SG_REL_ IC3 SG_ 1383 Trail1NoOfAxles_ISig_4 6000;
BA_REL_ "GenSigFirstTimeoutTime" BU_SG_REL_ IC3 SG_ 1383 Trail3NoOfAxles_ISig_4 24000;
BA_REL_ "GenSigTimeoutTime" BU_SG_REL_ IC3 SG_ 1383 Trail3NoOfAxles_ISig_4 6000;
BA_REL_ "GenSigFirstTimeoutTime" BU_SG_REL_ CIOM SG_ 1383 Trail3NoOfAxles_ISig_4 24000;
BA_REL_ "GenSigTimeoutTime" BU_SG_REL_ CIOM SG_ 1383 Trail3NoOfAxles_ISig_4 6000;
BA_REL_ "GenSigFirstTimeoutTime" BU_SG_REL_ IC3 SG_ 1383 Trail4NoOfAxles_ISig_4 24000;
BA_REL_ "GenSigTimeoutTime" BU_SG_REL_ IC3 SG_ 1383 Trail4NoOfAxles_ISig_4 6000;
BA_REL_ "GenSigFirstTimeoutTime" BU_SG_REL_ CIOM SG_ 1383 Trail4NoOfAxles_ISig_4 24000;
BA_REL_ "GenSigTimeoutTime" BU_SG_REL_ CIOM SG_ 1383 Trail4NoOfAxles_ISig_4 6000;
BA_REL_ "GenSigFirstTimeoutTime" BU_SG_REL_ IC3 SG_ 1383 Trail1NoOfFrontAxles_ISig_4 24000;
BA_REL_ "GenSigTimeoutTime" BU_SG_REL_ IC3 SG_ 1383 Trail1NoOfFrontAxles_ISig_4 6000;
BA_REL_ "GenSigFirstTimeoutTime" BU_SG_REL_ CIOM SG_ 1383 Trail1NoOfFrontAxles_ISig_4 24000;
BA_REL_ "GenSigTimeoutTime" BU_SG_REL_ CIOM SG_ 1383 Trail1NoOfFrontAxles_ISig_4 6000;
BA_REL_ "GenSigFirstTimeoutTime" BU_SG_REL_ CIOM SG_ 1383 Trail5NoOfFrontAxles_ISig_4 24000;
BA_REL_ "GenSigTimeoutTime" BU_SG_REL_ CIOM SG_ 1383 Trail5NoOfFrontAxles_ISig_4 6000;
BA_REL_ "GenSigFirstTimeoutTime" BU_SG_REL_ IC3 SG_ 1383 Trail5NoOfFrontAxles_ISig_4 24000;
BA_REL_ "GenSigTimeoutTime" BU_SG_REL_ IC3 SG_ 1383 Trail5NoOfFrontAxles_ISig_4 6000;
BA_REL_ "GenSigFirstTimeoutTime" BU_SG_REL_ CIOM SG_ 1383 Trail5NoOfAxles_ISig_4 24000;
BA_REL_ "GenSigTimeoutTime" BU_SG_REL_ CIOM SG_ 1383 Trail5NoOfAxles_ISig_4 6000;
BA_REL_ "GenSigFirstTimeoutTime" BU_SG_REL_ IC3 SG_ 1383 Trail5NoOfAxles_ISig_4 24000;
BA_REL_ "GenSigTimeoutTime" BU_SG_REL_ IC3 SG_ 1383 Trail5NoOfAxles_ISig_4 6000;
BA_REL_ "GenSigFirstTimeoutTime" BU_SG_REL_ IC3 SG_ 1383 IpOutputFault_Status 24000;
BA_REL_ "GenSigTimeoutTime" BU_SG_REL_ IC3 SG_ 1383 IpOutputFault_Status 6000;
BA_REL_ "GenSigFirstTimeoutTime" BU_SG_REL_ CIOM SG_ 1383 Trail3NoOfFrontAxles_ISig_4 24000;
BA_REL_ "GenSigTimeoutTime" BU_SG_REL_ CIOM SG_ 1383 Trail3NoOfFrontAxles_ISig_4 6000;
BA_REL_ "GenSigFirstTimeoutTime" BU_SG_REL_ IC3 SG_ 1383 Trail3NoOfFrontAxles_ISig_4 24000;
BA_REL_ "GenSigTimeoutTime" BU_SG_REL_ IC3 SG_ 1383 Trail3NoOfFrontAxles_ISig_4 6000;
BA_REL_ "GenSigFirstTimeoutTime" BU_SG_REL_ CIOM SG_ 1380 Trail3Type_TrailType_ISig_4 24000;
BA_REL_ "GenSigTimeoutTime" BU_SG_REL_ CIOM SG_ 1380 Trail3Type_TrailType_ISig_4 6000;
BA_REL_ "GenSigFirstTimeoutTime" BU_SG_REL_ IC3 SG_ 1380 Trail3Type_TrailType_ISig_4 24000;
BA_REL_ "GenSigTimeoutTime" BU_SG_REL_ IC3 SG_ 1380 Trail3Type_TrailType_ISig_4 6000;
BA_REL_ "GenSigFirstTimeoutTime" BU_SG_REL_ CIOM SG_ 1380 Trail3Type_Towing_ISig_4 24000;
BA_REL_ "GenSigTimeoutTime" BU_SG_REL_ CIOM SG_ 1380 Trail3Type_Towing_ISig_4 6000;
BA_REL_ "GenSigFirstTimeoutTime" BU_SG_REL_ IC3 SG_ 1380 Trail3Type_Towing_ISig_4 24000;
BA_REL_ "GenSigTimeoutTime" BU_SG_REL_ IC3 SG_ 1380 Trail3Type_Towing_ISig_4 6000;
BA_REL_ "GenSigFirstTimeoutTime" BU_SG_REL_ CIOM SG_ 1380 Trail4Type_Towing_ISig_4 24000;
BA_REL_ "GenSigTimeoutTime" BU_SG_REL_ CIOM SG_ 1380 Trail4Type_Towing_ISig_4 6000;
BA_REL_ "GenSigFirstTimeoutTime" BU_SG_REL_ IC3 SG_ 1380 Trail4Type_Towing_ISig_4 24000;
BA_REL_ "GenSigTimeoutTime" BU_SG_REL_ IC3 SG_ 1380 Trail4Type_Towing_ISig_4 6000;
BA_REL_ "GenSigFirstTimeoutTime" BU_SG_REL_ CIOM SG_ 1380 Trail4Type_TrailType_ISig_4 24000;
BA_REL_ "GenSigTimeoutTime" BU_SG_REL_ CIOM SG_ 1380 Trail4Type_TrailType_ISig_4 6000;
BA_REL_ "GenSigFirstTimeoutTime" BU_SG_REL_ IC3 SG_ 1380 Trail4Type_TrailType_ISig_4 24000;
BA_REL_ "GenSigTimeoutTime" BU_SG_REL_ IC3 SG_ 1380 Trail4Type_TrailType_ISig_4 6000;
BA_REL_ "GenSigFirstTimeoutTime" BU_SG_REL_ IC3 SG_ 1380 Trail5Type_TrailType_ISig_4 24000;
BA_REL_ "GenSigTimeoutTime" BU_SG_REL_ IC3 SG_ 1380 Trail5Type_TrailType_ISig_4 6000;
BA_REL_ "GenSigFirstTimeoutTime" BU_SG_REL_ CIOM SG_ 1380 Trail5Type_TrailType_ISig_4 24000;
BA_REL_ "GenSigTimeoutTime" BU_SG_REL_ CIOM SG_ 1380 Trail5Type_TrailType_ISig_4 6000;
BA_REL_ "GenSigFirstTimeoutTime" BU_SG_REL_ IC3 SG_ 1380 Trail5Type_Towing_ISig_4 24000;
BA_REL_ "GenSigTimeoutTime" BU_SG_REL_ IC3 SG_ 1380 Trail5Type_Towing_ISig_4 6000;
BA_REL_ "GenSigFirstTimeoutTime" BU_SG_REL_ CIOM SG_ 1380 Trail5Type_Towing_ISig_4 24000;
BA_REL_ "GenSigTimeoutTime" BU_SG_REL_ CIOM SG_ 1380 Trail5Type_Towing_ISig_4 6000;
BA_REL_ "GenSigFirstTimeoutTime" BU_SG_REL_ CIOM SG_ 1378 Trail1Type_Towing_ISig_4 24000;
BA_REL_ "GenSigTimeoutTime" BU_SG_REL_ CIOM SG_ 1378 Trail1Type_Towing_ISig_4 6000;
BA_REL_ "GenSigFirstTimeoutTime" BU_SG_REL_ IC3 SG_ 1378 Trail1Type_Towing_ISig_4 24000;
BA_REL_ "GenSigTimeoutTime" BU_SG_REL_ IC3 SG_ 1378 Trail1Type_Towing_ISig_4 6000;
BA_REL_ "GenSigFirstTimeoutTime" BU_SG_REL_ IC3 SG_ 1378 UncalibratedTruckLoad_ISig_4 24000;
BA_REL_ "GenSigTimeoutTime" BU_SG_REL_ IC3 SG_ 1378 UncalibratedTruckLoad_ISig_4 6000;
BA_REL_ "GenSigFirstTimeoutTime" BU_SG_REL_ IC3 SG_ 1378 UncalibratedCombinationLoad_ISig 24000;
BA_REL_ "GenSigTimeoutTime" BU_SG_REL_ IC3 SG_ 1378 UncalibratedCombinationLoad_ISig 6000;
BA_REL_ "GenSigFirstTimeoutTime" BU_SG_REL_ CIOM SG_ 1378 Trail1Type_TrailType_ISig_4 24000;
BA_REL_ "GenSigTimeoutTime" BU_SG_REL_ CIOM SG_ 1378 Trail1Type_TrailType_ISig_4 6000;
BA_REL_ "GenSigFirstTimeoutTime" BU_SG_REL_ IC3 SG_ 1378 Trail1Type_TrailType_ISig_4 24000;
BA_REL_ "GenSigTimeoutTime" BU_SG_REL_ IC3 SG_ 1378 Trail1Type_TrailType_ISig_4 6000;
BA_REL_ "GenSigFirstTimeoutTime" BU_SG_REL_ CIOM SG_ 1378 Trail2Type_Towing_ISig_4 24000;
BA_REL_ "GenSigTimeoutTime" BU_SG_REL_ CIOM SG_ 1378 Trail2Type_Towing_ISig_4 6000;
BA_REL_ "GenSigFirstTimeoutTime" BU_SG_REL_ IC3 SG_ 1378 Trail2Type_Towing_ISig_4 24000;
BA_REL_ "GenSigTimeoutTime" BU_SG_REL_ IC3 SG_ 1378 Trail2Type_Towing_ISig_4 6000;
BA_REL_ "GenSigFirstTimeoutTime" BU_SG_REL_ CIOM SG_ 1378 Trail2Type_TrailType_ISig_4 24000;
BA_REL_ "GenSigTimeoutTime" BU_SG_REL_ CIOM SG_ 1378 Trail2Type_TrailType_ISig_4 6000;
BA_REL_ "GenSigFirstTimeoutTime" BU_SG_REL_ IC3 SG_ 1378 Trail2Type_TrailType_ISig_4 24000;
BA_REL_ "GenSigTimeoutTime" BU_SG_REL_ IC3 SG_ 1378 Trail2Type_TrailType_ISig_4 6000;
BA_REL_ "GenSigFirstTimeoutTime" BU_SG_REL_ IC3 SG_ 643 RearAxleGroupLoad_ISig_4 24000;
BA_REL_ "GenSigTimeoutTime" BU_SG_REL_ IC3 SG_ 643 RearAxleGroupLoad_ISig_4 6000;
BA_REL_ "GenSigFirstTimeoutTime" BU_SG_REL_ BBM SG_ 643 RelCargoLoadTrailer1_ISig_4 24000;
BA_REL_ "GenSigTimeoutTime" BU_SG_REL_ BBM SG_ 643 RelCargoLoadTrailer1_ISig_4 6000;
BA_REL_ "GenSigFirstTimeoutTime" BU_SG_REL_ IC3 SG_ 643 RelCargoLoadTrailer1_ISig_4 24000;
BA_REL_ "GenSigTimeoutTime" BU_SG_REL_ IC3 SG_ 643 RelCargoLoadTrailer1_ISig_4 6000;
BA_REL_ "GenSigFirstTimeoutTime" BU_SG_REL_ CIOM SG_ 643 RelCargoLoadTrailer1_ISig_4 24000;
BA_REL_ "GenSigTimeoutTime" BU_SG_REL_ CIOM SG_ 643 RelCargoLoadTrailer1_ISig_4 6000;
BA_REL_ "GenSigFirstTimeoutTime" BU_SG_REL_ IC3 SG_ 643 RelCargoLoadTrailer5_ISig_4 24000;
BA_REL_ "GenSigTimeoutTime" BU_SG_REL_ IC3 SG_ 643 RelCargoLoadTrailer5_ISig_4 6000;
BA_REL_ "GenSigFirstTimeoutTime" BU_SG_REL_ BBM SG_ 643 RelCargoLoadTrailer5_ISig_4 24000;
BA_REL_ "GenSigTimeoutTime" BU_SG_REL_ BBM SG_ 643 RelCargoLoadTrailer5_ISig_4 6000;
BA_REL_ "GenSigFirstTimeoutTime" BU_SG_REL_ CIOM SG_ 643 RelCargoLoadTrailer5_ISig_4 24000;
BA_REL_ "GenSigTimeoutTime" BU_SG_REL_ CIOM SG_ 643 RelCargoLoadTrailer5_ISig_4 6000;
BA_REL_ "GenSigFirstTimeoutTime" BU_SG_REL_ IC3 SG_ 643 FrontAxleGroupLoad_ISig_4 24000;
BA_REL_ "GenSigTimeoutTime" BU_SG_REL_ IC3 SG_ 643 FrontAxleGroupLoad_ISig_4 6000;
BA_REL_ "GenSigFirstTimeoutTime" BU_SG_REL_ IC3 SG_ 533 RelCargoLoadTrailer4_ISig_4 12000;
BA_REL_ "GenSigTimeoutTime" BU_SG_REL_ IC3 SG_ 533 RelCargoLoadTrailer4_ISig_4 3000;
BA_REL_ "GenSigFirstTimeoutTime" BU_SG_REL_ CIOM SG_ 533 RelCargoLoadTrailer4_ISig_4 12000;
BA_REL_ "GenSigTimeoutTime" BU_SG_REL_ CIOM SG_ 533 RelCargoLoadTrailer4_ISig_4 3000;
BA_REL_ "GenSigFirstTimeoutTime" BU_SG_REL_ BBM SG_ 533 RelCargoLoadTrailer4_ISig_4 12000;
BA_REL_ "GenSigTimeoutTime" BU_SG_REL_ BBM SG_ 533 RelCargoLoadTrailer4_ISig_4 3000;
BA_REL_ "GenSigFirstTimeoutTime" BU_SG_REL_ IC3 SG_ 421 LNGConsumedVehicleStopped 12000;
BA_REL_ "GenSigTimeoutTime" BU_SG_REL_ IC3 SG_ 421 LNGConsumedVehicleStopped 3000;
BA_REL_ "GenSigFirstTimeoutTime" BU_SG_REL_ CIOM SG_ 421 RelCargoLoadTruck_ISig_4 12000;
BA_REL_ "GenSigTimeoutTime" BU_SG_REL_ CIOM SG_ 421 RelCargoLoadTruck_ISig_4 3000;
BA_REL_ "GenSigFirstTimeoutTime" BU_SG_REL_ IC3 SG_ 421 RelCargoLoadTruck_ISig_4 12000;
BA_REL_ "GenSigTimeoutTime" BU_SG_REL_ IC3 SG_ 421 RelCargoLoadTruck_ISig_4 3000;
BA_REL_ "GenSigFirstTimeoutTime" BU_SG_REL_ BBM SG_ 421 RelCargoLoadTruck_ISig_4 12000;
BA_REL_ "GenSigTimeoutTime" BU_SG_REL_ BBM SG_ 421 RelCargoLoadTruck_ISig_4 3000;
BA_REL_ "GenSigFirstTimeoutTime" BU_SG_REL_ IC3 SG_ 323 LoadTrailer5_ISig_4 12000;
BA_REL_ "GenSigTimeoutTime" BU_SG_REL_ IC3 SG_ 323 LoadTrailer5_ISig_4 3000;
BA_REL_ "GenSigFirstTimeoutTime" BU_SG_REL_ CIOM SG_ 323 LoadTrailer5_ISig_4 12000;
BA_REL_ "GenSigTimeoutTime" BU_SG_REL_ CIOM SG_ 323 LoadTrailer5_ISig_4 3000;
BA_REL_ "GenSigFirstTimeoutTime" BU_SG_REL_ BBM SG_ 323 LoadTrailer5_ISig_4 12000;
BA_REL_ "GenSigTimeoutTime" BU_SG_REL_ BBM SG_ 323 LoadTrailer5_ISig_4 3000;
BA_REL_ "GenSigFirstTimeoutTime" BU_SG_REL_ IC3 SG_ 323 UncalLoadTrkRAxle3_ISig_4 12000;
BA_REL_ "GenSigTimeoutTime" BU_SG_REL_ IC3 SG_ 323 UncalLoadTrkRAxle3_ISig_4 3000;
BA_REL_ "GenSigFirstTimeoutTime" BU_SG_REL_ IC3 SG_ 323 LoadTrailer4Back_ISig_4 12000;
BA_REL_ "GenSigTimeoutTime" BU_SG_REL_ IC3 SG_ 323 LoadTrailer4Back_ISig_4 3000;
BA_REL_ "GenSigFirstTimeoutTime" BU_SG_REL_ IC3 SG_ 323 LoadTrailer2Front_ISig_4 12000;
BA_REL_ "GenSigTimeoutTime" BU_SG_REL_ IC3 SG_ 323 LoadTrailer2Front_ISig_4 3000;
BA_REL_ "GenSigFirstTimeoutTime" BU_SG_REL_ IC3 SG_ 310 RelCargoLoadTrailer2_ISig_4 12000;
BA_REL_ "GenSigTimeoutTime" BU_SG_REL_ IC3 SG_ 310 RelCargoLoadTrailer2_ISig_4 3000;
BA_REL_ "GenSigFirstTimeoutTime" BU_SG_REL_ BBM SG_ 310 RelCargoLoadTrailer2_ISig_4 12000;
BA_REL_ "GenSigTimeoutTime" BU_SG_REL_ BBM SG_ 310 RelCargoLoadTrailer2_ISig_4 3000;
BA_REL_ "GenSigFirstTimeoutTime" BU_SG_REL_ CIOM SG_ 310 RelCargoLoadTrailer2_ISig_4 12000;
BA_REL_ "GenSigTimeoutTime" BU_SG_REL_ CIOM SG_ 310 RelCargoLoadTrailer2_ISig_4 3000;
BA_REL_ "GenSigFirstTimeoutTime" BU_SG_REL_ BBM SG_ 310 RelCargoLoadTrailer3_ISig_4 12000;
BA_REL_ "GenSigTimeoutTime" BU_SG_REL_ BBM SG_ 310 RelCargoLoadTrailer3_ISig_4 3000;
BA_REL_ "GenSigFirstTimeoutTime" BU_SG_REL_ IC3 SG_ 310 RelCargoLoadTrailer3_ISig_4 12000;
BA_REL_ "GenSigTimeoutTime" BU_SG_REL_ IC3 SG_ 310 RelCargoLoadTrailer3_ISig_4 3000;
BA_REL_ "GenSigFirstTimeoutTime" BU_SG_REL_ CIOM SG_ 310 RelCargoLoadTrailer3_ISig_4 12000;
BA_REL_ "GenSigTimeoutTime" BU_SG_REL_ CIOM SG_ 310 RelCargoLoadTrailer3_ISig_4 3000;
BA_REL_ "GenSigFirstTimeoutTime" BU_SG_REL_ IC3 SG_ 310 MainBeamLEDStatusLeft_ISig_4 12000;
BA_REL_ "GenSigTimeoutTime" BU_SG_REL_ IC3 SG_ 310 MainBeamLEDStatusLeft_ISig_4 3000;
BA_REL_ "GenSigFirstTimeoutTime" BU_SG_REL_ IC3 SG_ 310 MainBeamLEDStatusRight_ISig_4 12000;
BA_REL_ "GenSigTimeoutTime" BU_SG_REL_ IC3 SG_ 310 MainBeamLEDStatusRight_ISig_4 3000;
BA_REL_ "GenSigFirstTimeoutTime" BU_SG_REL_ IC3 SG_ 1367 DistanceToEmptyLNG_ISig_4 24000;
BA_REL_ "GenSigTimeoutTime" BU_SG_REL_ IC3 SG_ 1367 DistanceToEmptyLNG_ISig_4 6000;
BA_REL_ "GenSigFirstTimeoutTime" BU_SG_REL_ IC3 SG_ 1367 DistanceToEmpty_Diesel_ISig_4 24000;
BA_REL_ "GenSigTimeoutTime" BU_SG_REL_ IC3 SG_ 1367 DistanceToEmpty_Diesel_ISig_4 6000;
BA_REL_ "GenSigFirstTimeoutTime" BU_SG_REL_ IC3 SG_ 1370 Trailer1CalibrationType 6000;
BA_REL_ "GenSigTimeoutTime" BU_SG_REL_ IC3 SG_ 1370 Trailer1CalibrationType 1500;
BA_REL_ "GenSigFirstTimeoutTime" BU_SG_REL_ IC3 SG_ 1370 FrontConspicLamp_stat_HiLeft_ISi 6000;
BA_REL_ "GenSigTimeoutTime" BU_SG_REL_ IC3 SG_ 1370 FrontConspicLamp_stat_HiLeft_ISi 1500;
BA_REL_ "GenSigFirstTimeoutTime" BU_SG_REL_ IC3 SG_ 1370 TrailerDirIndLeftOutputStat_ISig 6000;
BA_REL_ "GenSigTimeoutTime" BU_SG_REL_ IC3 SG_ 1370 TrailerDirIndLeftOutputStat_ISig 1500;
BA_REL_ "GenSigFirstTimeoutTime" BU_SG_REL_ IC3 SG_ 1370 JumpChargeInterface_stat_ISig_4 6000;
BA_REL_ "GenSigTimeoutTime" BU_SG_REL_ IC3 SG_ 1370 JumpChargeInterface_stat_ISig_4 1500;
BA_REL_ "GenSigFirstTimeoutTime" BU_SG_REL_ IC3 SG_ 1370 TrailerPosLightLeftOutputStat_IS 6000;
BA_REL_ "GenSigTimeoutTime" BU_SG_REL_ IC3 SG_ 1370 TrailerPosLightLeftOutputStat_IS 1500;
BA_REL_ "GenSigFirstTimeoutTime" BU_SG_REL_ IC3 SG_ 1370 TruckCalibrated 6000;
BA_REL_ "GenSigTimeoutTime" BU_SG_REL_ IC3 SG_ 1370 TruckCalibrated 1500;
BA_REL_ "GenSigFirstTimeoutTime" BU_SG_REL_ IC3 SG_ 1370 Trailer5CalibrationType 6000;
BA_REL_ "GenSigTimeoutTime" BU_SG_REL_ IC3 SG_ 1370 Trailer5CalibrationType 1500;
BA_REL_ "GenSigFirstTimeoutTime" BU_SG_REL_ IC3 SG_ 1370 Trailer2CalibrationType 6000;
BA_REL_ "GenSigTimeoutTime" BU_SG_REL_ IC3 SG_ 1370 Trailer2CalibrationType 1500;
BA_REL_ "GenSigFirstTimeoutTime" BU_SG_REL_ IC3 SG_ 1370 Trailer4CalibrationType 6000;
BA_REL_ "GenSigTimeoutTime" BU_SG_REL_ IC3 SG_ 1370 Trailer4CalibrationType 1500;
BA_REL_ "GenSigFirstTimeoutTime" BU_SG_REL_ IC3 SG_ 1370 TrailerBrakeLightOutputStat_ISig 6000;
BA_REL_ "GenSigTimeoutTime" BU_SG_REL_ IC3 SG_ 1370 TrailerBrakeLightOutputStat_ISig 1500;
BA_REL_ "GenSigFirstTimeoutTime" BU_SG_REL_ IC3 SG_ 1370 FrontConspicLamp_stat_LoRight_IS 6000;
BA_REL_ "GenSigTimeoutTime" BU_SG_REL_ IC3 SG_ 1370 FrontConspicLamp_stat_LoRight_IS 1500;
BA_REL_ "GenSigFirstTimeoutTime" BU_SG_REL_ IC3 SG_ 1370 FrontConspicLamp_stat_LoLeft_ISi 6000;
BA_REL_ "GenSigTimeoutTime" BU_SG_REL_ IC3 SG_ 1370 FrontConspicLamp_stat_LoLeft_ISi 1500;
BA_REL_ "GenSigFirstTimeoutTime" BU_SG_REL_ IC3 SG_ 1370 NumberOfSavedTrailers 6000;
BA_REL_ "GenSigTimeoutTime" BU_SG_REL_ IC3 SG_ 1370 NumberOfSavedTrailers 1500;
BA_REL_ "GenSigFirstTimeoutTime" BU_SG_REL_ IC3 SG_ 1370 TrailerDirIndRightOutputStat_ISi 6000;
BA_REL_ "GenSigTimeoutTime" BU_SG_REL_ IC3 SG_ 1370 TrailerDirIndRightOutputStat_ISi 1500;
BA_REL_ "GenSigFirstTimeoutTime" BU_SG_REL_ IC3 SG_ 1370 TrailerPosLightRightOutputStat_I 6000;
BA_REL_ "GenSigTimeoutTime" BU_SG_REL_ IC3 SG_ 1370 TrailerPosLightRightOutputStat_I 1500;
BA_REL_ "GenSigFirstTimeoutTime" BU_SG_REL_ IC3 SG_ 1370 Trailer3CalibrationType 6000;
BA_REL_ "GenSigTimeoutTime" BU_SG_REL_ IC3 SG_ 1370 Trailer3CalibrationType 1500;
BA_REL_ "GenSigFirstTimeoutTime" BU_SG_REL_ IC3 SG_ 1370 FrontConspicLamp_stat_HiRight_IS 6000;
BA_REL_ "GenSigTimeoutTime" BU_SG_REL_ IC3 SG_ 1370 FrontConspicLamp_stat_HiRight_IS 1500;
BA_REL_ "GenSigFirstTimeoutTime" BU_SG_REL_ DACU SG_ 546 FASSaturated_ISig_4 3000;
BA_REL_ "GenSigTimeoutTime" BU_SG_REL_ DACU SG_ 546 FASSaturated_ISig_4 120;
BA_REL_ "GenSigFirstTimeoutTime" BU_SG_REL_ IC3 SG_ 546 OverSteerGuidanceStatus_ISig_4 3000;
BA_REL_ "GenSigTimeoutTime" BU_SG_REL_ IC3 SG_ 546 OverSteerGuidanceStatus_ISig_4 120;
BA_REL_ "GenSigFirstTimeoutTime" BU_SG_REL_ DACU SG_ 546 FASFullyOperational_ISig_4 3000;
BA_REL_ "GenSigTimeoutTime" BU_SG_REL_ DACU SG_ 546 FASFullyOperational_ISig_4 120;
BA_REL_ "GenSigFirstTimeoutTime" BU_SG_REL_ BBM SG_ 546 FASFullyOperational_ISig_4 3000;
BA_REL_ "GenSigTimeoutTime" BU_SG_REL_ BBM SG_ 546 FASFullyOperational_ISig_4 120;
BA_REL_ "GenSigFirstTimeoutTime" BU_SG_REL_ DACU SG_ 546 FASFunctionInControl_ISig_4 3000;
BA_REL_ "GenSigTimeoutTime" BU_SG_REL_ DACU SG_ 546 FASFunctionInControl_ISig_4 120;
BA_REL_ "GenSigFirstTimeoutTime" BU_SG_REL_ DACU SG_ 546 FrontRoadWheelAngleEstimate_ISig 3000;
BA_REL_ "GenSigTimeoutTime" BU_SG_REL_ DACU SG_ 546 FrontRoadWheelAngleEstimate_ISig 120;
BA_REL_ "GenSigFirstTimeoutTime" BU_SG_REL_ BBM SG_ 546 FrontRoadWheelAngleEstimate_ISig 3600;
BA_REL_ "GenSigTimeoutTime" BU_SG_REL_ BBM SG_ 546 FrontRoadWheelAngleEstimate_ISig 120;
BA_REL_ "GenSigFirstTimeoutTime" BU_SG_REL_ DACU SG_ 546 DriverSteeringTorqueEstimate_ISi 3000;
BA_REL_ "GenSigTimeoutTime" BU_SG_REL_ DACU SG_ 546 DriverSteeringTorqueEstimate_ISi 120;
BA_REL_ "GenSigFirstTimeoutTime" BU_SG_REL_ DACU SG_ 546 DriverSteeringTqEstimateConf_ISi 3000;
BA_REL_ "GenSigTimeoutTime" BU_SG_REL_ DACU SG_ 546 DriverSteeringTqEstimateConf_ISi 120;
BA_REL_ "GenSigFirstTimeoutTime" BU_SG_REL_ IC3 SG_ 1405 ActualFasPersSettingsButton_ISig 24000;
BA_REL_ "GenSigTimeoutTime" BU_SG_REL_ IC3 SG_ 1405 ActualFasPersSettingsButton_ISig 6000;
BA_REL_ "GenSigFirstTimeoutTime" BU_SG_REL_ IC3 SG_ 1405 FasUsrDefStiffStraightSetting_IS 24000;
BA_REL_ "GenSigTimeoutTime" BU_SG_REL_ IC3 SG_ 1405 FasUsrDefStiffStraightSetting_IS 6000;
BA_REL_ "GenSigFirstTimeoutTime" BU_SG_REL_ IC3 SG_ 1405 FuelLostByBraking_ISig_4 24000;
BA_REL_ "GenSigTimeoutTime" BU_SG_REL_ IC3 SG_ 1405 FuelLostByBraking_ISig_4 6000;
BA_REL_ "GenSigFirstTimeoutTime" BU_SG_REL_ IC3 SG_ 1405 ActualFasManualOffsetSetting_ISi 24000;
BA_REL_ "GenSigTimeoutTime" BU_SG_REL_ IC3 SG_ 1405 ActualFasManualOffsetSetting_ISi 6000;
BA_REL_ "GenSigFirstTimeoutTime" BU_SG_REL_ IC3 SG_ 1405 FasUsrDefinedDampingSetting_ISig 24000;
BA_REL_ "GenSigTimeoutTime" BU_SG_REL_ IC3 SG_ 1405 FasUsrDefinedDampingSetting_ISig 6000;
BA_REL_ "GenSigFirstTimeoutTime" BU_SG_REL_ IC3 SG_ 1405 FasDriver_ISig_4 24000;
BA_REL_ "GenSigTimeoutTime" BU_SG_REL_ IC3 SG_ 1405 FasDriver_ISig_4 6000;
BA_REL_ "GenSigFirstTimeoutTime" BU_SG_REL_ IC3 SG_ 1405 FasUsrDefLowSpeedReturnSetting_I 24000;
BA_REL_ "GenSigTimeoutTime" BU_SG_REL_ IC3 SG_ 1405 FasUsrDefLowSpeedReturnSetting_I 6000;
BA_REL_ "GenSigFirstTimeoutTime" BU_SG_REL_ IC3 SG_ 1405 FasUsrDefStiffnessCurveSetting_I 24000;
BA_REL_ "GenSigTimeoutTime" BU_SG_REL_ IC3 SG_ 1405 FasUsrDefStiffnessCurveSetting_I 6000;
BA_REL_ "GenSigFirstTimeoutTime" BU_SG_REL_ IC3 SG_ 830 PS_PosLightDoorOpen 3000;
BA_REL_ "GenSigTimeoutTime" BU_SG_REL_ IC3 SG_ 830 PS_PosLightDoorOpen 600;
BA_REL_ "GenSigFirstTimeoutTime" BU_SG_REL_ IC3 SG_ 830 PS_FogLightRear 3000;
BA_REL_ "GenSigTimeoutTime" BU_SG_REL_ IC3 SG_ 830 PS_FogLightRear 600;
BA_REL_ "GenSigFirstTimeoutTime" BU_SG_REL_ CIOM SG_ 830 TrailerBodyLampDI_stat 6000;
BA_REL_ "GenSigTimeoutTime" BU_SG_REL_ CIOM SG_ 830 TrailerBodyLampDI_stat 6000;
BA_REL_ "GenSigFirstTimeoutTime" BU_SG_REL_ IC3 SG_ 830 PV_HeadLightLevel 3000;
BA_REL_ "GenSigTimeoutTime" BU_SG_REL_ IC3 SG_ 830 PV_HeadLightLevel 600;
BA_REL_ "GenSigFirstTimeoutTime" BU_SG_REL_ CIOM SG_ 830 TrailerBodyLampFdbk_stat 6000;
BA_REL_ "GenSigTimeoutTime" BU_SG_REL_ CIOM SG_ 830 TrailerBodyLampFdbk_stat 6000;
BA_REL_ "GenSigFirstTimeoutTime" BU_SG_REL_ IC3 SG_ 830 PS_FogLightFront 3000;
BA_REL_ "GenSigTimeoutTime" BU_SG_REL_ IC3 SG_ 830 PS_FogLightFront 600;
BA_REL_ "GenSigFirstTimeoutTime" BU_SG_REL_ IC3 SG_ 830 Alcolock_PBReleaseInhibit_ind 3000;
BA_REL_ "GenSigTimeoutTime" BU_SG_REL_ IC3 SG_ 830 Alcolock_PBReleaseInhibit_ind 600;
BA_REL_ "GenSigFirstTimeoutTime" BU_SG_REL_ IC3 SG_ 830 DHCNotificationReq 3000;
BA_REL_ "GenSigTimeoutTime" BU_SG_REL_ IC3 SG_ 830 DHCNotificationReq 600;
BA_REL_ "GenSigFirstTimeoutTime" BU_SG_REL_ IC3 SG_ 830 DriverCrank_rqst 3000;
BA_REL_ "GenSigTimeoutTime" BU_SG_REL_ IC3 SG_ 830 DriverCrank_rqst 600;
BA_REL_ "GenSigFirstTimeoutTime" BU_SG_REL_ IC3 SG_ 830 PS_HeadLightAdjustment 3000;
BA_REL_ "GenSigTimeoutTime" BU_SG_REL_ IC3 SG_ 830 PS_HeadLightAdjustment 600;
BA_REL_ "GenSigFirstTimeoutTime" BU_SG_REL_ IC3 SG_ 830 PS_MainBeam 3000;
BA_REL_ "GenSigTimeoutTime" BU_SG_REL_ IC3 SG_ 830 PS_MainBeam 600;
BA_REL_ "GenSigFirstTimeoutTime" BU_SG_REL_ IC3 SG_ 830 InstFuel_ConsumpValue 3000;
BA_REL_ "GenSigTimeoutTime" BU_SG_REL_ IC3 SG_ 830 InstFuel_ConsumpValue 600;
BA_REL_ "GenSigFirstTimeoutTime" BU_SG_REL_ IC3 SG_ 830 InstFuel_VehicleMoving 3000;
BA_REL_ "GenSigTimeoutTime" BU_SG_REL_ IC3 SG_ 830 InstFuel_VehicleMoving 600;
BA_REL_ "GenSigFirstTimeoutTime" BU_SG_REL_ IC3 SG_ 830 PS_AFSAllowed_ISig_4 3000;
BA_REL_ "GenSigTimeoutTime" BU_SG_REL_ IC3 SG_ 830 PS_AFSAllowed_ISig_4 600;
BA_REL_ "GenSigFirstTimeoutTime" BU_SG_REL_ IC3 SG_ 830 PS_AFS 3000;
BA_REL_ "GenSigTimeoutTime" BU_SG_REL_ IC3 SG_ 830 PS_AFS 600;
BA_REL_ "GenSigFirstTimeoutTime" BU_SG_REL_ CIOM SG_ 830 AC2CoolingFanControl_rqst 6000;
BA_REL_ "GenSigTimeoutTime" BU_SG_REL_ CIOM SG_ 830 AC2CoolingFanControl_rqst 6000;
BA_REL_ "GenSigFirstTimeoutTime" BU_SG_REL_ IC3 SG_ 830 DHCStatus 3000;
BA_REL_ "GenSigTimeoutTime" BU_SG_REL_ IC3 SG_ 830 DHCStatus 600;
BA_REL_ "GenSigFirstTimeoutTime" BU_SG_REL_ IC3 SG_ 830 PS_PositionLight 3000;
BA_REL_ "GenSigTimeoutTime" BU_SG_REL_ IC3 SG_ 830 PS_PositionLight 600;
BA_REL_ "GenSigFirstTimeoutTime" BU_SG_REL_ IC3 SG_ 1071 EcoCruiseSetSpeed 3600;
BA_REL_ "GenSigTimeoutTime" BU_SG_REL_ IC3 SG_ 1071 EcoCruiseSetSpeed 900;
BA_REL_ "GenSigFirstTimeoutTime" BU_SG_REL_ BBM SG_ 1071 Alcolock_stat_ISig_4 3600;
BA_REL_ "GenSigTimeoutTime" BU_SG_REL_ BBM SG_ 1071 Alcolock_stat_ISig_4 900;
BA_REL_ "GenSigFirstTimeoutTime" BU_SG_REL_ IC3 SG_ 1071 CTA_PBReleaseInhibit_ind 3000;
BA_REL_ "GenSigTimeoutTime" BU_SG_REL_ IC3 SG_ 1071 CTA_PBReleaseInhibit_ind 900;
BA_REL_ "GenSigFirstTimeoutTime" BU_SG_REL_ BBM SG_ 1071 CTA_PBReleaseInhibit_ind 3600;
BA_REL_ "GenSigTimeoutTime" BU_SG_REL_ BBM SG_ 1071 CTA_PBReleaseInhibit_ind 900;
BA_REL_ "GenSigFirstTimeoutTime" BU_SG_REL_ EMS SG_ 1071 EngOvrrideCtrlStat_FireTruckMode 3000;
BA_REL_ "GenSigTimeoutTime" BU_SG_REL_ EMS SG_ 1071 EngOvrrideCtrlStat_FireTruckMode 600;
BA_REL_ "GenSigFirstTimeoutTime" BU_SG_REL_ IC3 SG_ 1071 DHCActualSetSpeed 3000;
BA_REL_ "GenSigTimeoutTime" BU_SG_REL_ IC3 SG_ 1071 DHCActualSetSpeed 900;
BA_REL_ "GenSigFirstTimeoutTime" BU_SG_REL_ EMS SG_ 1071 EngOvrrideCtrlStat_StartOvrrMode 3000;
BA_REL_ "GenSigTimeoutTime" BU_SG_REL_ EMS SG_ 1071 EngOvrrideCtrlStat_StartOvrrMode 600;
BA_REL_ "GenSigFirstTimeoutTime" BU_SG_REL_ EMS SG_ 1071 EngOvrrideCtrlStat_ProtOvrrMode 3000;
BA_REL_ "GenSigTimeoutTime" BU_SG_REL_ EMS SG_ 1071 EngOvrrideCtrlStat_ProtOvrrMode 600;
BA_REL_ "GenSigFirstTimeoutTime" BU_SG_REL_ TECU SG_ 1071 XRSLBTargetSpeedRequest 3600;
BA_REL_ "GenSigTimeoutTime" BU_SG_REL_ TECU SG_ 1071 XRSLBTargetSpeedRequest 900;
BA_REL_ "GenSigFirstTimeoutTime" BU_SG_REL_ EMS SG_ 1071 XRSLBTargetSpeedRequest 3000;
BA_REL_ "GenSigTimeoutTime" BU_SG_REL_ EMS SG_ 1071 XRSLBTargetSpeedRequest 600;
BA_REL_ "GenSigFirstTimeoutTime" BU_SG_REL_ IC3 SG_ 1068 EcoCruiseMinSpeedLev3 3600;
BA_REL_ "GenSigTimeoutTime" BU_SG_REL_ IC3 SG_ 1068 EcoCruiseMinSpeedLev3 900;
BA_REL_ "GenSigFirstTimeoutTime" BU_SG_REL_ IC3 SG_ 1068 EcoCruiseMinSpeedLev0 3600;
BA_REL_ "GenSigTimeoutTime" BU_SG_REL_ IC3 SG_ 1068 EcoCruiseMinSpeedLev0 900;
BA_REL_ "GenSigFirstTimeoutTime" BU_SG_REL_ IC3 SG_ 1068 EcoCruiseMinSpeedLev1 3600;
BA_REL_ "GenSigTimeoutTime" BU_SG_REL_ IC3 SG_ 1068 EcoCruiseMinSpeedLev1 900;
BA_REL_ "GenSigFirstTimeoutTime" BU_SG_REL_ IC3 SG_ 1068 EcoCruiseMinSpeedLev2 3600;
BA_REL_ "GenSigTimeoutTime" BU_SG_REL_ IC3 SG_ 1068 EcoCruiseMinSpeedLev2 900;
BA_REL_ "GenSigFirstTimeoutTime" BU_SG_REL_ IC3 SG_ 1065 EcoCruiseMaxSpeedLev1 3600;
BA_REL_ "GenSigTimeoutTime" BU_SG_REL_ IC3 SG_ 1065 EcoCruiseMaxSpeedLev1 900;
BA_REL_ "GenSigFirstTimeoutTime" BU_SG_REL_ IC3 SG_ 1065 EcoCruiseMaxSpeedLev0 3600;
BA_REL_ "GenSigTimeoutTime" BU_SG_REL_ IC3 SG_ 1065 EcoCruiseMaxSpeedLev0 900;
BA_REL_ "GenSigFirstTimeoutTime" BU_SG_REL_ IC3 SG_ 1065 EcoCruiseMaxSpeedLev2 3600;
BA_REL_ "GenSigTimeoutTime" BU_SG_REL_ IC3 SG_ 1065 EcoCruiseMaxSpeedLev2 900;
BA_REL_ "GenSigFirstTimeoutTime" BU_SG_REL_ IC3 SG_ 1065 EcoCruiseMaxSpeedLev3 3600;
BA_REL_ "GenSigTimeoutTime" BU_SG_REL_ IC3 SG_ 1065 EcoCruiseMaxSpeedLev3 900;
BA_REL_ "GenSigFirstTimeoutTime" BU_SG_REL_ IC3 SG_ 1062 EcoCruiseCCBSetSpeedLev2 3600;
BA_REL_ "GenSigTimeoutTime" BU_SG_REL_ IC3 SG_ 1062 EcoCruiseCCBSetSpeedLev2 900;
BA_REL_ "GenSigFirstTimeoutTime" BU_SG_REL_ IC3 SG_ 1062 EcoCruiseCCBSetSpeedLev1 3600;
BA_REL_ "GenSigTimeoutTime" BU_SG_REL_ IC3 SG_ 1062 EcoCruiseCCBSetSpeedLev1 900;
BA_REL_ "GenSigFirstTimeoutTime" BU_SG_REL_ IC3 SG_ 1062 EcoCruiseCCBSetSpeedLev3 3600;
BA_REL_ "GenSigTimeoutTime" BU_SG_REL_ IC3 SG_ 1062 EcoCruiseCCBSetSpeedLev3 900;
BA_REL_ "GenSigFirstTimeoutTime" BU_SG_REL_ IC3 SG_ 1062 EcoCruiseCCBSetSpeedLev0 3600;
BA_REL_ "GenSigTimeoutTime" BU_SG_REL_ IC3 SG_ 1062 EcoCruiseCCBSetSpeedLev0 900;
BA_REL_ "GenSigFirstTimeoutTime" BU_SG_REL_ IC3 SG_ 1404 EngineGreenAreaOutLNG_ISig_4 24000;
BA_REL_ "GenSigTimeoutTime" BU_SG_REL_ IC3 SG_ 1404 EngineGreenAreaOutLNG_ISig_4 6000;
BA_REL_ "GenSigFirstTimeoutTime" BU_SG_REL_ IC3 SG_ 1404 EngineGreenAreaLNG_ISig_4 24000;
BA_REL_ "GenSigTimeoutTime" BU_SG_REL_ IC3 SG_ 1404 EngineGreenAreaLNG_ISig_4 6000;
BA_REL_ "GenSigFirstTimeoutTime" BU_SG_REL_ IC3 SG_ 1035 BatteryTempAlert_rqst_ISig_4 3000;
BA_REL_ "GenSigTimeoutTime" BU_SG_REL_ IC3 SG_ 1035 BatteryTempAlert_rqst_ISig_4 600;
BA_REL_ "GenSigFirstTimeoutTime" BU_SG_REL_ IC3 SG_ 1035 APM_TrailerCircPressureStatus_IS 3000;
BA_REL_ "GenSigTimeoutTime" BU_SG_REL_ IC3 SG_ 1035 APM_TrailerCircPressureStatus_IS 600;
BA_REL_ "GenSigFirstTimeoutTime" BU_SG_REL_ IC3 SG_ 1035 BatteryCapacity_ISig_4 3000;
BA_REL_ "GenSigTimeoutTime" BU_SG_REL_ IC3 SG_ 1035 BatteryCapacity_ISig_4 600;
BA_REL_ "GenSigFirstTimeoutTime" BU_SG_REL_ DACU SG_ 1035 Hazard_rqst_ISig_4 3000;
BA_REL_ "GenSigTimeoutTime" BU_SG_REL_ DACU SG_ 1035 Hazard_rqst_ISig_4 600;
BA_REL_ "GenSigFirstTimeoutTime" BU_SG_REL_ IC3 SG_ 1035 Hazard_rqst_ISig_4 3000;
BA_REL_ "GenSigTimeoutTime" BU_SG_REL_ IC3 SG_ 1035 Hazard_rqst_ISig_4 600;
BA_REL_ "GenSigFirstTimeoutTime" BU_SG_REL_ DACU SG_ 1035 CollisionSituationAliveStatus 3000;
BA_REL_ "GenSigTimeoutTime" BU_SG_REL_ DACU SG_ 1035 CollisionSituationAliveStatus 600;
BA_REL_ "GenSigFirstTimeoutTime" BU_SG_REL_ IC3 SG_ 1035 BatterySOCact_ISig_4 3000;
BA_REL_ "GenSigTimeoutTime" BU_SG_REL_ IC3 SG_ 1035 BatterySOCact_ISig_4 600;
BA_REL_ "GenSigFirstTimeoutTime" BU_SG_REL_ IC3 SG_ 1035 Trailer1TPMLostCom_ISig_4 4800;
BA_REL_ "GenSigTimeoutTime" BU_SG_REL_ IC3 SG_ 1035 Trailer1TPMLostCom_ISig_4 1200;
BA_REL_ "GenSigFirstTimeoutTime" BU_SG_REL_ IC3 SG_ 1035 BatterySOCactCriticalAlert_ISig_ 3000;
BA_REL_ "GenSigTimeoutTime" BU_SG_REL_ IC3 SG_ 1035 BatterySOCactCriticalAlert_ISig_ 600;
BA_REL_ "GenSigFirstTimeoutTime" BU_SG_REL_ IC3 SG_ 1035 BatteryTempAlertRawData_rqst_ISi 3000;
BA_REL_ "GenSigTimeoutTime" BU_SG_REL_ IC3 SG_ 1035 BatteryTempAlertRawData_rqst_ISi 600;
BA_REL_ "GenSigFirstTimeoutTime" BU_SG_REL_ CIOM SG_ 1035 FPBRMMIStat_FPBRChangeAck_ISig_4 3000;
BA_REL_ "GenSigTimeoutTime" BU_SG_REL_ CIOM SG_ 1035 FPBRMMIStat_FPBRChangeAck_ISig_4 600;
BA_REL_ "GenSigFirstTimeoutTime" BU_SG_REL_ CIOM SG_ 1035 LivBatteryCharging_stat_ISig_4 3000;
BA_REL_ "GenSigTimeoutTime" BU_SG_REL_ CIOM SG_ 1035 LivBatteryCharging_stat_ISig_4 600;
BA_REL_ "GenSigFirstTimeoutTime" BU_SG_REL_ IC3 SG_ 1035 BatteryTemp_ISig_4 3000;
BA_REL_ "GenSigTimeoutTime" BU_SG_REL_ IC3 SG_ 1035 BatteryTemp_ISig_4 600;
BA_REL_ "GenSigFirstTimeoutTime" BU_SG_REL_ CIOM SG_ 1035 FPBRMMIStat_FPBRStatusInd_ISig_4 3000;
BA_REL_ "GenSigTimeoutTime" BU_SG_REL_ CIOM SG_ 1035 FPBRMMIStat_FPBRStatusInd_ISig_4 600;
BA_REL_ "GenSigFirstTimeoutTime" BU_SG_REL_ DACU SG_ 1035 RS_WasherStatus_ISig_4 3000;
BA_REL_ "GenSigTimeoutTime" BU_SG_REL_ DACU SG_ 1035 RS_WasherStatus_ISig_4 600;
BA_REL_ "GenSigFirstTimeoutTime" BU_SG_REL_ IC3 SG_ 1035 Trailer2TPMLostCom_ISig_4 4800;
BA_REL_ "GenSigTimeoutTime" BU_SG_REL_ IC3 SG_ 1035 Trailer2TPMLostCom_ISig_4 1200;
BA_REL_ "GenSigFirstTimeoutTime" BU_SG_REL_ IC3 SG_ 1035 Rainsensor_Indication_ISig_4 3000;
BA_REL_ "GenSigTimeoutTime" BU_SG_REL_ IC3 SG_ 1035 Rainsensor_Indication_ISig_4 600;
BA_REL_ "GenSigFirstTimeoutTime" BU_SG_REL_ DACU SG_ 1035 CollisionSituationAliveRequest 3000;
BA_REL_ "GenSigTimeoutTime" BU_SG_REL_ DACU SG_ 1035 CollisionSituationAliveRequest 600;
BA_REL_ "GenSigFirstTimeoutTime" BU_SG_REL_ IC3 SG_ 1032 TPMMateTrailerResp_ISig_4 3000;
BA_REL_ "GenSigTimeoutTime" BU_SG_REL_ IC3 SG_ 1032 TPMMateTrailerResp_ISig_4 600;
BA_REL_ "GenSigFirstTimeoutTime" BU_SG_REL_ IC3 SG_ 1032 Trailer2TPMLeakageWarning_ISig_4 3000;
BA_REL_ "GenSigTimeoutTime" BU_SG_REL_ IC3 SG_ 1032 Trailer2TPMLeakageWarning_ISig_4 600;
BA_REL_ "GenSigFirstTimeoutTime" BU_SG_REL_ IC3 SG_ 1032 TPMAutomaticMating_ISig_4 3000;
BA_REL_ "GenSigTimeoutTime" BU_SG_REL_ IC3 SG_ 1032 TPMAutomaticMating_ISig_4 600;
BA_REL_ "GenSigFirstTimeoutTime" BU_SG_REL_ IC3 SG_ 1032 DirectionIndicatorLightsStatus_I 3000;
BA_REL_ "GenSigTimeoutTime" BU_SG_REL_ IC3 SG_ 1032 DirectionIndicatorLightsStatus_I 600;
BA_REL_ "GenSigFirstTimeoutTime" BU_SG_REL_ IC3 SG_ 1032 FrontWheelDifflockRequest_ISig_4 3000;
BA_REL_ "GenSigTimeoutTime" BU_SG_REL_ IC3 SG_ 1032 FrontWheelDifflockRequest_ISig_4 600;
BA_REL_ "GenSigFirstTimeoutTime" BU_SG_REL_ IC3 SG_ 1032 Trailer2TPMMatedStatus_ISig_4 3000;
BA_REL_ "GenSigTimeoutTime" BU_SG_REL_ IC3 SG_ 1032 Trailer2TPMMatedStatus_ISig_4 600;
BA_REL_ "GenSigFirstTimeoutTime" BU_SG_REL_ IC3 SG_ 1032 Trailer1TPMMatedStatus_ISig_4 3000;
BA_REL_ "GenSigTimeoutTime" BU_SG_REL_ IC3 SG_ 1032 Trailer1TPMMatedStatus_ISig_4 600;
BA_REL_ "GenSigFirstTimeoutTime" BU_SG_REL_ IC3 SG_ 1032 CargoLoadResetFeedback 3000;
BA_REL_ "GenSigTimeoutTime" BU_SG_REL_ IC3 SG_ 1032 CargoLoadResetFeedback 600;
BA_REL_ "GenSigFirstTimeoutTime" BU_SG_REL_ IC3 SG_ 1032 TruckTPMLeakageWarning_ISig_4 3000;
BA_REL_ "GenSigTimeoutTime" BU_SG_REL_ IC3 SG_ 1032 TruckTPMLeakageWarning_ISig_4 600;
BA_REL_ "GenSigFirstTimeoutTime" BU_SG_REL_ CIOM SG_ 1032 ExtraSideMarkers_FunctStat 3000;
BA_REL_ "GenSigTimeoutTime" BU_SG_REL_ CIOM SG_ 1032 ExtraSideMarkers_FunctStat 600;
BA_REL_ "GenSigFirstTimeoutTime" BU_SG_REL_ IC3 SG_ 1032 Trailer2TPMPressureWarning_ISig_ 3000;
BA_REL_ "GenSigTimeoutTime" BU_SG_REL_ IC3 SG_ 1032 Trailer2TPMPressureWarning_ISig_ 600;
BA_REL_ "GenSigFirstTimeoutTime" BU_SG_REL_ IC3 SG_ 1032 XRSLActive 3000;
BA_REL_ "GenSigTimeoutTime" BU_SG_REL_ IC3 SG_ 1032 XRSLActive 600;
BA_REL_ "GenSigFirstTimeoutTime" BU_SG_REL_ IC3 SG_ 1032 Trailer1TPMPressureWarning_ISig_ 3000;
BA_REL_ "GenSigTimeoutTime" BU_SG_REL_ IC3 SG_ 1032 Trailer1TPMPressureWarning_ISig_ 600;
BA_REL_ "GenSigFirstTimeoutTime" BU_SG_REL_ IC3 SG_ 1032 Trailer1TPMLeakageWarning_ISig_4 3000;
BA_REL_ "GenSigTimeoutTime" BU_SG_REL_ IC3 SG_ 1032 Trailer1TPMLeakageWarning_ISig_4 600;
BA_REL_ "GenSigFirstTimeoutTime" BU_SG_REL_ IC3 SG_ 1032 LiftAxle1RequestResponse 3000;
BA_REL_ "GenSigTimeoutTime" BU_SG_REL_ IC3 SG_ 1032 LiftAxle1RequestResponse 600;
BA_REL_ "GenSigFirstTimeoutTime" BU_SG_REL_ IC3 SG_ 1032 TruckTPMPressureWarning_ISig_4 3000;
BA_REL_ "GenSigTimeoutTime" BU_SG_REL_ IC3 SG_ 1032 TruckTPMPressureWarning_ISig_4 600;
BA_REL_ "GenSigFirstTimeoutTime" BU_SG_REL_ BBM SG_ 1032 XRSLIndication 3000;
BA_REL_ "GenSigTimeoutTime" BU_SG_REL_ BBM SG_ 1032 XRSLIndication 600;
BA_REL_ "GenSigFirstTimeoutTime" BU_SG_REL_ IC3 SG_ 1032 XRSLIndication 3000;
BA_REL_ "GenSigTimeoutTime" BU_SG_REL_ IC3 SG_ 1032 XRSLIndication 600;
BA_REL_ "GenSigFirstTimeoutTime" BU_SG_REL_ IC3 SG_ 1237 Trailer2TPMFailure_ISig_4 4800;
BA_REL_ "GenSigTimeoutTime" BU_SG_REL_ IC3 SG_ 1237 Trailer2TPMFailure_ISig_4 1200;
BA_REL_ "GenSigFirstTimeoutTime" BU_SG_REL_ IC3 SG_ 1237 TruckTPMTireInfo_Active_ISig_4 4800;
BA_REL_ "GenSigTimeoutTime" BU_SG_REL_ IC3 SG_ 1237 TruckTPMTireInfo_Active_ISig_4 1200;
BA_REL_ "GenSigFirstTimeoutTime" BU_SG_REL_ IC3 SG_ 1237 TruckTPMFailure_ISig_4 4800;
BA_REL_ "GenSigTimeoutTime" BU_SG_REL_ IC3 SG_ 1237 TruckTPMFailure_ISig_4 1200;
BA_REL_ "GenSigFirstTimeoutTime" BU_SG_REL_ IC3 SG_ 1237 TruckTPMTireInfo_TireId_ISig_4 4800;
BA_REL_ "GenSigTimeoutTime" BU_SG_REL_ IC3 SG_ 1237 TruckTPMTireInfo_TireId_ISig_4 1200;
BA_REL_ "GenSigFirstTimeoutTime" BU_SG_REL_ IC3 SG_ 1237 TruckTPMTireInfo_Battery_ISig_4 4800;
BA_REL_ "GenSigTimeoutTime" BU_SG_REL_ IC3 SG_ 1237 TruckTPMTireInfo_Battery_ISig_4 1200;
BA_REL_ "GenSigFirstTimeoutTime" BU_SG_REL_ IC3 SG_ 1237 TruckTPMTireInfo_Temperature_ISi 4800;
BA_REL_ "GenSigTimeoutTime" BU_SG_REL_ IC3 SG_ 1237 TruckTPMTireInfo_Temperature_ISi 1200;
BA_REL_ "GenSigFirstTimeoutTime" BU_SG_REL_ IC3 SG_ 1237 TruckTPMTireInfo_RefPres_ISig_4 4800;
BA_REL_ "GenSigTimeoutTime" BU_SG_REL_ IC3 SG_ 1237 TruckTPMTireInfo_RefPres_ISig_4 1200;
BA_REL_ "GenSigFirstTimeoutTime" BU_SG_REL_ IC3 SG_ 1237 TPMTrailerPositionStat_ISig_4 4800;
BA_REL_ "GenSigTimeoutTime" BU_SG_REL_ IC3 SG_ 1237 TPMTrailerPositionStat_ISig_4 1200;
BA_REL_ "GenSigFirstTimeoutTime" BU_SG_REL_ IC3 SG_ 1237 TruckTPMTireInfo_Pressure_ISig_4 4800;
BA_REL_ "GenSigTimeoutTime" BU_SG_REL_ IC3 SG_ 1237 TruckTPMTireInfo_Pressure_ISig_4 1200;
BA_REL_ "GenSigFirstTimeoutTime" BU_SG_REL_ IC3 SG_ 1237 Trailer1TPMFailure_ISig_4 4800;
BA_REL_ "GenSigTimeoutTime" BU_SG_REL_ IC3 SG_ 1237 Trailer1TPMFailure_ISig_4 1200;
BA_REL_ "GenSigFirstTimeoutTime" BU_SG_REL_ IC3 SG_ 1237 TruckTPMTireInfo_PresWarn_ISig_4 4800;
BA_REL_ "GenSigTimeoutTime" BU_SG_REL_ IC3 SG_ 1237 TruckTPMTireInfo_PresWarn_ISig_4 1200;
BA_REL_ "GenSigFirstTimeoutTime" BU_SG_REL_ IC3 SG_ 1237 TruckTPMTireInfo_LeakageWarn_ISi 4800;
BA_REL_ "GenSigTimeoutTime" BU_SG_REL_ IC3 SG_ 1237 TruckTPMTireInfo_LeakageWarn_ISi 1200;
BA_REL_ "GenSigFirstTimeoutTime" BU_SG_REL_ IC3 SG_ 1234 Trailer2TPMTireInfo_LeakageWarn_ 4800;
BA_REL_ "GenSigTimeoutTime" BU_SG_REL_ IC3 SG_ 1234 Trailer2TPMTireInfo_LeakageWarn_ 1200;
BA_REL_ "GenSigFirstTimeoutTime" BU_SG_REL_ IC3 SG_ 1234 Trailer2TPMTireInfo_RefPres_ISig 4800;
BA_REL_ "GenSigTimeoutTime" BU_SG_REL_ IC3 SG_ 1234 Trailer2TPMTireInfo_RefPres_ISig 1200;
BA_REL_ "GenSigFirstTimeoutTime" BU_SG_REL_ IC3 SG_ 1234 Trailer2TPMTireInfo_PresWarn_ISi 4800;
BA_REL_ "GenSigTimeoutTime" BU_SG_REL_ IC3 SG_ 1234 Trailer2TPMTireInfo_PresWarn_ISi 1200;
BA_REL_ "GenSigFirstTimeoutTime" BU_SG_REL_ IC3 SG_ 1234 Trailer2TPMTireInfo_Pressure_ISi 4800;
BA_REL_ "GenSigTimeoutTime" BU_SG_REL_ IC3 SG_ 1234 Trailer2TPMTireInfo_Pressure_ISi 1200;
BA_REL_ "GenSigFirstTimeoutTime" BU_SG_REL_ IC3 SG_ 1234 Trailer2TPMTireInfo_Temperature_ 4800;
BA_REL_ "GenSigTimeoutTime" BU_SG_REL_ IC3 SG_ 1234 Trailer2TPMTireInfo_Temperature_ 1200;
BA_REL_ "GenSigFirstTimeoutTime" BU_SG_REL_ IC3 SG_ 1234 Trailer2TPMTireInfo_TireId_ISig_ 4800;
BA_REL_ "GenSigTimeoutTime" BU_SG_REL_ IC3 SG_ 1234 Trailer2TPMTireInfo_TireId_ISig_ 1200;
BA_REL_ "GenSigFirstTimeoutTime" BU_SG_REL_ IC3 SG_ 1234 Trailer2TPMTireInfo_Battery_ISig 4800;
BA_REL_ "GenSigTimeoutTime" BU_SG_REL_ IC3 SG_ 1234 Trailer2TPMTireInfo_Battery_ISig 1200;
BA_REL_ "GenSigFirstTimeoutTime" BU_SG_REL_ IC3 SG_ 1234 Trailer2TPMTireInfo_Active_ISig_ 4800;
BA_REL_ "GenSigTimeoutTime" BU_SG_REL_ IC3 SG_ 1234 Trailer2TPMTireInfo_Active_ISig_ 1200;
BA_REL_ "GenSigFirstTimeoutTime" BU_SG_REL_ IC3 SG_ 1231 Trailer1TPMTireInfo_Battery_ISig 4800;
BA_REL_ "GenSigTimeoutTime" BU_SG_REL_ IC3 SG_ 1231 Trailer1TPMTireInfo_Battery_ISig 1200;
BA_REL_ "GenSigFirstTimeoutTime" BU_SG_REL_ IC3 SG_ 1231 Trailer1TPMTireInfo_Pressure_ISi 4800;
BA_REL_ "GenSigTimeoutTime" BU_SG_REL_ IC3 SG_ 1231 Trailer1TPMTireInfo_Pressure_ISi 1200;
BA_REL_ "GenSigFirstTimeoutTime" BU_SG_REL_ IC3 SG_ 1231 Trailer1TPMTireInfo_PresWarn_ISi 4800;
BA_REL_ "GenSigTimeoutTime" BU_SG_REL_ IC3 SG_ 1231 Trailer1TPMTireInfo_PresWarn_ISi 1200;
BA_REL_ "GenSigFirstTimeoutTime" BU_SG_REL_ IC3 SG_ 1231 Trailer1TPMTireInfo_LeakageWarn_ 4800;
BA_REL_ "GenSigTimeoutTime" BU_SG_REL_ IC3 SG_ 1231 Trailer1TPMTireInfo_LeakageWarn_ 1200;
BA_REL_ "GenSigFirstTimeoutTime" BU_SG_REL_ IC3 SG_ 1231 TPMPosOfWMResp_VehiclePos_ISig_4 4800;
BA_REL_ "GenSigTimeoutTime" BU_SG_REL_ IC3 SG_ 1231 TPMPosOfWMResp_VehiclePos_ISig_4 1200;
BA_REL_ "GenSigFirstTimeoutTime" BU_SG_REL_ IC3 SG_ 1231 Trailer1TPMTireInfo_TireId_ISig_ 4800;
BA_REL_ "GenSigTimeoutTime" BU_SG_REL_ IC3 SG_ 1231 Trailer1TPMTireInfo_TireId_ISig_ 1200;
BA_REL_ "GenSigFirstTimeoutTime" BU_SG_REL_ IC3 SG_ 1231 Trailer1TPMTireInfo_RefPres_ISig 4800;
BA_REL_ "GenSigTimeoutTime" BU_SG_REL_ IC3 SG_ 1231 Trailer1TPMTireInfo_RefPres_ISig 1200;
BA_REL_ "GenSigFirstTimeoutTime" BU_SG_REL_ IC3 SG_ 1231 Trailer1TPMTireInfo_Temperature_ 4800;
BA_REL_ "GenSigTimeoutTime" BU_SG_REL_ IC3 SG_ 1231 Trailer1TPMTireInfo_Temperature_ 1200;
BA_REL_ "GenSigFirstTimeoutTime" BU_SG_REL_ IC3 SG_ 1231 Trailer1TPMTireInfo_Active_ISig_ 4800;
BA_REL_ "GenSigTimeoutTime" BU_SG_REL_ IC3 SG_ 1231 Trailer1TPMTireInfo_Active_ISig_ 1200;
BA_REL_ "GenSigFirstTimeoutTime" BU_SG_REL_ IC3 SG_ 1231 TPMPosOfWMResp_Status_ISig_4 4800;
BA_REL_ "GenSigTimeoutTime" BU_SG_REL_ IC3 SG_ 1231 TPMPosOfWMResp_Status_ISig_4 1200;
BA_REL_ "GenSigFirstTimeoutTime" BU_SG_REL_ IC3 SG_ 1231 TPMPosOfWMResp_TireId_ISig_4 4800;
BA_REL_ "GenSigTimeoutTime" BU_SG_REL_ IC3 SG_ 1231 TPMPosOfWMResp_TireId_ISig_4 1200;
BA_REL_ "GenSigFirstTimeoutTime" BU_SG_REL_ IC3 SG_ 1403 TruckTPMThresCfg_OverPres_ISig_4 24000;
BA_REL_ "GenSigTimeoutTime" BU_SG_REL_ IC3 SG_ 1403 TruckTPMThresCfg_OverPres_ISig_4 6000;
BA_REL_ "GenSigFirstTimeoutTime" BU_SG_REL_ IC3 SG_ 1403 TruckTPMAxlTireCfg_Axle2_ISig_4 24000;
BA_REL_ "GenSigTimeoutTime" BU_SG_REL_ IC3 SG_ 1403 TruckTPMAxlTireCfg_Axle2_ISig_4 6000;
BA_REL_ "GenSigFirstTimeoutTime" BU_SG_REL_ IC3 SG_ 1403 TruckTPMAxlTireCfg_Axle1_ISig_4 24000;
BA_REL_ "GenSigTimeoutTime" BU_SG_REL_ IC3 SG_ 1403 TruckTPMAxlTireCfg_Axle1_ISig_4 6000;
BA_REL_ "GenSigFirstTimeoutTime" BU_SG_REL_ IC3 SG_ 1403 TruckTPMAxlTireCfg_Axle5_ISig_4 24000;
BA_REL_ "GenSigTimeoutTime" BU_SG_REL_ IC3 SG_ 1403 TruckTPMAxlTireCfg_Axle5_ISig_4 6000;
BA_REL_ "GenSigFirstTimeoutTime" BU_SG_REL_ IC3 SG_ 1403 TruckTPMAxlTireCfg_Axle4_ISig_4 24000;
BA_REL_ "GenSigTimeoutTime" BU_SG_REL_ IC3 SG_ 1403 TruckTPMAxlTireCfg_Axle4_ISig_4 6000;
BA_REL_ "GenSigFirstTimeoutTime" BU_SG_REL_ IC3 SG_ 1403 TruckTPMThresCfg_ExtUnderPres_IS 24000;
BA_REL_ "GenSigTimeoutTime" BU_SG_REL_ IC3 SG_ 1403 TruckTPMThresCfg_ExtUnderPres_IS 6000;
BA_REL_ "GenSigFirstTimeoutTime" BU_SG_REL_ IC3 SG_ 1403 TruckTPMThresCfg_AxleNr_ISig_4 24000;
BA_REL_ "GenSigTimeoutTime" BU_SG_REL_ IC3 SG_ 1403 TruckTPMThresCfg_AxleNr_ISig_4 6000;
BA_REL_ "GenSigFirstTimeoutTime" BU_SG_REL_ IC3 SG_ 1403 TruckTPMThresCfg_UnderPres_ISig_ 24000;
BA_REL_ "GenSigTimeoutTime" BU_SG_REL_ IC3 SG_ 1403 TruckTPMThresCfg_UnderPres_ISig_ 6000;
BA_REL_ "GenSigFirstTimeoutTime" BU_SG_REL_ IC3 SG_ 1403 TruckTPMThresCfg_ExtOverPres_ISi 24000;
BA_REL_ "GenSigTimeoutTime" BU_SG_REL_ IC3 SG_ 1403 TruckTPMThresCfg_ExtOverPres_ISi 6000;
BA_REL_ "GenSigFirstTimeoutTime" BU_SG_REL_ IC3 SG_ 1403 TruckTPMAxlTireCfg_Axle3_ISig_4 24000;
BA_REL_ "GenSigTimeoutTime" BU_SG_REL_ IC3 SG_ 1403 TruckTPMAxlTireCfg_Axle3_ISig_4 6000;
BA_REL_ "GenSigFirstTimeoutTime" BU_SG_REL_ IC3 SG_ 1402 Trailer2TPMType_ISig_4 24000;
BA_REL_ "GenSigTimeoutTime" BU_SG_REL_ IC3 SG_ 1402 Trailer2TPMType_ISig_4 6000;
BA_REL_ "GenSigFirstTimeoutTime" BU_SG_REL_ IC3 SG_ 1402 Trailer2TPMAxlTireCfg_Axle1_ISig 24000;
BA_REL_ "GenSigTimeoutTime" BU_SG_REL_ IC3 SG_ 1402 Trailer2TPMAxlTireCfg_Axle1_ISig 6000;
BA_REL_ "GenSigFirstTimeoutTime" BU_SG_REL_ IC3 SG_ 1402 Trailer2TPMThresCfg_OverPres_ISi 24000;
BA_REL_ "GenSigTimeoutTime" BU_SG_REL_ IC3 SG_ 1402 Trailer2TPMThresCfg_OverPres_ISi 6000;
BA_REL_ "GenSigFirstTimeoutTime" BU_SG_REL_ IC3 SG_ 1402 Trailer2TPMAxlTireCfg_Axle3_ISig 24000;
BA_REL_ "GenSigTimeoutTime" BU_SG_REL_ IC3 SG_ 1402 Trailer2TPMAxlTireCfg_Axle3_ISig 6000;
BA_REL_ "GenSigFirstTimeoutTime" BU_SG_REL_ IC3 SG_ 1402 Trailer2TPMAxlTireCfg_Axle2_ISig 24000;
BA_REL_ "GenSigTimeoutTime" BU_SG_REL_ IC3 SG_ 1402 Trailer2TPMAxlTireCfg_Axle2_ISig 6000;
BA_REL_ "GenSigFirstTimeoutTime" BU_SG_REL_ IC3 SG_ 1402 Trailer2TPMAxlTireCfg_Axle5_ISig 24000;
BA_REL_ "GenSigTimeoutTime" BU_SG_REL_ IC3 SG_ 1402 Trailer2TPMAxlTireCfg_Axle5_ISig 6000;
BA_REL_ "GenSigFirstTimeoutTime" BU_SG_REL_ IC3 SG_ 1402 Trailer2TPMAxlTireCfg_Axle4_ISig 24000;
BA_REL_ "GenSigTimeoutTime" BU_SG_REL_ IC3 SG_ 1402 Trailer2TPMAxlTireCfg_Axle4_ISig 6000;
BA_REL_ "GenSigFirstTimeoutTime" BU_SG_REL_ IC3 SG_ 1402 Trailer2TPMThresCfg_AxleNr_ISig_ 24000;
BA_REL_ "GenSigTimeoutTime" BU_SG_REL_ IC3 SG_ 1402 Trailer2TPMThresCfg_AxleNr_ISig_ 6000;
BA_REL_ "GenSigFirstTimeoutTime" BU_SG_REL_ IC3 SG_ 1402 Trailer2TPMThresCfg_ExtOverPres_ 24000;
BA_REL_ "GenSigTimeoutTime" BU_SG_REL_ IC3 SG_ 1402 Trailer2TPMThresCfg_ExtOverPres_ 6000;
BA_REL_ "GenSigFirstTimeoutTime" BU_SG_REL_ IC3 SG_ 1402 Trailer2TPMThresCfg_UnderPres_IS 24000;
BA_REL_ "GenSigTimeoutTime" BU_SG_REL_ IC3 SG_ 1402 Trailer2TPMThresCfg_UnderPres_IS 6000;
BA_REL_ "GenSigFirstTimeoutTime" BU_SG_REL_ IC3 SG_ 1402 Trailer2TPMThresCfg_ExtUnderPres 24000;
BA_REL_ "GenSigTimeoutTime" BU_SG_REL_ IC3 SG_ 1402 Trailer2TPMThresCfg_ExtUnderPres 6000;
BA_REL_ "GenSigFirstTimeoutTime" BU_SG_REL_ IC3 SG_ 1401 Trailer1TPMAxlTireCfg_Axle1_ISig 24000;
BA_REL_ "GenSigTimeoutTime" BU_SG_REL_ IC3 SG_ 1401 Trailer1TPMAxlTireCfg_Axle1_ISig 6000;
BA_REL_ "GenSigFirstTimeoutTime" BU_SG_REL_ IC3 SG_ 1401 Trailer1TPMThresCfg_ExtOverPres_ 24000;
BA_REL_ "GenSigTimeoutTime" BU_SG_REL_ IC3 SG_ 1401 Trailer1TPMThresCfg_ExtOverPres_ 6000;
BA_REL_ "GenSigFirstTimeoutTime" BU_SG_REL_ IC3 SG_ 1401 Trailer1TPMAxlTireCfg_Axle2_ISig 24000;
BA_REL_ "GenSigTimeoutTime" BU_SG_REL_ IC3 SG_ 1401 Trailer1TPMAxlTireCfg_Axle2_ISig 6000;
BA_REL_ "GenSigFirstTimeoutTime" BU_SG_REL_ IC3 SG_ 1401 Trailer1TPMThresCfg_OverPres_ISi 24000;
BA_REL_ "GenSigTimeoutTime" BU_SG_REL_ IC3 SG_ 1401 Trailer1TPMThresCfg_OverPres_ISi 6000;
BA_REL_ "GenSigFirstTimeoutTime" BU_SG_REL_ IC3 SG_ 1401 Trailer1TPMAxlTireCfg_Axle5_ISig 24000;
BA_REL_ "GenSigTimeoutTime" BU_SG_REL_ IC3 SG_ 1401 Trailer1TPMAxlTireCfg_Axle5_ISig 6000;
BA_REL_ "GenSigFirstTimeoutTime" BU_SG_REL_ IC3 SG_ 1401 Trailer1TPMType_ISig_4 24000;
BA_REL_ "GenSigTimeoutTime" BU_SG_REL_ IC3 SG_ 1401 Trailer1TPMType_ISig_4 6000;
BA_REL_ "GenSigFirstTimeoutTime" BU_SG_REL_ IC3 SG_ 1401 Trailer1TPMThresCfg_UnderPres_IS 24000;
BA_REL_ "GenSigTimeoutTime" BU_SG_REL_ IC3 SG_ 1401 Trailer1TPMThresCfg_UnderPres_IS 6000;
BA_REL_ "GenSigFirstTimeoutTime" BU_SG_REL_ IC3 SG_ 1401 Trailer1TPMThresCfg_ExtUnderPres 24000;
BA_REL_ "GenSigTimeoutTime" BU_SG_REL_ IC3 SG_ 1401 Trailer1TPMThresCfg_ExtUnderPres 6000;
BA_REL_ "GenSigFirstTimeoutTime" BU_SG_REL_ IC3 SG_ 1401 Trailer1TPMThresCfg_AxleNr_ISig_ 24000;
BA_REL_ "GenSigTimeoutTime" BU_SG_REL_ IC3 SG_ 1401 Trailer1TPMThresCfg_AxleNr_ISig_ 6000;
BA_REL_ "GenSigFirstTimeoutTime" BU_SG_REL_ IC3 SG_ 1401 Trailer1TPMAxlTireCfg_Axle4_ISig 24000;
BA_REL_ "GenSigTimeoutTime" BU_SG_REL_ IC3 SG_ 1401 Trailer1TPMAxlTireCfg_Axle4_ISig 6000;
BA_REL_ "GenSigFirstTimeoutTime" BU_SG_REL_ IC3 SG_ 1401 Trailer1TPMAxlTireCfg_Axle3_ISig 24000;
BA_REL_ "GenSigTimeoutTime" BU_SG_REL_ IC3 SG_ 1401 Trailer1TPMAxlTireCfg_Axle3_ISig 6000;
BA_REL_ "GenSigFirstTimeoutTime" BU_SG_REL_ IC3 SG_ 1436 DistToEmptyLNG 24000;
BA_REL_ "GenSigTimeoutTime" BU_SG_REL_ IC3 SG_ 1436 DistToEmptyLNG 6000;
BA_REL_ "GenSigFirstTimeoutTime" BU_SG_REL_ IC3 SG_ 1436 DistToEmptyDiesel 24000;
BA_REL_ "GenSigTimeoutTime" BU_SG_REL_ IC3 SG_ 1436 DistToEmptyDiesel 6000;
BA_REL_ "GenSigFirstTimeoutTime" BU_SG_REL_ IC3 SG_ 1436 CoastingUseDistance_ISig_4 24000;
BA_REL_ "GenSigTimeoutTime" BU_SG_REL_ IC3 SG_ 1436 CoastingUseDistance_ISig_4 6000;
VAL_ 1380 Trail3Type_TrailType_ISig_4 7 "TrailerType2_NotAvailable" 6 "TrailerType2_Spare" 5 "TrailerType2_NotConnected" 4 "TrailerType2_LinkTrailer" 3 "TrailerType2_Dolly" 2 "TrailerType2_DrawbarTrailer" 1 "TrailerType2_CentreAxleTrailer" 0 "TrailerType2_SemiTrailer" ;
VAL_ 1380 Trail3Type_Towing_ISig_4 1 "Towing_TowingPossible" 0 "Towing_NoTowingOrOldTrailer" ;
VAL_ 1380 Trail4Type_Towing_ISig_4 1 "Towing_TowingPossible" 0 "Towing_NoTowingOrOldTrailer" ;
VAL_ 1380 Trail4Type_TrailType_ISig_4 7 "TrailerType2_NotAvailable" 6 "TrailerType2_Spare" 5 "TrailerType2_NotConnected" 4 "TrailerType2_LinkTrailer" 3 "TrailerType2_Dolly" 2 "TrailerType2_DrawbarTrailer" 1 "TrailerType2_CentreAxleTrailer" 0 "TrailerType2_SemiTrailer" ;
VAL_ 1380 Trail5Type_TrailType_ISig_4 7 "TrailerType2_NotAvailable" 6 "TrailerType2_Spare" 5 "TrailerType2_NotConnected" 4 "TrailerType2_LinkTrailer" 3 "TrailerType2_Dolly" 2 "TrailerType2_DrawbarTrailer" 1 "TrailerType2_CentreAxleTrailer" 0 "TrailerType2_SemiTrailer" ;
VAL_ 1380 Trail5Type_Towing_ISig_4 1 "Towing_TowingPossible" 0 "Towing_NoTowingOrOldTrailer" ;
VAL_ 1378 Trail1Type_Towing_ISig_4 1 "Towing_TowingPossible" 0 "Towing_NoTowingOrOldTrailer" ;
VAL_ 1378 Trail1Type_TrailType_ISig_4 7 "TrailerType2_NotAvailable" 6 "TrailerType2_Spare" 5 "TrailerType2_NotConnected" 4 "TrailerType2_LinkTrailer" 3 "TrailerType2_Dolly" 2 "TrailerType2_DrawbarTrailer" 1 "TrailerType2_CentreAxleTrailer" 0 "TrailerType2_SemiTrailer" ;
VAL_ 1378 Trail2Type_Towing_ISig_4 1 "Towing_TowingPossible" 0 "Towing_NoTowingOrOldTrailer" ;
VAL_ 1378 Trail2Type_TrailType_ISig_4 7 "TrailerType2_NotAvailable" 6 "TrailerType2_Spare" 5 "TrailerType2_NotConnected" 4 "TrailerType2_LinkTrailer" 3 "TrailerType2_Dolly" 2 "TrailerType2_DrawbarTrailer" 1 "TrailerType2_CentreAxleTrailer" 0 "TrailerType2_SemiTrailer" ;
VAL_ 310 MainBeamLEDStatusLeft_ISig_4 7 "LampCheck_stat_NotAvailable" 6 "LampCheck_stat_Error" 5 "LampCheck_stat_Spare_02" 4 "LampCheck_stat_Spare_01" 3 "LampCheck_stat_Spare" 2 "LampCheck_stat_TestedLampNOK" 1 "LampCheck_stat_TestedLampOK" 0 "LampCheck_stat_NotTested" ;
VAL_ 310 MainBeamLEDStatusRight_ISig_4 7 "LampCheck_stat_NotAvailable" 6 "LampCheck_stat_Error" 5 "LampCheck_stat_Spare_02" 4 "LampCheck_stat_Spare_01" 3 "LampCheck_stat_Spare" 2 "LampCheck_stat_TestedLampNOK" 1 "LampCheck_stat_TestedLampOK" 0 "LampCheck_stat_NotTested" ;
VAL_ 1370 Trailer1CalibrationType 7 "TrailerCalibrationType_NotAvailable" 6 "TrailerCalibrationType_Error" 5 "TrailerCalibrationType_Spare4" 4 "TrailerCalibrationType_Spare3" 3 "TrailerCalibrationType_Spare2" 2 "TrailerCalibrationType_Spare1" 1 "TrailerCalibrationType_VehicleOnly" 0 "TrailerCalibrationType_SingleAxleAllowed" ;
VAL_ 1370 FrontConspicLamp_stat_HiLeft_ISi 7 "LampCheck_stat_NotAvailable" 6 "LampCheck_stat_Error" 5 "LampCheck_stat_Spare_02" 4 "LampCheck_stat_Spare_01" 3 "LampCheck_stat_Spare" 2 "LampCheck_stat_TestedLampNOK" 1 "LampCheck_stat_TestedLampOK" 0 "LampCheck_stat_NotTested" ;
VAL_ 1370 TrailerDirIndLeftOutputStat_ISig 7 "TrailerLightOutputStat_NotAvailable" 6 "TrailerLightOutputStat_Error" 5 "TrailerLightOutputStat_OutputActiveStatusUncertain" 4 "TrailerLightOutputStat_OutputActiveLightDetectedOnActivation" 3 "TrailerLightOutputStat_OutputActiveLightDetected" 2 "TrailerLightOutputStat_OutputActiveNoLightDetected" 1 "TrailerLightOutputStat_OutputActiveDetectionOngoing" 0 "TrailerLightOutputStat_OutputInactive" ;
VAL_ 1370 JumpChargeInterface_stat_ISig_4 3 "Connection_Status_NotAvailable" 2 "Connection_Status_Error" 1 "Connection_Status_Connected" 0 "Connection_Status_NotConnected" ;
VAL_ 1370 TrailerPosLightLeftOutputStat_IS 7 "TrailerLightOutputStat_NotAvailable" 6 "TrailerLightOutputStat_Error" 5 "TrailerLightOutputStat_OutputActiveStatusUncertain" 4 "TrailerLightOutputStat_OutputActiveLightDetectedOnActivation" 3 "TrailerLightOutputStat_OutputActiveLightDetected" 2 "TrailerLightOutputStat_OutputActiveNoLightDetected" 1 "TrailerLightOutputStat_OutputActiveDetectionOngoing" 0 "TrailerLightOutputStat_OutputInactive" ;
VAL_ 1370 TruckCalibrated 7 "CalibratedStatus_NotAvailable" 6 "CalibratedStatus_Error" 5 "CalibratedStatus_Spare3" 4 "CalibratedStatus_Spare2" 3 "CalibratedStatus_Spare1" 2 "CalibratedStatus_FullyCalibrated" 1 "CalibratedStatus_PartiallyCalibrated" 0 "CalibratedStatus_Uncalibrated" ;
VAL_ 1370 Trailer5CalibrationType 7 "TrailerCalibrationType_NotAvailable" 6 "TrailerCalibrationType_Error" 5 "TrailerCalibrationType_Spare4" 4 "TrailerCalibrationType_Spare3" 3 "TrailerCalibrationType_Spare2" 2 "TrailerCalibrationType_Spare1" 1 "TrailerCalibrationType_VehicleOnly" 0 "TrailerCalibrationType_SingleAxleAllowed" ;
VAL_ 1370 Trailer2CalibrationType 7 "TrailerCalibrationType_NotAvailable" 6 "TrailerCalibrationType_Error" 5 "TrailerCalibrationType_Spare4" 4 "TrailerCalibrationType_Spare3" 3 "TrailerCalibrationType_Spare2" 2 "TrailerCalibrationType_Spare1" 1 "TrailerCalibrationType_VehicleOnly" 0 "TrailerCalibrationType_SingleAxleAllowed" ;
VAL_ 1370 Trailer4CalibrationType 7 "TrailerCalibrationType_NotAvailable" 6 "TrailerCalibrationType_Error" 5 "TrailerCalibrationType_Spare4" 4 "TrailerCalibrationType_Spare3" 3 "TrailerCalibrationType_Spare2" 2 "TrailerCalibrationType_Spare1" 1 "TrailerCalibrationType_VehicleOnly" 0 "TrailerCalibrationType_SingleAxleAllowed" ;
VAL_ 1370 TrailerBrakeLightOutputStat_ISig 7 "TrailerLightOutputStat_NotAvailable" 6 "TrailerLightOutputStat_Error" 5 "TrailerLightOutputStat_OutputActiveStatusUncertain" 4 "TrailerLightOutputStat_OutputActiveLightDetectedOnActivation" 3 "TrailerLightOutputStat_OutputActiveLightDetected" 2 "TrailerLightOutputStat_OutputActiveNoLightDetected" 1 "TrailerLightOutputStat_OutputActiveDetectionOngoing" 0 "TrailerLightOutputStat_OutputInactive" ;
VAL_ 1370 FrontConspicLamp_stat_LoRight_IS 7 "LampCheck_stat_NotAvailable" 6 "LampCheck_stat_Error" 5 "LampCheck_stat_Spare_02" 4 "LampCheck_stat_Spare_01" 3 "LampCheck_stat_Spare" 2 "LampCheck_stat_TestedLampNOK" 1 "LampCheck_stat_TestedLampOK" 0 "LampCheck_stat_NotTested" ;
VAL_ 1370 FrontConspicLamp_stat_LoLeft_ISi 7 "LampCheck_stat_NotAvailable" 6 "LampCheck_stat_Error" 5 "LampCheck_stat_Spare_02" 4 "LampCheck_stat_Spare_01" 3 "LampCheck_stat_Spare" 2 "LampCheck_stat_TestedLampNOK" 1 "LampCheck_stat_TestedLampOK" 0 "LampCheck_stat_NotTested" ;
VAL_ 1370 TrailerDirIndRightOutputStat_ISi 7 "TrailerLightOutputStat_NotAvailable" 6 "TrailerLightOutputStat_Error" 5 "TrailerLightOutputStat_OutputActiveStatusUncertain" 4 "TrailerLightOutputStat_OutputActiveLightDetectedOnActivation" 3 "TrailerLightOutputStat_OutputActiveLightDetected" 2 "TrailerLightOutputStat_OutputActiveNoLightDetected" 1 "TrailerLightOutputStat_OutputActiveDetectionOngoing" 0 "TrailerLightOutputStat_OutputInactive" ;
VAL_ 1370 TrailerPosLightRightOutputStat_I 7 "TrailerLightOutputStat_NotAvailable" 6 "TrailerLightOutputStat_Error" 5 "TrailerLightOutputStat_OutputActiveStatusUncertain" 4 "TrailerLightOutputStat_OutputActiveLightDetectedOnActivation" 3 "TrailerLightOutputStat_OutputActiveLightDetected" 2 "TrailerLightOutputStat_OutputActiveNoLightDetected" 1 "TrailerLightOutputStat_OutputActiveDetectionOngoing" 0 "TrailerLightOutputStat_OutputInactive" ;
VAL_ 1370 Trailer3CalibrationType 7 "TrailerCalibrationType_NotAvailable" 6 "TrailerCalibrationType_Error" 5 "TrailerCalibrationType_Spare4" 4 "TrailerCalibrationType_Spare3" 3 "TrailerCalibrationType_Spare2" 2 "TrailerCalibrationType_Spare1" 1 "TrailerCalibrationType_VehicleOnly" 0 "TrailerCalibrationType_SingleAxleAllowed" ;
VAL_ 1370 FrontConspicLamp_stat_HiRight_IS 7 "LampCheck_stat_NotAvailable" 6 "LampCheck_stat_Error" 5 "LampCheck_stat_Spare_02" 4 "LampCheck_stat_Spare_01" 3 "LampCheck_stat_Spare" 2 "LampCheck_stat_TestedLampNOK" 1 "LampCheck_stat_TestedLampOK" 0 "LampCheck_stat_NotTested" ;
VAL_ 546 FASSaturated_ISig_4 3 "FASSaturated_NotAvailable" 2 "FASSaturated_Error" 1 "FASSaturated_FAS_IsSaturated" 0 "FASSaturated_FAS_IsNotSaturated" ;
VAL_ 546 OverSteerGuidanceStatus_ISig_4 3 "InactiveActive_NotAvailable" 2 "InactiveActive_Error" 1 "InactiveActive_Active" 0 "InactiveActive_Inactive" ;
VAL_ 546 FASFullyOperational_ISig_4 3 "FASFullyOperational_NotAvailable" 2 "FASFullyOperational_Error" 1 "FASFullyOperational_FASFullyOperational" 0 "FASFullyOperational_FASNotFullyOperational" ;
VAL_ 546 FASFunctionInControl_ISig_4 3 "FASFunctionInControl_NotAvailable" 2 "FASFunctionInControl_Error" 1 "FASFunctionInControl_FunctionInControl" 0 "FASFunctionInControl_DriverInControl" ;
VAL_ 1405 ActualFasPersSettingsButton_ISig 7 "FasPersSettingsButton_NotAvailable" 6 "FasPersSettingsButton_Error" 5 "FasPersSettingsButton_Spare" 4 "FasPersSettingsButton_UserDefinedButton" 3 "FasPersSettingsButton_PresetButtonHeavy" 2 "FasPersSettingsButton_PresetButtonFirm" 1 "FasPersSettingsButton_PresetButtonLight" 0 "FasPersSettingsButton_PresetButtonDefault" ;
VAL_ 1405 FasDriver_ISig_4 15 "FasDriver_NotAvailable" 14 "FasDriver_Error" 13 "FasDriver_Spare3" 12 "FasDriver_Spare2" 11 "FasDriver_Spare1" 10 "FasDriver_Driver10" 9 "FasDriver_Driver9" 8 "FasDriver_Driver8" 7 "FasDriver_Driver7" 6 "FasDriver_Driver6" 5 "FasDriver_Driver5" 4 "FasDriver_Driver4" 3 "FasDriver_Driver3" 2 "FasDriver_Driver2" 1 "FasDriver_Driver1" 0 "FasDriver_DefaultDriver" ;
VAL_ 830 PS_PosLightDoorOpen 3 "InactiveActiveSpare_NotAvailable" 2 "InactiveActiveSpare_Spare" 1 "InactiveActiveSpare_Active" 0 "InactiveActiveSpare_Inactive" ;
VAL_ 830 PS_FogLightRear 3 "InactiveActiveSpare_NotAvailable" 2 "InactiveActiveSpare_Spare" 1 "InactiveActiveSpare_Active" 0 "InactiveActiveSpare_Inactive" ;
VAL_ 830 TrailerBodyLampDI_stat 3 "PushButtonStatus_NotAvailable" 2 "PushButtonStatus_Error" 1 "PushButtonStatus_Pushed" 0 "PushButtonStatus_Neutral" ;
VAL_ 830 TrailerBodyLampFdbk_stat 3 "OffOn_NotAvailable" 2 "OffOn_Error" 1 "OffOn_On" 0 "OffOn_Off" ;
VAL_ 830 PS_FogLightFront 3 "InactiveActiveSpare_NotAvailable" 2 "InactiveActiveSpare_Spare" 1 "InactiveActiveSpare_Active" 0 "InactiveActiveSpare_Inactive" ;
VAL_ 830 Alcolock_PBReleaseInhibit_ind 7 "PBReleaseInhibit_ind_NotAvailable" 6 "PBReleaseInhibit_ind_Error" 5 "PBReleaseInhibit_ind_Spare" 4 "PBReleaseInhibit_ind_AutoReleaseBeingInhibited" 3 "PBReleaseInhibit_ind_XPRReleaseCommandBeingInhibited" 2 "PBReleaseInhibit_ind_ManualReleaseCommandBeingInhibited" 1 "PBReleaseInhibit_ind_Active" 0 "PBReleaseInhibit_ind_NotActive" ;
VAL_ 830 DHCNotificationReq 15 "DHCNotificationReq_NotAvailable" 14 "DHCNotificationReq_Error" 13 "DHCNotificationReq_Spare8" 12 "DHCNotificationReq_Spare7" 11 "DHCNotificationReq_Spare6" 10 "DHCNotificationReq_Spare5" 9 "DHCNotificationReq_Spare4" 8 "DHCNotificationReq_Spare3" 7 "DHCNotificationReq_Spare2" 6 "DHCNotificationReq_ActivationFailedStretchBrake" 5 "DHCNotificationReq_ActivationFailedBrakePedalCheck" 4 "DHCNotificationReq_DeactivationWarning" 3 "DHCNotificationReq_ActivationstopFailedError" 2 "DHCNotificationReq_ActivationstopBraking" 1 "DHCNotificationReq_ActivationFailedLowSpeed" 0 "DHCNotificationReq_NoRequest" ;
VAL_ 830 DriverCrank_rqst 3 "Request_NotAvailable" 2 "Request_Error" 1 "Request_RequestActive" 0 "Request_NotRequested" ;
VAL_ 830 PS_HeadLightAdjustment 3 "InactiveActiveSpare_NotAvailable" 2 "InactiveActiveSpare_Spare" 1 "InactiveActiveSpare_Active" 0 "InactiveActiveSpare_Inactive" ;
VAL_ 830 PS_MainBeam 3 "PSOffOn_NotAvailable" 2 "PSOffOn_Spare" 1 "PSOffOn_On" 0 "PSOffOn_Off" ;
VAL_ 830 InstFuel_VehicleMoving 3 "VehicleMoving_NotAvailable" 2 "VehicleMoving_Error" 1 "VehicleMoving_VehicleMoving" 0 "VehicleMoving_VehicleStopped" ;
VAL_ 830 PS_AFSAllowed_ISig_4 3 "InactiveActiveSpare_NotAvailable" 2 "InactiveActiveSpare_Spare" 1 "InactiveActiveSpare_Active" 0 "InactiveActiveSpare_Inactive" ;
VAL_ 830 PS_AFS 7 "PS_AFS_NotAvailable" 6 "PS_AFS_Spare3" 5 "PS_AFS_Spare2" 4 "PS_AFS_Spare1" 3 "PS_AFS_AFS_ActiveGlareFreeAllowed" 2 "PS_AFS_AFS_ActiveMainBeamAllowed" 1 "PS_AFS_AFS_ActiveMainBeamNotAllowed" 0 "PS_AFS_AFS_NotActive" ;
VAL_ 830 AC2CoolingFanControl_rqst 3 "Request_NotAvailable" 2 "Request_Error" 1 "Request_RequestActive" 0 "Request_NotRequested" ;
VAL_ 830 DHCStatus 3 "InactiveActive_NotAvailable" 2 "InactiveActive_Error" 1 "InactiveActive_Active" 0 "InactiveActive_Inactive" ;
VAL_ 830 PS_PositionLight 3 "OffOnSpare_NotAvailable" 2 "OffOnSpare_Spare" 1 "OffOnSpare_On" 0 "OffOnSpare_Off" ;
VAL_ 1071 Alcolock_stat_ISig_4 3 "Alcolock_stat_NotAvailable" 2 "Alcolock_stat_Error" 1 "Alcolock_stat_MovementAuthorized" 0 "Alcolock_stat_MovementForbidden" ;
VAL_ 1071 CTA_PBReleaseInhibit_ind 7 "PBReleaseInhibit_ind_NotAvailable" 6 "PBReleaseInhibit_ind_Error" 5 "PBReleaseInhibit_ind_Spare" 4 "PBReleaseInhibit_ind_AutoReleaseBeingInhibited" 3 "PBReleaseInhibit_ind_XPRReleaseCommandBeingInhibited" 2 "PBReleaseInhibit_ind_ManualReleaseCommandBeingInhibited" 1 "PBReleaseInhibit_ind_Active" 0 "PBReleaseInhibit_ind_NotActive" ;
VAL_ 1071 EngOvrrideCtrlStat_FireTruckMode 3 "FireTruckMode_Spare4" 2 "FireTruckMode_Spare3" 1 "FireTruckMode_Spare2" 0 "FireTruckMode_Spare1" ;
VAL_ 1071 EngOvrrideCtrlStat_StartOvrrMode 3 "InactiveActive_NotAvailable" 2 "InactiveActive_Error" 1 "InactiveActive_Active" 0 "InactiveActive_Inactive" ;
VAL_ 1071 EngOvrrideCtrlStat_ProtOvrrMode 3 "InactiveActive_NotAvailable" 2 "InactiveActive_Error" 1 "InactiveActive_Active" 0 "InactiveActive_Inactive" ;
VAL_ 1035 BatteryTempAlert_rqst_ISig_4 7 "BatteryTempAlert_rqst_NotAvailable" 6 "BatteryTempAlert_rqst_Error" 5 "BatteryTempAlert_rqst_Spare3" 4 "BatteryTempAlert_rqst_Spare2" 3 "BatteryTempAlert_rqst_Spare1" 2 "BatteryTempAlert_rqst_CriticalAlertLowTemp" 1 "BatteryTempAlert_rqst_PreAlertLowTemp" 0 "BatteryTempAlert_rqst_NoAlertRequested" ;
VAL_ 1035 APM_TrailerCircPressureStatus_IS 3 "TrailerCircuitPressureStatus_NotAvailable" 2 "TrailerCircuitPressureStatus_Error" 1 "TrailerCircuitPressureStatus_EnabledLowPressureAlert" 0 "TrailerCircuitPressureStatus_DisabledLowPressureAlert" ;
VAL_ 1035 BatteryCapacity_ISig_4 15 "BatteryType_NotAvailable" 14 "BatteryType_Error" 13 "BatteryType_NoSelectionMade" 12 "BatteryType_OtherBatteryType" 11 "BatteryType_BatteryType11" 10 "BatteryType_BatteryType10" 9 "BatteryType_BatteryType9" 8 "BatteryType_BatteryType8" 7 "BatteryType_BatteryType7" 6 "BatteryType_BatteryType6" 5 "BatteryType_BatteryType5" 4 "BatteryType_BatteryType4" 3 "BatteryType_BatteryType3" 2 "BatteryType_BatteryType2" 1 "BatteryType_BatteryType1" 0 "BatteryType_BatteryType0" ;
VAL_ 1035 Hazard_rqst_ISig_4 3 "InactiveActive_NotAvailable" 2 "InactiveActive_Error" 1 "InactiveActive_Active" 0 "InactiveActive_Inactive" ;
VAL_ 1035 Trailer1TPMLostCom_ISig_4 3 "NoYes_NotAvailable" 2 "NoYes_Error" 1 "NoYes_Yes" 0 "NoYes_No" ;
VAL_ 1035 BatteryTempAlertRawData_rqst_ISi 7 "BatteryTempAlert_rqst_NotAvailable" 6 "BatteryTempAlert_rqst_Error" 5 "BatteryTempAlert_rqst_Spare3" 4 "BatteryTempAlert_rqst_Spare2" 3 "BatteryTempAlert_rqst_Spare1" 2 "BatteryTempAlert_rqst_CriticalAlertLowTemp" 1 "BatteryTempAlert_rqst_PreAlertLowTemp" 0 "BatteryTempAlert_rqst_NoAlertRequested" ;
VAL_ 1035 FPBRMMIStat_FPBRChangeAck_ISig_4 3 "Ack2Bit_NotAvailable" 2 "Ack2Bit_Error" 1 "Ack2Bit_ChangeAcknowledged" 0 "Ack2Bit_NoAction" ;
VAL_ 1035 LivBatteryCharging_stat_ISig_4 3 "NotConfirmedConfirmed_NotAvailable" 2 "NotConfirmedConfirmed_Error" 1 "NotConfirmedConfirmed_Confirmed" 0 "NotConfirmedConfirmed_NotConfirmed" ;
VAL_ 1035 FPBRMMIStat_FPBRStatusInd_ISig_4 3 "FPBRStatusInd_NotAvailable" 2 "FPBRStatusInd_Changing" 1 "FPBRStatusInd_On" 0 "FPBRStatusInd_Off" ;
VAL_ 1035 RS_WasherStatus_ISig_4 3 "InactiveActive_NotAvailable" 2 "InactiveActive_Error" 1 "InactiveActive_Active" 0 "InactiveActive_Inactive" ;
VAL_ 1035 Trailer2TPMLostCom_ISig_4 3 "NoYes_NotAvailable" 2 "NoYes_Error" 1 "NoYes_Yes" 0 "NoYes_No" ;
VAL_ 1035 Rainsensor_Indication_ISig_4 3 "DeviceIndication_SpareValue" 2 "DeviceIndication_Blink" 1 "DeviceIndication_On" 0 "DeviceIndication_Off" ;
VAL_ 1032 TPMMateTrailerResp_ISig_4 7 "TPMMateTrailerResp_NotAvailable" 6 "TPMMateTrailerResp_Error" 5 "TPMMateTrailerResp_Spare2" 4 "TPMMateTrailerResp_Spare1" 3 "TPMMateTrailerResp_MatedOK" 2 "TPMMateTrailerResp_Timeout" 1 "TPMMateTrailerResp_Progressing" 0 "TPMMateTrailerResp_NotActive" ;
VAL_ 1032 Trailer2TPMLeakageWarning_ISig_4 7 "TPMTireLeakageWarn_NotAvailable" 6 "TPMTireLeakageWarn_Error" 5 "TPMTireLeakageWarn_Spare3" 4 "TPMTireLeakageWarn_Spare2" 3 "TPMTireLeakageWarn_Spare1" 2 "TPMTireLeakageWarn_FastLeakageDetected" 1 "TPMTireLeakageWarn_SlowLeakageDetected" 0 "TPMTireLeakageWarn_NoLeakageDetected" ;
VAL_ 1032 TPMAutomaticMating_ISig_4 3 "ActiveStatus_NotAvailable" 2 "ActiveStatus_Error" 1 "ActiveStatus_Active" 0 "ActiveStatus_NotActive" ;
VAL_ 1032 DirectionIndicatorLightsStatus_I 15 "DirectionIndicatorLightsStatus_NotAvailable" 14 "DirectionIndicatorLightsStatus_Error" 13 "DirectionIndicatorLightsStatus_Spare7" 12 "DirectionIndicatorLightsStatus_Spare6" 11 "DirectionIndicatorLightsStatus_Spare5" 10 "DirectionIndicatorLightsStatus_Spare4" 9 "DirectionIndicatorLightsStatus_Spare3" 8 "DirectionIndicatorLightsStatus_Spare2" 7 "DirectionIndicatorLightsStatus_Spare1" 6 "DirectionIndicatorLightsStatus_ActiveOtherIndication" 5 "DirectionIndicatorLightsStatus_ActiveHazard" 4 "DirectionIndicatorLightsStatus_ActiveRightAndHazard" 3 "DirectionIndicatorLightsStatus_ActiveLeftAndHazard" 2 "DirectionIndicatorLightsStatus_ActiveRight" 1 "DirectionIndicatorLightsStatus_ActiveLeft" 0 "DirectionIndicatorLightsStatus_NotActive" ;
VAL_ 1032 FrontWheelDifflockRequest_ISig_4 3 "DisengageEngage_NotAvailable" 2 "DisengageEngage_Error" 1 "DisengageEngage_Engage" 0 "DisengageEngage_Disengage" ;
VAL_ 1032 Trailer2TPMMatedStatus_ISig_4 3 "NoMatedMated_NotAvailable" 2 "NoMatedMated_Error" 1 "NoMatedMated_Mated" 0 "NoMatedMated_NoMated" ;
VAL_ 1032 Trailer1TPMMatedStatus_ISig_4 3 "NoMatedMated_NotAvailable" 2 "NoMatedMated_Error" 1 "NoMatedMated_Mated" 0 "NoMatedMated_NoMated" ;
VAL_ 1032 CargoLoadResetFeedback 3 "ResetFeedback_NotAvailable" 2 "ResetFeedback_NOK" 1 "ResetFeedback_OK" 0 "ResetFeedback_NotRequested" ;
VAL_ 1032 TruckTPMLeakageWarning_ISig_4 7 "TPMTireLeakageWarn_NotAvailable" 6 "TPMTireLeakageWarn_Error" 5 "TPMTireLeakageWarn_Spare3" 4 "TPMTireLeakageWarn_Spare2" 3 "TPMTireLeakageWarn_Spare1" 2 "TPMTireLeakageWarn_FastLeakageDetected" 1 "TPMTireLeakageWarn_SlowLeakageDetected" 0 "TPMTireLeakageWarn_NoLeakageDetected" ;
VAL_ 1032 ExtraSideMarkers_FunctStat 3 "InactiveActive_NotAvailable" 2 "InactiveActive_Error" 1 "InactiveActive_Active" 0 "InactiveActive_Inactive" ;
VAL_ 1032 Trailer2TPMPressureWarning_ISig_ 7 "TPMPressureWarning_NotAvailable" 6 "TPMPressureWarning_Error" 5 "TPMPressureWarning_Spare" 4 "TPMPressureWarning_ExtremeUnderPressure" 3 "TPMPressureWarning_UnderPressure" 2 "TPMPressureWarning_NoWarningPressure" 1 "TPMPressureWarning_OverPressure" 0 "TPMPressureWarning_ExtremeOverPressure" ;
VAL_ 1032 XRSLActive 3 "OffOn_NotAvailable" 2 "OffOn_Error" 1 "OffOn_On" 0 "OffOn_Off" ;
VAL_ 1032 Trailer1TPMPressureWarning_ISig_ 7 "TPMPressureWarning_NotAvailable" 6 "TPMPressureWarning_Error" 5 "TPMPressureWarning_Spare" 4 "TPMPressureWarning_ExtremeUnderPressure" 3 "TPMPressureWarning_UnderPressure" 2 "TPMPressureWarning_NoWarningPressure" 1 "TPMPressureWarning_OverPressure" 0 "TPMPressureWarning_ExtremeOverPressure" ;
VAL_ 1032 Trailer1TPMLeakageWarning_ISig_4 7 "TPMTireLeakageWarn_NotAvailable" 6 "TPMTireLeakageWarn_Error" 5 "TPMTireLeakageWarn_Spare3" 4 "TPMTireLeakageWarn_Spare2" 3 "TPMTireLeakageWarn_Spare1" 2 "TPMTireLeakageWarn_FastLeakageDetected" 1 "TPMTireLeakageWarn_SlowLeakageDetected" 0 "TPMTireLeakageWarn_NoLeakageDetected" ;
VAL_ 1032 LiftAxle1RequestResponse 15 "LiftAxleRequestResponse_NotAvailable" 14 "LiftAxleRequestResponse_Error" 13 "LiftAxleRequestResponse_Spare8" 12 "LiftAxleRequestResponse_Spare7" 11 "LiftAxleRequestResponse_Spare6" 10 "LiftAxleRequestResponse_Spare5" 9 "LiftAxleRequestResponse_Spare4" 8 "LiftAxleRequestResponse_Spare3" 7 "LiftAxleRequestResponse_Spare2" 6 "LiftAxleRequestResponse_Spare1" 5 "LiftAxleRequestResponse_LowerDeniedRASEC" 4 "LiftAxleRequestResponse_LiftDeniedVersatile" 3 "LiftAxleRequestResponse_LiftDeniedInterAxleClutchEngaged" 2 "LiftAxleRequestResponse_LiftDeniedRearOverload" 1 "LiftAxleRequestResponse_LiftDeniedFrontOverload" 0 "LiftAxleRequestResponse_NoIndication" ;
VAL_ 1032 TruckTPMPressureWarning_ISig_4 7 "TPMPressureWarning_NotAvailable" 6 "TPMPressureWarning_Error" 5 "TPMPressureWarning_Spare" 4 "TPMPressureWarning_ExtremeUnderPressure" 3 "TPMPressureWarning_UnderPressure" 2 "TPMPressureWarning_NoWarningPressure" 1 "TPMPressureWarning_OverPressure" 0 "TPMPressureWarning_ExtremeOverPressure" ;
VAL_ 1237 Trailer2TPMFailure_ISig_4 3 "InactiveActive_NotAvailable" 2 "InactiveActive_Error" 1 "InactiveActive_Active" 0 "InactiveActive_Inactive" ;
VAL_ 1237 TruckTPMTireInfo_Active_ISig_4 3 "TPMTireActive_NotAvailable" 2 "TPMTireActive_Error" 1 "TPMTireActive_TireActivePositioned" 0 "TPMTireActive_TireNotActive" ;
VAL_ 1237 TruckTPMFailure_ISig_4 3 "InactiveActive_NotAvailable" 2 "InactiveActive_Error" 1 "InactiveActive_Active" 0 "InactiveActive_Inactive" ;
VAL_ 1237 TruckTPMTireInfo_Battery_ISig_4 7 "TPMBatteryStatus_NotAvailable" 6 "TPMBatteryStatus_Error" 5 "TPMBatteryStatus_Spare3" 4 "TPMBatteryStatus_Spare2" 3 "TPMBatteryStatus_Spare1" 2 "TPMBatteryStatus_BatteryVeryLow" 1 "TPMBatteryStatus_BatteryLow" 0 "TPMBatteryStatus_BatteryOK" ;
VAL_ 1237 TPMTrailerPositionStat_ISig_4 3 "TrailerPositionsConfirmed_NotAvailable" 2 "TrailerPositionsConfirmed_Error" 1 "TPMTrailerPositionStat_TrailerPositionsConfirmed" 0 "TPMTrailerPositionStat_TrailerPositionsNotConfirmed" ;
VAL_ 1237 Trailer1TPMFailure_ISig_4 3 "InactiveActive_NotAvailable" 2 "InactiveActive_Error" 1 "InactiveActive_Active" 0 "InactiveActive_Inactive" ;
VAL_ 1237 TruckTPMTireInfo_PresWarn_ISig_4 7 "TPMPressureWarning_NotAvailable" 6 "TPMPressureWarning_Error" 5 "TPMPressureWarning_Spare" 4 "TPMPressureWarning_ExtremeUnderPressure" 3 "TPMPressureWarning_UnderPressure" 2 "TPMPressureWarning_NoWarningPressure" 1 "TPMPressureWarning_OverPressure" 0 "TPMPressureWarning_ExtremeOverPressure" ;
VAL_ 1237 TruckTPMTireInfo_LeakageWarn_ISi 7 "TPMTireLeakageWarn_NotAvailable" 6 "TPMTireLeakageWarn_Error" 5 "TPMTireLeakageWarn_Spare3" 4 "TPMTireLeakageWarn_Spare2" 3 "TPMTireLeakageWarn_Spare1" 2 "TPMTireLeakageWarn_FastLeakageDetected" 1 "TPMTireLeakageWarn_SlowLeakageDetected" 0 "TPMTireLeakageWarn_NoLeakageDetected" ;
VAL_ 1234 Trailer2TPMTireInfo_LeakageWarn_ 7 "TPMTireLeakageWarn_NotAvailable" 6 "TPMTireLeakageWarn_Error" 5 "TPMTireLeakageWarn_Spare3" 4 "TPMTireLeakageWarn_Spare2" 3 "TPMTireLeakageWarn_Spare1" 2 "TPMTireLeakageWarn_FastLeakageDetected" 1 "TPMTireLeakageWarn_SlowLeakageDetected" 0 "TPMTireLeakageWarn_NoLeakageDetected" ;
VAL_ 1234 Trailer2TPMTireInfo_PresWarn_ISi 7 "TPMPressureWarning_NotAvailable" 6 "TPMPressureWarning_Error" 5 "TPMPressureWarning_Spare" 4 "TPMPressureWarning_ExtremeUnderPressure" 3 "TPMPressureWarning_UnderPressure" 2 "TPMPressureWarning_NoWarningPressure" 1 "TPMPressureWarning_OverPressure" 0 "TPMPressureWarning_ExtremeOverPressure" ;
VAL_ 1234 Trailer2TPMTireInfo_Battery_ISig 7 "TPMBatteryStatus_NotAvailable" 6 "TPMBatteryStatus_Error" 5 "TPMBatteryStatus_Spare3" 4 "TPMBatteryStatus_Spare2" 3 "TPMBatteryStatus_Spare1" 2 "TPMBatteryStatus_BatteryVeryLow" 1 "TPMBatteryStatus_BatteryLow" 0 "TPMBatteryStatus_BatteryOK" ;
VAL_ 1234 Trailer2TPMTireInfo_Active_ISig_ 3 "TPMTireActive_NotAvailable" 2 "TPMTireActive_Error" 1 "TPMTireActive_TireActivePositioned" 0 "TPMTireActive_TireNotActive" ;
VAL_ 1231 Trailer1TPMTireInfo_Battery_ISig 7 "TPMBatteryStatus_NotAvailable" 6 "TPMBatteryStatus_Error" 5 "TPMBatteryStatus_Spare3" 4 "TPMBatteryStatus_Spare2" 3 "TPMBatteryStatus_Spare1" 2 "TPMBatteryStatus_BatteryVeryLow" 1 "TPMBatteryStatus_BatteryLow" 0 "TPMBatteryStatus_BatteryOK" ;
VAL_ 1231 Trailer1TPMTireInfo_PresWarn_ISi 7 "TPMPressureWarning_NotAvailable" 6 "TPMPressureWarning_Error" 5 "TPMPressureWarning_Spare" 4 "TPMPressureWarning_ExtremeUnderPressure" 3 "TPMPressureWarning_UnderPressure" 2 "TPMPressureWarning_NoWarningPressure" 1 "TPMPressureWarning_OverPressure" 0 "TPMPressureWarning_ExtremeOverPressure" ;
VAL_ 1231 Trailer1TPMTireInfo_LeakageWarn_ 7 "TPMTireLeakageWarn_NotAvailable" 6 "TPMTireLeakageWarn_Error" 5 "TPMTireLeakageWarn_Spare3" 4 "TPMTireLeakageWarn_Spare2" 3 "TPMTireLeakageWarn_Spare1" 2 "TPMTireLeakageWarn_FastLeakageDetected" 1 "TPMTireLeakageWarn_SlowLeakageDetected" 0 "TPMTireLeakageWarn_NoLeakageDetected" ;
VAL_ 1231 TPMPosOfWMResp_VehiclePos_ISig_4 7 "TPMVehiclePos_NotAvailable" 6 "TPMVehiclePos_Error" 5 "TPMVehiclePos_Trailer5Vehicle" 4 "TPMVehiclePos_Trailer4Vehicle" 3 "TPMVehiclePos_Trailer3Vehicle" 2 "TPMVehiclePos_Trailer2Vehicle" 1 "TPMVehiclePos_Trailer1Vehicle" 0 "TPMVehiclePos_TruckVehicle" ;
VAL_ 1231 Trailer1TPMTireInfo_Active_ISig_ 3 "TPMTireActive_NotAvailable" 2 "TPMTireActive_Error" 1 "TPMTireActive_TireActivePositioned" 0 "TPMTireActive_TireNotActive" ;
VAL_ 1231 TPMPosOfWMResp_Status_ISig_4 7 "TPMPosStatusResp_NotAvailable" 6 "TPMPosStatusResp_Error" 5 "TPMPosStatusResp_Spare2" 4 "TPMPosStatusResp_Spare1" 3 "TPMPosStatusResp_PositionedOK" 2 "TPMPosStatusResp_Timeout" 1 "TPMPosStatusResp_Progressing" 0 "TPMPosStatusResp_NotActive" ;
VAL_ 1403 TruckTPMAxlTireCfg_Axle2_ISig_4 7 "TPMAxleConfig_NotAvailable" 6 "TPMAxleConfig_Error" 5 "TPMAxleConfig_Spare" 4 "TPMAxleConfig_RearAxleWith4Tires" 3 "TPMAxleConfig_RearAxleWith2Tires" 2 "TPMAxleConfig_FrontAxleWith4Tires" 1 "TPMAxleConfig_FrontAxleWith2Tires" 0 "TPMAxleConfig_NotPresent" ;
VAL_ 1403 TruckTPMAxlTireCfg_Axle1_ISig_4 7 "TPMAxleConfig_NotAvailable" 6 "TPMAxleConfig_Error" 5 "TPMAxleConfig_Spare" 4 "TPMAxleConfig_RearAxleWith4Tires" 3 "TPMAxleConfig_RearAxleWith2Tires" 2 "TPMAxleConfig_FrontAxleWith4Tires" 1 "TPMAxleConfig_FrontAxleWith2Tires" 0 "TPMAxleConfig_NotPresent" ;
VAL_ 1403 TruckTPMAxlTireCfg_Axle5_ISig_4 7 "TPMAxleConfig_NotAvailable" 6 "TPMAxleConfig_Error" 5 "TPMAxleConfig_Spare" 4 "TPMAxleConfig_RearAxleWith4Tires" 3 "TPMAxleConfig_RearAxleWith2Tires" 2 "TPMAxleConfig_FrontAxleWith4Tires" 1 "TPMAxleConfig_FrontAxleWith2Tires" 0 "TPMAxleConfig_NotPresent" ;
VAL_ 1403 TruckTPMAxlTireCfg_Axle4_ISig_4 7 "TPMAxleConfig_NotAvailable" 6 "TPMAxleConfig_Error" 5 "TPMAxleConfig_Spare" 4 "TPMAxleConfig_RearAxleWith4Tires" 3 "TPMAxleConfig_RearAxleWith2Tires" 2 "TPMAxleConfig_FrontAxleWith4Tires" 1 "TPMAxleConfig_FrontAxleWith2Tires" 0 "TPMAxleConfig_NotPresent" ;
VAL_ 1403 TruckTPMThresCfg_AxleNr_ISig_4 7 "TPMAxleNr_NotAvailable" 6 "TPMAxleNr_Error" 5 "TPMAxleNr_Axle5" 4 "TPMAxleNr_Axle4" 3 "TPMAxleNr_Axle3" 2 "TPMAxleNr_Axle2" 1 "TPMAxleNr_Axle1" 0 "TPMAxleNr_NoRequest" ;
VAL_ 1403 TruckTPMAxlTireCfg_Axle3_ISig_4 7 "TPMAxleConfig_NotAvailable" 6 "TPMAxleConfig_Error" 5 "TPMAxleConfig_Spare" 4 "TPMAxleConfig_RearAxleWith4Tires" 3 "TPMAxleConfig_RearAxleWith2Tires" 2 "TPMAxleConfig_FrontAxleWith4Tires" 1 "TPMAxleConfig_FrontAxleWith2Tires" 0 "TPMAxleConfig_NotPresent" ;
VAL_ 1402 Trailer2TPMType_ISig_4 3 "TPMTrailerType_NotAvailable" 2 "TPMTrailerType_Error" 1 "TPMTrailerType_ISO11992Trailer" 0 "TPMTrailerType_SKFWirelessTrailer" ;
VAL_ 1402 Trailer2TPMAxlTireCfg_Axle1_ISig 7 "TPMAxleConfig_NotAvailable" 6 "TPMAxleConfig_Error" 5 "TPMAxleConfig_Spare" 4 "TPMAxleConfig_RearAxleWith4Tires" 3 "TPMAxleConfig_RearAxleWith2Tires" 2 "TPMAxleConfig_FrontAxleWith4Tires" 1 "TPMAxleConfig_FrontAxleWith2Tires" 0 "TPMAxleConfig_NotPresent" ;
VAL_ 1402 Trailer2TPMAxlTireCfg_Axle3_ISig 7 "TPMAxleConfig_NotAvailable" 6 "TPMAxleConfig_Error" 5 "TPMAxleConfig_Spare" 4 "TPMAxleConfig_RearAxleWith4Tires" 3 "TPMAxleConfig_RearAxleWith2Tires" 2 "TPMAxleConfig_FrontAxleWith4Tires" 1 "TPMAxleConfig_FrontAxleWith2Tires" 0 "TPMAxleConfig_NotPresent" ;
VAL_ 1402 Trailer2TPMAxlTireCfg_Axle2_ISig 7 "TPMAxleConfig_NotAvailable" 6 "TPMAxleConfig_Error" 5 "TPMAxleConfig_Spare" 4 "TPMAxleConfig_RearAxleWith4Tires" 3 "TPMAxleConfig_RearAxleWith2Tires" 2 "TPMAxleConfig_FrontAxleWith4Tires" 1 "TPMAxleConfig_FrontAxleWith2Tires" 0 "TPMAxleConfig_NotPresent" ;
VAL_ 1402 Trailer2TPMAxlTireCfg_Axle5_ISig 7 "TPMAxleConfig_NotAvailable" 6 "TPMAxleConfig_Error" 5 "TPMAxleConfig_Spare" 4 "TPMAxleConfig_RearAxleWith4Tires" 3 "TPMAxleConfig_RearAxleWith2Tires" 2 "TPMAxleConfig_FrontAxleWith4Tires" 1 "TPMAxleConfig_FrontAxleWith2Tires" 0 "TPMAxleConfig_NotPresent" ;
VAL_ 1402 Trailer2TPMAxlTireCfg_Axle4_ISig 7 "TPMAxleConfig_NotAvailable" 6 "TPMAxleConfig_Error" 5 "TPMAxleConfig_Spare" 4 "TPMAxleConfig_RearAxleWith4Tires" 3 "TPMAxleConfig_RearAxleWith2Tires" 2 "TPMAxleConfig_FrontAxleWith4Tires" 1 "TPMAxleConfig_FrontAxleWith2Tires" 0 "TPMAxleConfig_NotPresent" ;
VAL_ 1402 Trailer2TPMThresCfg_AxleNr_ISig_ 7 "TPMAxleNr_NotAvailable" 6 "TPMAxleNr_Error" 5 "TPMAxleNr_Axle5" 4 "TPMAxleNr_Axle4" 3 "TPMAxleNr_Axle3" 2 "TPMAxleNr_Axle2" 1 "TPMAxleNr_Axle1" 0 "TPMAxleNr_NoRequest" ;
VAL_ 1401 Trailer1TPMAxlTireCfg_Axle1_ISig 7 "TPMAxleConfig_NotAvailable" 6 "TPMAxleConfig_Error" 5 "TPMAxleConfig_Spare" 4 "TPMAxleConfig_RearAxleWith4Tires" 3 "TPMAxleConfig_RearAxleWith2Tires" 2 "TPMAxleConfig_FrontAxleWith4Tires" 1 "TPMAxleConfig_FrontAxleWith2Tires" 0 "TPMAxleConfig_NotPresent" ;
VAL_ 1401 Trailer1TPMAxlTireCfg_Axle2_ISig 7 "TPMAxleConfig_NotAvailable" 6 "TPMAxleConfig_Error" 5 "TPMAxleConfig_Spare" 4 "TPMAxleConfig_RearAxleWith4Tires" 3 "TPMAxleConfig_RearAxleWith2Tires" 2 "TPMAxleConfig_FrontAxleWith4Tires" 1 "TPMAxleConfig_FrontAxleWith2Tires" 0 "TPMAxleConfig_NotPresent" ;
VAL_ 1401 Trailer1TPMAxlTireCfg_Axle5_ISig 7 "TPMAxleConfig_NotAvailable" 6 "TPMAxleConfig_Error" 5 "TPMAxleConfig_Spare" 4 "TPMAxleConfig_RearAxleWith4Tires" 3 "TPMAxleConfig_RearAxleWith2Tires" 2 "TPMAxleConfig_FrontAxleWith4Tires" 1 "TPMAxleConfig_FrontAxleWith2Tires" 0 "TPMAxleConfig_NotPresent" ;
VAL_ 1401 Trailer1TPMType_ISig_4 3 "TPMTrailerType_NotAvailable" 2 "TPMTrailerType_Error" 1 "TPMTrailerType_ISO11992Trailer" 0 "TPMTrailerType_SKFWirelessTrailer" ;
VAL_ 1401 Trailer1TPMThresCfg_AxleNr_ISig_ 7 "TPMAxleNr_NotAvailable" 6 "TPMAxleNr_Error" 5 "TPMAxleNr_Axle5" 4 "TPMAxleNr_Axle4" 3 "TPMAxleNr_Axle3" 2 "TPMAxleNr_Axle2" 1 "TPMAxleNr_Axle1" 0 "TPMAxleNr_NoRequest" ;
VAL_ 1401 Trailer1TPMAxlTireCfg_Axle4_ISig 7 "TPMAxleConfig_NotAvailable" 6 "TPMAxleConfig_Error" 5 "TPMAxleConfig_Spare" 4 "TPMAxleConfig_RearAxleWith4Tires" 3 "TPMAxleConfig_RearAxleWith2Tires" 2 "TPMAxleConfig_FrontAxleWith4Tires" 1 "TPMAxleConfig_FrontAxleWith2Tires" 0 "TPMAxleConfig_NotPresent" ;
VAL_ 1401 Trailer1TPMAxlTireCfg_Axle3_ISig 7 "TPMAxleConfig_NotAvailable" 6 "TPMAxleConfig_Error" 5 "TPMAxleConfig_Spare" 4 "TPMAxleConfig_RearAxleWith4Tires" 3 "TPMAxleConfig_RearAxleWith2Tires" 2 "TPMAxleConfig_FrontAxleWith4Tires" 1 "TPMAxleConfig_FrontAxleWith2Tires" 0 "TPMAxleConfig_NotPresent" ;
SIG_GROUP_ 1380 Trail4Type_sg_ISig_4 1 : Trail4Type_Towing_ISig_4 Trail4Type_TrailType_ISig_4;
SIG_GROUP_ 1380 Trail5Type_sg_ISig_4 1 : Trail5Type_TrailType_ISig_4 Trail5Type_Towing_ISig_4;
SIG_GROUP_ 1380 Trail3Type_sg_ISig_4 1 : Trail3Type_TrailType_ISig_4 Trail3Type_Towing_ISig_4;
SIG_GROUP_ 1378 Trail1Type_sg_ISig_4 1 : Trail1Type_Towing_ISig_4 Trail1Type_TrailType_ISig_4;
SIG_GROUP_ 1378 Trail2Type_sg_ISig_4 1 : Trail2Type_Towing_ISig_4 Trail2Type_TrailType_ISig_4;
SIG_GROUP_ 1370 FrontConspicLamp_stat_sg_ISig_4 1 : FrontConspicLamp_stat_HiLeft_ISi FrontConspicLamp_stat_LoRight_IS FrontConspicLamp_stat_LoLeft_ISi FrontConspicLamp_stat_HiRight_IS;
SIG_GROUP_ 830 InstFuel_sg 1 : InstFuel_ConsumpValue InstFuel_VehicleMoving;
SIG_GROUP_ 1071 EngOvrrideCtrlStat_sg 1 : EngOvrrideCtrlStat_FireTruckMode EngOvrrideCtrlStat_StartOvrrMode EngOvrrideCtrlStat_ProtOvrrMode;
SIG_GROUP_ 1035 FPBRMMIStat_sg_ISig_4 1 : FPBRMMIStat_FPBRChangeAck_ISig_4 FPBRMMIStat_FPBRStatusInd_ISig_4;
SIG_GROUP_ 1237 TruckTPMTireInfo_sg_ISig_4 1 : TruckTPMTireInfo_Active_ISig_4 TruckTPMTireInfo_TireId_ISig_4 TruckTPMTireInfo_Battery_ISig_4 TruckTPMTireInfo_Temperature_ISi TruckTPMTireInfo_RefPres_ISig_4 TruckTPMTireInfo_Pressure_ISig_4 TruckTPMTireInfo_PresWarn_ISig_4 TruckTPMTireInfo_LeakageWarn_ISi;
SIG_GROUP_ 1234 Trailer2TPMTireInfo_sg_ISig_4 1 : Trailer2TPMTireInfo_LeakageWarn_ Trailer2TPMTireInfo_RefPres_ISig Trailer2TPMTireInfo_PresWarn_ISi Trailer2TPMTireInfo_Pressure_ISi Trailer2TPMTireInfo_Temperature_ Trailer2TPMTireInfo_TireId_ISig_ Trailer2TPMTireInfo_Battery_ISig Trailer2TPMTireInfo_Active_ISig_;
SIG_GROUP_ 1231 TPMPosOfWMResp_sg_ISig_4 1 : TPMPosOfWMResp_VehiclePos_ISig_4 TPMPosOfWMResp_Status_ISig_4 TPMPosOfWMResp_TireId_ISig_4;
SIG_GROUP_ 1231 Trailer1TPMTireInfo_sg_ISig_4 1 : Trailer1TPMTireInfo_Battery_ISig Trailer1TPMTireInfo_Pressure_ISi Trailer1TPMTireInfo_PresWarn_ISi Trailer1TPMTireInfo_LeakageWarn_ Trailer1TPMTireInfo_TireId_ISig_ Trailer1TPMTireInfo_RefPres_ISig Trailer1TPMTireInfo_Temperature_ Trailer1TPMTireInfo_Active_ISig_;
SIG_GROUP_ 1403 TruckTPMAxlTireCfg_sg_ISig_4 1 : TruckTPMAxlTireCfg_Axle2_ISig_4 TruckTPMAxlTireCfg_Axle1_ISig_4 TruckTPMAxlTireCfg_Axle5_ISig_4 TruckTPMAxlTireCfg_Axle4_ISig_4 TruckTPMAxlTireCfg_Axle3_ISig_4;
SIG_GROUP_ 1403 TruckTPMThresCfg_sg_ISig_4 1 : TruckTPMThresCfg_OverPres_ISig_4 TruckTPMThresCfg_ExtUnderPres_IS TruckTPMThresCfg_AxleNr_ISig_4 TruckTPMThresCfg_UnderPres_ISig_ TruckTPMThresCfg_ExtOverPres_ISi;
SIG_GROUP_ 1402 Trailer2TPMAxlTireCfg_sg_ISig_4 1 : Trailer2TPMAxlTireCfg_Axle1_ISig Trailer2TPMAxlTireCfg_Axle3_ISig Trailer2TPMAxlTireCfg_Axle2_ISig Trailer2TPMAxlTireCfg_Axle5_ISig Trailer2TPMAxlTireCfg_Axle4_ISig;
SIG_GROUP_ 1402 Trailer2TPMThresCfg_sg_ISig_4 1 : Trailer2TPMThresCfg_OverPres_ISi Trailer2TPMThresCfg_AxleNr_ISig_ Trailer2TPMThresCfg_ExtOverPres_ Trailer2TPMThresCfg_UnderPres_IS Trailer2TPMThresCfg_ExtUnderPres;
SIG_GROUP_ 1401 Trailer1TPMAxlTireCfg_sg_ISig_4 1 : Trailer1TPMAxlTireCfg_Axle1_ISig Trailer1TPMAxlTireCfg_Axle2_ISig Trailer1TPMAxlTireCfg_Axle5_ISig Trailer1TPMAxlTireCfg_Axle4_ISig Trailer1TPMAxlTireCfg_Axle3_ISig;
SIG_GROUP_ 1401 Trailer1TPMThresCfg_sg_ISig_4 1 : Trailer1TPMThresCfg_ExtOverPres_ Trailer1TPMThresCfg_OverPres_ISi Trailer1TPMThresCfg_UnderPres_IS Trailer1TPMThresCfg_ExtUnderPres Trailer1TPMThresCfg_AxleNr_ISig_;
